VERSION ""

NS_ :

BS_:

BU_: APIM_CISM FCIMB RACM_RCIM DSP WCM DACMC HUD_ADV TRM_ITRM ACM GWM _delete APIM IPC GENERIC TSTR

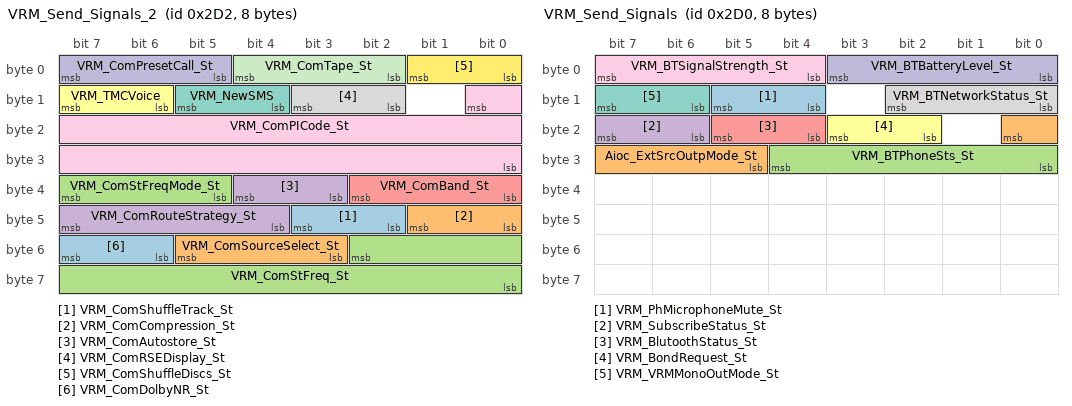
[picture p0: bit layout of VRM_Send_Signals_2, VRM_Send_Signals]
BO_ 722 VRM_Send_Signals_2: 8 APIM
 SG_ VRM_ComShuffleTrack_St : 43|2@0+ (1,0) [0|3] "SED"  GENERIC
 SG_ VRM_ComCompression_St : 41|2@0+ (1,0) [0|3] "SED"  GENERIC
 SG_ VRM_ComStFreqMode_St : 39|3@0+ (1,0) [0|7] "SED"  GENERIC
 SG_ VRM_ComAutostore_St : 36|2@0+ (1,0) [0|3] "SED"  GENERIC
 SG_ VRM_ComBand_St : 34|3@0+ (1,0) [0|7] "SED"  GENERIC
 SG_ VRM_TMCVoice : 15|2@0+ (1,0) [0|3] "SED"  GENERIC
 SG_ VRM_NewSMS : 13|2@0+ (1,0) [0|3] "SED"  HUD_ADV,IPC
 SG_ VRM_ComRSEDisplay_St : 11|2@0+ (1,0) [0|3] "SED"  GENERIC
 SG_ VRM_ComPICode_St : 8|17@0+ (1,0) [0|65535] "unitless"  GENERIC
 SG_ VRM_ComPresetCall_St : 7|3@0+ (1,0) [0|7] "SED"  GENERIC
 SG_ VRM_ComTape_St : 4|3@0+ (1,0) [0|7] "SED"  GENERIC
 SG_ VRM_ComShuffleDiscs_St : 1|2@0+ (1,0) [0|3] "SED"  GENERIC
 SG_ VRM_ComDolbyNR_St : 55|2@0+ (1,0) [0|3] "SED"  GENERIC
 SG_ VRM_ComSourceSelect_St : 53|3@0+ (1,0) [0|7] "SED"  GENERIC
 SG_ VRM_ComStFreq_St : 50|11@0+ (1,0) [0|1557] "unitless"  GENERIC
 SG_ VRM_ComRouteStrategy_St : 47|4@0+ (1,0) [0|15] "SED"  GENERIC

BO_ 721 VRM_Send_Signals_1: 8 APIM
 SG_ VRM_BTDefaultPhone_St : 63|4@0+ (1,0) [0|15] "SED"  IPC
 SG_ VRM_DetourUnit_st : 59|2@0+ (1,0) [0|3] "SED"  GENERIC
 SG_ VRM_Zoom_Option_St : 57|2@0+ (1,0) [0|3] "SED"  GENERIC
 SG_ VRM_ComBTDTMFTone_St : 55|4@0+ (1,0) [0|15] "SED"  GENERIC
 SG_ VRM_SuggestedRoute_St : 51|2@0+ (1,0) [0|3] "SED"  GENERIC
 SG_ VRM_ComDelWaypoint_St : 49|2@0+ (1,0) [0|3] "SED"  GENERIC
 SG_ VRM_ComSelectDisc_St : 47|3@0+ (1,0) [0|7] "SED"  GENERIC
 SG_ VRM_ComTelService_St : 44|3@0+ (1,0) [0|7] "SED"  GENERIC
 SG_ VRM_ComDestHome_St : 41|2@0+ (1,0) [0|3] "SED"  GENERIC
 SG_ VRM_ComSelectTrack_St : 39|7@0+ (1,0) [0|100] "unitless"  GENERIC
 SG_ VRM_ComShowNavInfo_St : 31|3@0+ (1,0) [0|7] "SED"  GENERIC
 SG_ VRM_VoiceRecStatus_St : 28|3@0+ (1,0) [0|7] "SED"  GENERIC
 SG_ VRM_ComSelTrackSource_St : 25|2@0+ (1,0) [0|3] "SED"  GENERIC
 SG_ VRM_ComDetour_St : 23|4@0+ (1,0) [0|15] "SED"  GENERIC
 SG_ VRM_ComDisplay_St : 19|3@0+ (1,0) [0|7] "SED"  GENERIC
 SG_ VRM_ComDynamicGuidande_St : 15|2@0+ (1,0) [0|3] "SED"  GENERIC
 SG_ VRM_ComZoom_St : 12|5@0+ (1,0) [0|31] "SED"  GENERIC
 SG_ VRM_ComCallControl_St : 7|3@0+ (1,0) [0|7] "SED"  GENERIC
 SG_ VRM_ComGuidance_St : 4|3@0+ (1,0) [0|7] "SED"  GENERIC
 SG_ VRM_ComTrafficInfDsp_St : 1|2@0+ (1,0) [0|3] "SED"  GENERIC

BO_ 720 VRM_Send_Signals: 8 APIM
 SG_ VRM_PhMicrophoneMute_St : 13|2@0+ (1,0) [0|3] "SED"  IPC
 SG_ Aioc_ExtSrcOutpMode_St : 16|4@0+ (1,0) [0|15] "SED"  GENERIC
 SG_ VRM_BTPhoneSts_St : 28|5@0+ (1,0) [0|31] "SED"  GWM,HUD_ADV,IPC
 SG_ VRM_SubscribeStatus_St : 23|2@0+ (1,0) [0|3] "SED"  GENERIC
 SG_ VRM_BlutoothStatus_St : 21|2@0+ (1,0) [0|3] "SED"  IPC
 SG_ VRM_BondRequest_St : 19|2@0+ (1,0) [0|3] "SED"  GENERIC
 SG_ VRM_VRMMonoOutMode_St : 15|2@0+ (1,0) [0|3] "SED"  GENERIC
 SG_ VRM_BTNetworkStatus_St : 10|3@0+ (1,0) [0|7] "unitless"  IPC
 SG_ VRM_BTSignalStrength_St : 7|4@0+ (1,0) [0|15] "unitless"  IPC
 SG_ VRM_BTBatteryLevel_St : 3|4@0+ (1,0) [0|15] "unitless"  IPC

BO_ 470 VRM_Response_Signals: 8 APIM
 SG_ VRM_BTIncomingCall_Rsp : 47|2@0+ (1,0) [0|3] "SED"  HUD_ADV,IPC
 SG_ VRM_BTEndTelService_Rsp : 37|2@0+ (1,0) [0|3] "SED"  HUD_ADV,IPC

BO_ 1978 TesterPhysicalResHUD_ADV: 8 HUD_ADV
 SG_ TesterPhysicalResHUD_ADV : 7|64@0+ (1,0) [0|1.84467E+019] "unitless"  TSTR

BO_ 1970 TesterPhysicalReqHUD_ADV: 8 TSTR
 SG_ TesterPhysicalReqHUD_ADV : 7|64@0+ (1,0) [0|1.84467E+019] "unitless"  HUD_ADV

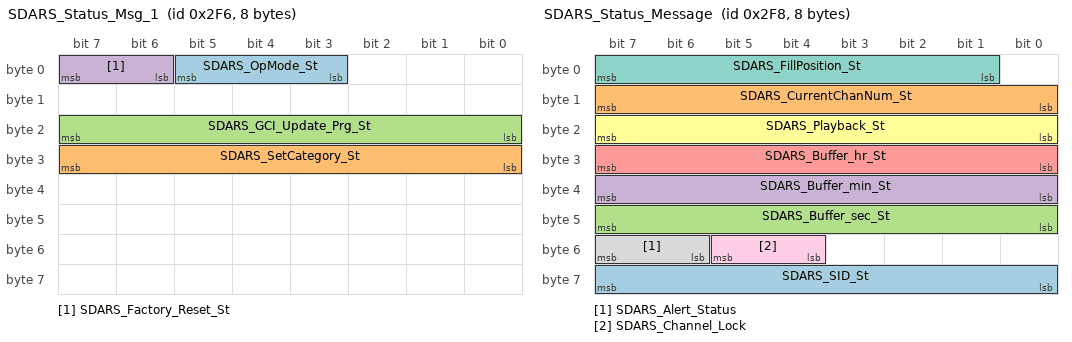
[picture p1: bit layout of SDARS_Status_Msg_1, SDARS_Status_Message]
BO_ 758 SDARS_Status_Msg_1: 8 ACM
 SG_ SDARS_OpMode_St : 5|3@0+ (1,0) [0|7] "SED"  APIM,IPC
 SG_ SDARS_SetCategory_St : 31|8@0+ (1,0) [0|255] "unitless"  APIM,IPC
 SG_ SDARS_GCI_Update_Prg_St : 23|8@0+ (1,0) [0|255] "unitless"  RACM_RCIM,APIM,IPC
 SG_ SDARS_Factory_Reset_St : 7|2@0+ (1,0) [0|3] "SED"  APIM,IPC

BO_ 760 SDARS_Status_Message: 8 ACM
 SG_ SDARS_SID_St : 63|8@0+ (1,0) [0|255] "unitless"  RACM_RCIM,APIM
 SG_ SDARS_CurrentChanNum_St : 15|8@0+ (1,0) [0|255] "unitless"  APIM,RACM_RCIM,IPC
 SG_ SDARS_Buffer_sec_St : 47|8@0+ (1,0) [0|255] "unitless"  APIM,IPC
 SG_ SDARS_Buffer_min_St : 39|8@0+ (1,0) [0|255] "unitless"  APIM,IPC
 SG_ SDARS_Buffer_hr_St : 31|8@0+ (1,0) [0|255] "unitless"  APIM,IPC
 SG_ SDARS_Playback_St : 23|8@0+ (1,0) [0|255] "unitless"  APIM,IPC
 SG_ SDARS_FillPosition_St : 7|7@0+ (1,0) [0|127] "unitless"  APIM,IPC
 SG_ SDARS_Alert_Status : 55|2@0+ (1,0) [0|3] "SED"  APIM,IPC
 SG_ SDARS_Channel_Lock : 53|2@0+ (1,0) [0|3] "SED"  RACM_RCIM,APIM,IPC

BO_ 705 SDARS_RDISP_WORD_Tx: 8 ACM
 SG_ SDARS_RDISP_WORD_Tx : 7|64@0+ (1,0) [0|1.84467440737096E+019] "unitless"  APIM

BO_ 692 AUDIO_RDISP_WORD_Tx: 8 ACM
 SG_ AUDIO_RDISP_WORD_Tx : 7|64@0+ (1,0) [0|1.84467440737096E+019] "unitless"  APIM

BO_ 1837 TesterPhysicalResWCM: 8 WCM
 SG_ TesterPhysicalResWCM : 7|64@0+ (1,0) [0|1.84467E+019] "unitless"  TSTR

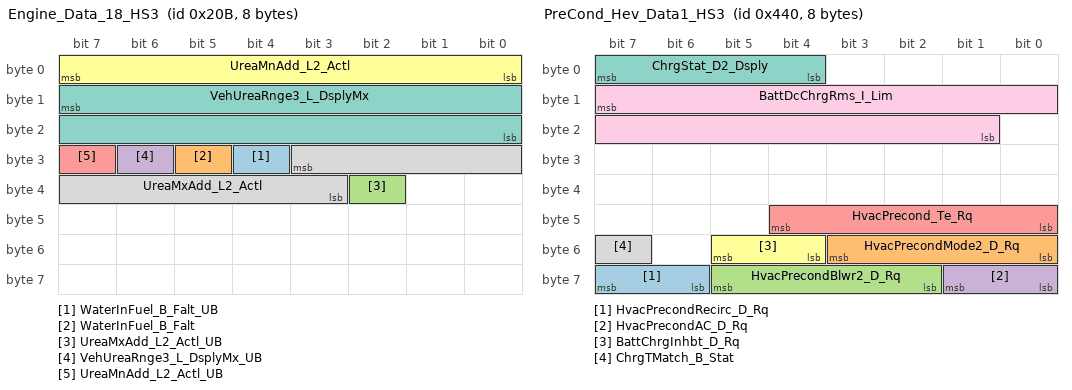
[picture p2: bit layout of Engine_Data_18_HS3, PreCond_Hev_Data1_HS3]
BO_ 523 Engine_Data_18_HS3: 8 GWM
 SG_ WaterInFuel_B_Falt_UB : 28|1@0+ (1,0) [0|1] "SED"  IPC
 SG_ WaterInFuel_B_Falt : 29|1@0+ (1,0) [0|1] "SED"  IPC
 SG_ UreaMxAdd_L2_Actl_UB : 34|1@0+ (1,0) [0|1] "SED"  IPC
 SG_ VehUreaRnge3_L_DsplyMx_UB : 30|1@0+ (1,0) [0|1] "SED"  IPC
 SG_ UreaMnAdd_L2_Actl_UB : 31|1@0+ (1,0) [0|1] "SED"  IPC
 SG_ UreaMnAdd_L2_Actl : 7|8@0+ (0.1,0) [0|25.4] "litre"  IPC
 SG_ VehUreaRnge3_L_DsplyMx : 15|16@0+ (1,0) [0|65535] "unitless"  IPC
 SG_ UreaMxAdd_L2_Actl : 27|9@0+ (0.1,0) [0|51] "litre"  IPC

BO_ 942 ParkAid_Data2_HS3: 8 GWM
 SG_ ApaDrvRq2MsgTxt_D_Rq : 55|4@0+ (1,0) [0|15] "SED"  APIM_CISM,APIM
 SG_ ApaDrvRq1MsgTxt_D_Rq : 42|3@0+ (1,0) [0|7] "SED"  APIM_CISM,APIM
 SG_ ApaSys_D2_Stat : 35|4@0+ (1,0) [0|15] "SED"  APIM_CISM,APIM
 SG_ ApaSlotTrgt_D_Stat : 39|4@0+ (1,0) [0|15] "SED"  APIM_CISM,APIM
 SG_ ApaSlotOption_B_Avail : 43|1@0+ (1,0) [0|1] "SED"  APIM_CISM,APIM
 SG_ ApaSlotAlrtSet_B_Stat : 44|1@0+ (1,0) [0|1] "SED"  APIM_CISM,APIM
 SG_ ApaSlotAlrt_B_Rq : 45|1@0+ (1,0) [0|1] "SED"  APIM_CISM,APIM
 SG_ ApaRmtFeatSel_B_Avail : 46|1@0+ (1,0) [0|1] "SED"  APIM_CISM,APIM
 SG_ ApaParkOutSel_B_Avail : 47|1@0+ (1,0) [0|1] "SED"  APIM_CISM,APIM
 SG_ ApaParkInSel_B_Avail : 24|1@0+ (1,0) [0|1] "SED"  APIM_CISM,APIM
 SG_ ApaMsgTxt_D2_Stat : 28|4@0+ (1,0) [0|15] "SED"  APIM_CISM,APIM
 SG_ ApaDynmcSlot_B_Stat : 29|1@0+ (1,0) [0|1] "SED"  APIM_CISM,APIM
 SG_ ApaDisplayMode_D_Stat : 31|2@0+ (1,0) [0|3] "SED"  APIM_CISM,APIM
 SG_ ApaControlMode_D_Stat : 16|1@0+ (1,0) [0|1] "SED"  APIM_CISM,APIM
 SG_ PrkAidAcsyRear_D_Stat : 18|2@0+ (1,0) [0|3] "SED"  APIM_CISM,IPC
 SG_ PrkAidAcsyFront_D_Stat : 20|2@0+ (1,0) [0|3] "SED"  APIM_CISM,IPC
 SG_ PrkAidRdiusRight_L_Dsply : 15|8@0+ (1,0) [0|255] "unitless"  APIM_CISM,APIM
 SG_ PrkAidRdiusLeft_L_Dsply : 7|8@0+ (1,0) [0|255] "unitless"  APIM_CISM,APIM
 SG_ PrkAidDrvDir_D_Stat : 23|3@0+ (1,0) [0|7] "SED"  APIM_CISM,APIM

BO_ 634 GWM_Send_Signals_7_HS3: 8 GWM
 SG_ EngAirFiltMsgTxt_D_Rq_UB : 56|1@0+ (1,0) [0|1] "SED"  IPC
 SG_ EngAirFiltMsgTxt_D_Rq : 59|3@0+ (1,0) [0|7] "SED"  IPC
 SG_ AutoHoldSwMde_B_Ind_UB : 62|1@0+ (1,0) [0|1] "SED"  APIM_CISM,APIM
 SG_ AutoHoldSwMde_B_Ind : 63|1@0+ (1,0) [0|1] "SED"  APIM_CISM,APIM
 SG_ Ccd_B_Falt_UB : 24|1@0+ (1,0) [0|1] "SED"  IPC
 SG_ Ccd_B_Falt : 25|1@0+ (1,0) [0|1] "SED"  IPC
 SG_ RearDiffLckLamp_D_Rq3_UB : 47|1@0+ (1,0) [0|1] "SED"  IPC
 SG_ AwdLckLamp_D_Rq_UB : 12|1@0+ (1,0) [0|1] "SED"  IPC
 SG_ RearDiffLckLamp_D_Rq3 : 61|2@0+ (1,0) [0|3] "SED"  IPC
 SG_ AwdLckLamp_D_Rq : 14|2@0+ (1,0) [0|3] "SED"  IPC
 SG_ AutoTowAllw_D_StatMnu_UB : 26|1@0+ (1,0) [0|1] "SED"  IPC
 SG_ AutoTowAllw_D_StatMnu : 28|2@0+ (1,0) [0|3] "SED"  IPC
 SG_ AutoTowActv_B_Stat : 30|1@0+ (1,0) [0|1] "SED"  DACMC,IPC
 SG_ AutoTowActv_B_Stat_UB : 29|1@0+ (1,0) [0|1] "SED"  IPC
 SG_ LdwChime_B_Rq_UB : 5|1@0+ (1,0) [0|1] "SED"  IPC
 SG_ HdcOn_B_Ind : 7|1@0+ (1,0) [0|1] "SED"  IPC
 SG_ HdcOn_B_Ind_UB : 6|1@0+ (1,0) [0|1] "SED"  IPC
 SG_ SuspVLimMsgTxt_B_Rq_UB : 4|1@0+ (1,0) [0|1] "SED"  IPC
 SG_ SuspVlimMsgTxt_B_Rq : 31|1@0+ (1,0) [0|1] "SED"  IPC
 SG_ EngExhMdeQuiet_D2_Stat_UB : 0|1@0+ (1,0) [0|1] "SED"  APIM_CISM,APIM,IPC,ACM
 SG_ EngExhMdeQuiet_D2_Stat : 3|3@0+ (1,0) [0|7] "SED"  APIM_CISM,APIM,IPC,ACM
 SG_ ChrgCrdLck_D_Falt_UB : 44|1@0+ (1,0) [0|1] "SED"  APIM_CISM,APIM,IPC
 SG_ LdwChime_B_Rq : 15|1@0+ (1,0) [0|1] "SED"  IPC
 SG_ ChrgCrdLck_D_Falt : 46|2@0+ (1,0) [0|3] "SED"  APIM_CISM,APIM,IPC

BO_ 1088 PreCond_Hev_Data1_HS3: 8 GWM
 SG_ HvacPrecondRecirc_D_Rq : 63|2@0+ (1,0) [0|3] "SED"  GENERIC
 SG_ HvacPrecondMode2_D_Rq : 51|4@0+ (1,0) [0|15] "SED"  GENERIC
 SG_ HvacPrecondBlwr2_D_Rq : 61|4@0+ (1,0) [0|15] "SED"  GENERIC
 SG_ HvacPrecondAC_D_Rq : 57|2@0+ (1,0) [0|3] "SED"  GENERIC
 SG_ HvacPrecond_Te_Rq : 44|5@0+ (0.5,14.5) [14.5|30] "deg C"  GENERIC
 SG_ BattChrgInhbt_D_Rq : 53|2@0+ (1,0) [0|3] "SED"  GENERIC
 SG_ ChrgStat_D2_Dsply : 7|4@0+ (1,0) [0|15] "SED"  APIM_CISM,APIM,IPC
 SG_ ChrgTMatch_B_Stat : 55|1@0+ (1,0) [0|1] "SED"  IPC
 SG_ BattDcChrgRms_I_Lim : 15|15@0+ (0.05,0) [0|1638.25] "ampere"  GENERIC

BO_ 706 SDARS_MC_WORD_Tx: 8 ACM
 SG_ SDARS_MC_WORD_Tx : 7|64@0+ (1,0) [0|1.84467440737096E+019] "unitless"  IPC

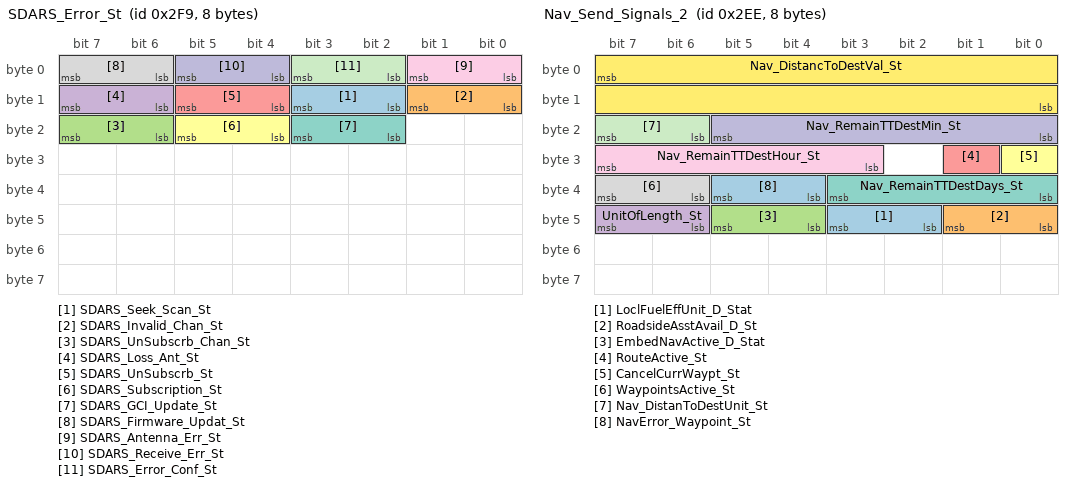
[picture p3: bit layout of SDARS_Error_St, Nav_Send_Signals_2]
BO_ 761 SDARS_Error_St: 8 ACM
 SG_ SDARS_Seek_Scan_St : 11|2@0+ (1,0) [0|3] "SED"  RACM_RCIM,APIM,IPC
 SG_ SDARS_Invalid_Chan_St : 9|2@0+ (1,0) [0|3] "SED"  RACM_RCIM,APIM,IPC
 SG_ SDARS_UnSubscrb_Chan_St : 23|2@0+ (1,0) [0|3] "SED"  RACM_RCIM,APIM,IPC
 SG_ SDARS_Loss_Ant_St : 15|2@0+ (1,0) [0|3] "SED"  APIM,RACM_RCIM,IPC
 SG_ SDARS_UnSubscrb_St : 13|2@0+ (1,0) [0|3] "SED"  RACM_RCIM,APIM,IPC
 SG_ SDARS_Subscription_St : 21|2@0+ (1,0) [0|3] "SED"  RACM_RCIM,APIM,IPC
 SG_ SDARS_GCI_Update_St : 19|2@0+ (1,0) [0|3] "SED"  RACM_RCIM,APIM,IPC
 SG_ SDARS_Firmware_Updat_St : 7|2@0+ (1,0) [0|3] "SED"  RACM_RCIM,APIM,IPC
 SG_ SDARS_Antenna_Err_St : 1|2@0+ (1,0) [0|3] "SED"  RACM_RCIM,APIM,IPC
 SG_ SDARS_Receive_Err_St : 5|2@0+ (1,0) [0|3] "SED"  RACM_RCIM,APIM,IPC
 SG_ SDARS_Error_Conf_St : 3|2@0+ (1,0) [0|3] "SED"  RACM_RCIM,APIM,IPC

BO_ 694 PHONE_MC_WORD_Tx: 8 APIM
 SG_ PHONE_MC_WORD_Tx : 7|64@0+ (1,0) [0|1.84467440737096E+019] "unitless"  IPC

BO_ 750 Nav_Send_Signals_2: 8 APIM
 SG_ LoclFuelEffUnit_D_Stat : 43|2@0+ (1,0) [0|3] "SED"  IPC
 SG_ RoadsideAsstAvail_D_St : 41|2@0+ (1,0) [0|3] "SED"  IPC
 SG_ EmbedNavActive_D_Stat : 45|2@0+ (1,0) [0|3] "SED"  IPC
 SG_ UnitOfLength_St : 47|2@0+ (1,0) [0|3] "SED"  IPC
 SG_ RouteActive_St : 25|1@0+ (1,0) [0|1] "SED"  HUD_ADV,IPC
 SG_ CancelCurrWaypt_St : 24|1@0+ (1,0) [0|1] "SED"  IPC
 SG_ Nav_RemainTTDestDays_St : 35|4@0+ (1,0) [0|14] "day"  HUD_ADV,IPC
 SG_ WaypointsActive_St : 39|2@0+ (1,0) [0|3] "SED"  IPC
 SG_ Nav_RemainTTDestHour_St : 31|5@0+ (1,0) [0|31] "hour"  HUD_ADV,IPC
 SG_ Nav_RemainTTDestMin_St : 21|6@0+ (1,0) [0|63] "minute"  HUD_ADV,IPC
 SG_ Nav_DistanToDestUnit_St : 23|2@0+ (1,0) [0|3] "SED"  HUD_ADV,IPC
 SG_ Nav_DistancToDestVal_St : 7|16@0+ (1,0) [0|65534] "unitless"  HUD_ADV,IPC
 SG_ NavError_Waypoint_St : 37|2@0+ (1,0) [0|3] "SED"  HUD_ADV,IPC

BO_ 704 NAV_MC_WORD_Tx: 8 APIM
 SG_ NAV_MC_WORD_Tx : 7|64@0+ (1,0) [0|1.84467440737096E+019] "unitless"  IPC

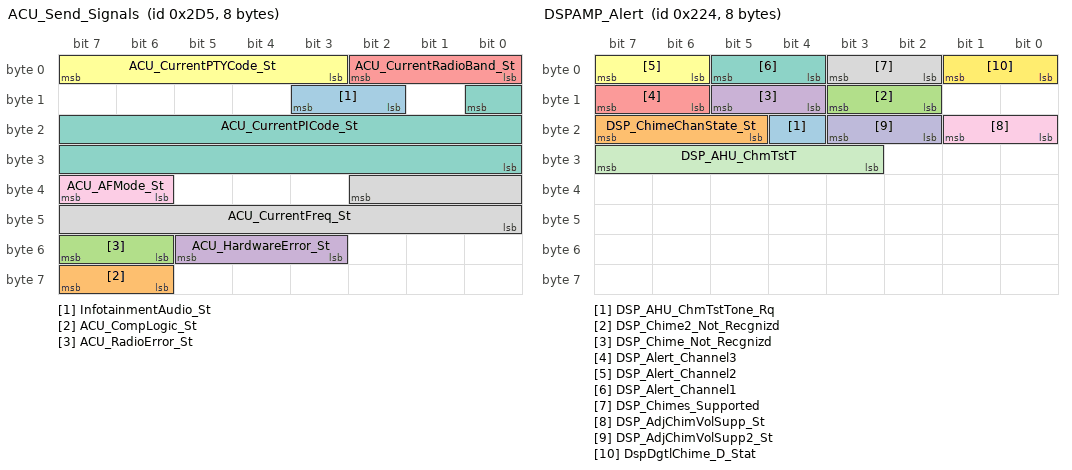
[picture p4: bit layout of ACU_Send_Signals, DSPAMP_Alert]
BO_ 725 ACU_Send_Signals: 8 ACM
 SG_ InfotainmentAudio_St : 11|2@0+ (1,0) [0|3] "SED"  GWM,APIM,DSP
 SG_ ACU_CompLogic_St : 63|2@0+ (1,0) [0|3] "SED"  GWM,GENERIC
 SG_ ACU_RadioError_St : 55|2@0+ (1,0) [0|3] "SED"  RACM_RCIM,GWM,APIM,IPC
 SG_ ACU_HardwareError_St : 53|3@0+ (1,0) [0|7] "SED"  RACM_RCIM,GWM,APIM,IPC
 SG_ ACU_CurrentRadioBand_St : 2|3@0+ (1,0) [0|7] "SED"  GWM,IPC
 SG_ ACU_CurrentPTYCode_St : 7|5@0+ (1,0) [0|31] "unitless"  RACM_RCIM,GWM,APIM,IPC
 SG_ ACU_CurrentPICode_St : 8|17@0+ (1,0) [0|65535] "unitless"  RACM_RCIM,GWM,APIM
 SG_ ACU_CurrentFreq_St : 34|11@0+ (1,0) [0|1557] "unitless"  RACM_RCIM,GWM,APIM,WCM,IPC,DSP
 SG_ ACU_AFMode_St : 39|2@0+ (1,0) [0|3] "SED"  GWM,APIM

BO_ 1074 BodyEngGateway_2_HS3: 8 GWM
 SG_ PwLftgtIntSw_B_Stat_UB : 14|1@0+ (1,0) [0|1] "SED"  APIM
 SG_ PwLftgtIntSw_B_Stat : 15|1@0+ (1,0) [0|1] "SED"  APIM
 SG_ E_Frt_Btn_Status_1st_UB : 0|1@0+ (1,0) [0|1] "SED"  APIM_CISM,APIM
 SG_ E_Frt_Btn_Status_2nd_UB : 1|1@0+ (1,0) [0|1] "SED"  APIM_CISM,APIM
 SG_ E_Frt_Btn_Status_2nd : 39|6@0+ (1,0) [0|63] "SED"  APIM_CISM,APIM
 SG_ E_Frt_Btn_Status_1st : 7|6@0+ (1,0) [0|63] "SED"  APIM_CISM,APIM
 SG_ DrLatchRrMsgTxt_D_Rq_UB : 28|1@0+ (1,0) [0|1] "SED"  IPC
 SG_ DrLatchRrMsgTxt_D_Rq : 31|3@0+ (1,0) [0|7] "SED"  IPC
 SG_ DrLatchRlMsgTxt_D_Rq_UB : 16|1@0+ (1,0) [0|1] "SED"  IPC
 SG_ DrLatchRlMsgTxt_D_Rq : 19|3@0+ (1,0) [0|7] "SED"  IPC
 SG_ DrLatchFrMsgTxt_D_Rq_UB : 20|1@0+ (1,0) [0|1] "SED"  IPC
 SG_ DrLatchFrMsgTxt_D_Rq : 23|3@0+ (1,0) [0|7] "SED"  IPC
 SG_ DrLatchFlMsgTxt_D_Rq_UB : 8|1@0+ (1,0) [0|1] "SED"  IPC
 SG_ DrLatchFlMsgTxt_D_Rq : 11|3@0+ (1,0) [0|7] "SED"  IPC
 SG_ TrlrTireThresh_D_Stat_UB : 41|1@0+ (1,0) [0|1] "SED"  IPC
 SG_ TrlrTireThresh_D_Stat : 55|8@0+ (1,0) [0|255] "unitless"  IPC
 SG_ TrlrTireSys_D_Stat_UB : 40|1@0+ (1,0) [0|1] "SED"  IPC
 SG_ TrlrTireSys_D_Stat : 63|4@0+ (1,0) [0|15] "SED"  IPC
 SG_ TrlrTireCnt_D_Stat_UB : 56|1@0+ (1,0) [0|1] "SED"  IPC
 SG_ TrlrTireCnt_D_Stat : 59|3@0+ (1,0) [0|6] "SED"  IPC
 SG_ BrkMdeInhbt_B_RqDsply_UB : 42|1@0+ (1,0) [0|1] "SED"  IPC
 SG_ BrkMdeInhbt_B_RqDsply : 43|1@0+ (1,0) [0|1] "SED"  IPC

BO_ 1014 WCM_Send_Signals: 8 WCM
 SG_ WrlssAcsyChrg_Pc_Actl : 15|7@0+ (1,0) [0|125] "percent"  APIM_CISM,APIM
 SG_ WrlssAcsyChrgr_D_Stat : 7|3@0+ (1,0) [0|7] "SED"  APIM_CISM,APIM

BO_ 548 DSPAMP_Alert: 8 DSP
 SG_ DSP_AHU_ChmTstTone_Rq : 20|1@0+ (1,0) [0|1] "SED"  APIM_CISM,ACM
 SG_ DSP_ChimeChanState_St : 23|3@0+ (1,0) [0|7] "SED"  APIM_CISM,ACM
 SG_ DSP_Chime2_Not_Recgnizd : 11|2@0+ (1,0) [0|3] "SED"  IPC
 SG_ DSP_Chime_Not_Recgnizd : 13|2@0+ (1,0) [0|3] "SED"  IPC
 SG_ DSP_Alert_Channel3 : 15|2@0+ (1,0) [0|3] "SED"  RACM_RCIM,APIM_CISM,APIM,IPC
 SG_ DSP_Alert_Channel2 : 7|2@0+ (1,0) [0|3] "SED"  APIM_CISM,ACM,IPC
 SG_ DSP_Alert_Channel1 : 5|2@0+ (1,0) [0|3] "SED"  APIM_CISM,ACM
 SG_ DSP_Chimes_Supported : 3|2@0+ (1,0) [0|3] "SED"  APIM_CISM,ACM,IPC
 SG_ DSP_AdjChimVolSupp_St : 17|2@0+ (1,0) [0|4] "SED"  ACM
 SG_ DSP_AdjChimVolSupp2_St : 19|2@0+ (1,0) [0|4] "SED"  ACM
 SG_ DSP_AHU_ChmTstT : 31|5@0+ (1,0) [0|15] "SED"  APIM_CISM,ACM
 SG_ DspDgtlChime_D_Stat : 1|2@0+ (1,0) [0|3] "SED"  APIM_CISM,ACM

BO_ 404 Dsp_Response_Signals: 8 APIM
 SG_ Dsp_LangUpdate_Rsp : 7|2@0+ (1,0) [0|3] "SED"  IPC

BO_ 689 AUDIO_MC_WORD_Tx: 8 ACM
 SG_ AUDIO_MC_WORD_Tx : 7|64@0+ (1,0) [0|1.84467440737096E+019] "unitless"  IPC

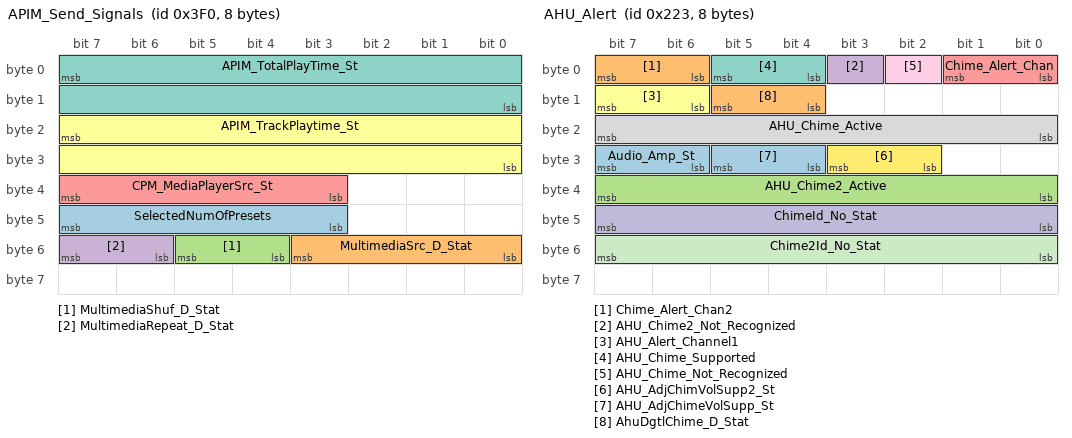
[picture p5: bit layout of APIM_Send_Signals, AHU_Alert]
BO_ 1008 APIM_Send_Signals: 8 APIM
 SG_ SelectedNumOfPresets : 47|5@0+ (1,0) [0|31] "SED"  RACM_RCIM,IPC,ACM
 SG_ MultimediaSrc_D_Stat : 51|4@0+ (1,0) [0|15] "SED"  RACM_RCIM
 SG_ MultimediaShuf_D_Stat : 53|2@0+ (1,0) [0|2] "SED"  RACM_RCIM
 SG_ MultimediaRepeat_D_Stat : 55|2@0+ (1,0) [0|3] "SED"  RACM_RCIM
 SG_ CPM_MediaPlayerSrc_St : 39|5@0+ (1,0) [0|31] "SED"  GENERIC
 SG_ APIM_TrackPlaytime_St : 23|16@0+ (1,-100) [-100|65434] "second"  RACM_RCIM,IPC
 SG_ APIM_TotalPlayTime_St : 7|16@0+ (1,-100) [-100|65434] "second"  RACM_RCIM,IPC

BO_ 547 AHU_Alert: 8 ACM
 SG_ Audio_Amp_St : 31|2@0+ (1,0) [0|3] "SED"  GENERIC
 SG_ Chime_Alert_Chan2 : 7|2@0+ (1,0) [0|3] "SED"  DSP,IPC
 SG_ AHU_Chime2_Active : 39|8@0+ (1,0) [0|255] "SED"  DSP,IPC
 SG_ AHU_Chime2_Not_Recognized : 3|1@0+ (1,0) [0|1] "SED"  IPC
 SG_ Chime_Alert_Chan : 1|2@0+ (1,0) [0|3] "SED"  DSP,IPC
 SG_ AHU_Alert_Channel1 : 15|2@0+ (1,0) [0|3] "SED"  RACM_RCIM,APIM
 SG_ AHU_Chime_Supported : 5|2@0+ (1,0) [0|3] "SED"  APIM,IPC
 SG_ AHU_Chime_Active : 23|8@0+ (1,0) [0|255] "SED"  DSP,IPC
 SG_ AHU_Chime_Not_Recognized : 2|1@0+ (1,0) [0|1] "SED"  IPC
 SG_ ChimeId_No_Stat : 47|8@0+ (1,0) [0|255] "SED"  IPC
 SG_ Chime2Id_No_Stat : 55|8@0+ (1,0) [0|255] "SED"  IPC
 SG_ AHU_AdjChimVolSupp2_St : 27|2@0+ (1,0) [0|4] "SED"  IPC
 SG_ AHU_AdjChimeVolSupp_St : 29|2@0+ (1,0) [0|4] "SED"  IPC
 SG_ AhuDgtlChime_D_Stat : 13|2@0+ (1,0) [0|3] "SED"  DSP

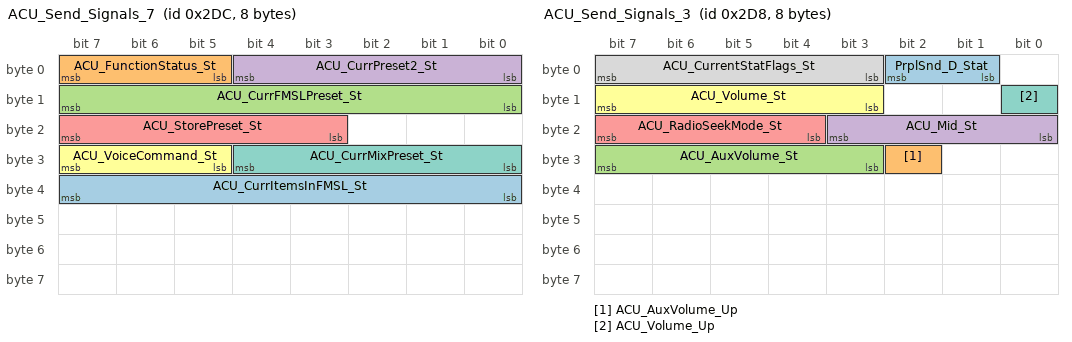
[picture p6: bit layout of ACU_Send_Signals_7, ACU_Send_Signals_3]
BO_ 732 ACU_Send_Signals_7: 8 ACM
 SG_ ACU_CurrItemsInFMSL_St : 39|8@0+ (1,0) [0|255] "unitless"  APIM
 SG_ ACU_FunctionStatus_St : 7|3@0+ (1,0) [0|7] "SED"  RACM_RCIM,APIM,IPC
 SG_ ACU_CurrFMSLPreset_St : 15|8@0+ (1,0) [0|255] "unitless"  APIM
 SG_ ACU_CurrPreset2_St : 4|5@0+ (1,0) [0|31] "unitless"  RACM_RCIM,APIM,IPC
 SG_ ACU_StorePreset_St : 23|5@0+ (1,0) [0|31] "SED"  APIM,IPC
 SG_ ACU_VoiceCommand_St : 31|3@0+ (1,0) [0|7] "SED" Vector__XXX
 SG_ ACU_CurrMixPreset_St : 28|5@0+ (1,0) [0|31] "unitless"  APIM

BO_ 728 ACU_Send_Signals_3: 8 ACM
 SG_ PrplSnd_D_Stat : 2|2@0+ (1,0) [0|3] "SED"  APIM
 SG_ ACU_AuxVolume_Up : 26|1@0+ (1,0) [0|1] "SED"  IPC
 SG_ ACU_AuxVolume_St : 31|5@0+ (1,0) [0|31] "unitless"  IPC
 SG_ ACU_Mid_St : 19|4@0+ (1,-7) [-7|8] "unitless"  APIM
 SG_ ACU_RadioSeekMode_St : 23|4@0+ (1,0) [0|15] "SED"  APIM,IPC
 SG_ ACU_Volume_St : 15|5@0+ (1,0) [0|30] "unitless"  HUD_ADV,GWM,RACM_RCIM,WCM,APIM,IPC
 SG_ ACU_Volume_Up : 8|1@0+ (1,0) [0|1] "SED"  RACM_RCIM,APIM,IPC
 SG_ ACU_CurrentStatFlags_St : 7|5@0+ (1,0) [0|31] "unitless"  RACM_RCIM,APIM,IPC

BO_ 489 ACU_Send_Signals_1: 8 ACM
 SG_ ACU_CurrentPSName_St : 7|64@0+ (1,0) [0|1.8446744074E+019] "unitless"  RACM_RCIM,APIM,IPC

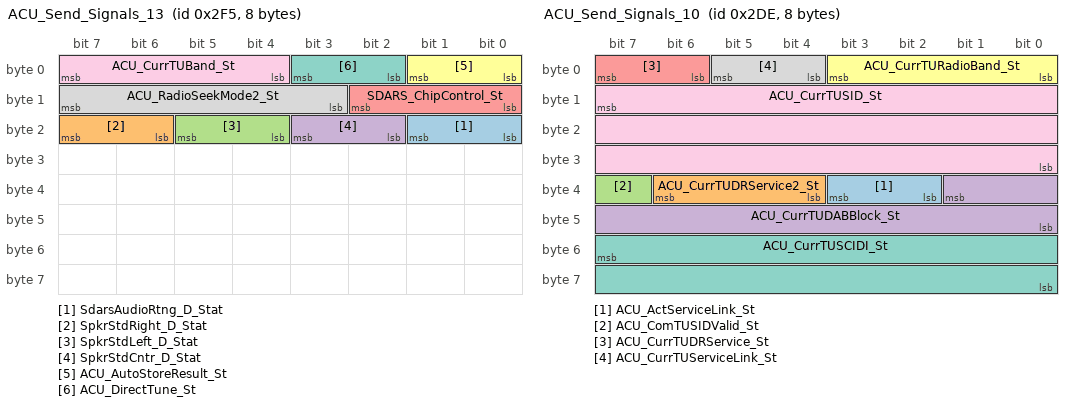
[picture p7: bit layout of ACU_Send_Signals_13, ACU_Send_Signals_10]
BO_ 757 ACU_Send_Signals_13: 8 ACM
 SG_ SdarsAudioRtng_D_Stat : 17|2@0+ (1,0) [0|3] "SED"  APIM_CISM,APIM,GWM
 SG_ SpkrStdRight_D_Stat : 23|2@0+ (1,0) [0|3] "SED"  DSP,GWM
 SG_ SpkrStdLeft_D_Stat : 21|2@0+ (1,0) [0|3] "SED"  DSP,GWM
 SG_ SpkrStdCntr_D_Stat : 19|2@0+ (1,0) [0|3] "SED"  DSP,GWM
 SG_ SDARS_ChipControl_St : 10|3@0+ (1,0) [0|7] "SED"  GWM,APIM
 SG_ ACU_AutoStoreResult_St : 1|2@0+ (1,0) [0|3] "SED"  RACM_RCIM,GWM,APIM,IPC
 SG_ ACU_DirectTune_St : 3|2@0+ (1,0) [0|3] "SED"  GWM,APIM,IPC
 SG_ ACU_RadioSeekMode2_St : 15|5@0+ (1,0) [0|31] "SED"  RACM_RCIM,GWM,APIM,WCM,IPC
 SG_ ACU_CurrTUBand_St : 7|4@0+ (1,0) [0|15] "SED"  DSP,RACM_RCIM,GWM,APIM,WCM,IPC

BO_ 734 ACU_Send_Signals_10: 8 ACM
 SG_ ACU_ActServiceLink_St : 35|2@0+ (1,0) [0|3] "SED"  RACM_RCIM,APIM
 SG_ ACU_CurrTUDRService2_St : 38|3@0+ (1,0) [0|7] "SED"  RACM_RCIM,APIM,IPC
 SG_ ACU_ComTUSIDValid_St : 39|1@0+ (1,0) [0|1] "SED"  APIM
 SG_ ACU_CurrTUDABBlock_St : 33|10@0+ (1,0) [0|1023] "SED"  RACM_RCIM,APIM,IPC
 SG_ ACU_CurrTUDRService_St : 7|2@0+ (1,0) [0|3] "SED"  APIM
 SG_ ACU_CurrTURadioBand_St : 3|4@0+ (1,0) [0|15] "SED" Vector__XXX
 SG_ ACU_CurrTUSCIDI_St : 55|16@0+ (1,0) [0|65535] "unitless"  RACM_RCIM,APIM
 SG_ ACU_CurrTUServiceLink_St : 5|2@0+ (1,0) [0|3] "SED"  RACM_RCIM,APIM
 SG_ ACU_CurrTUSID_St : 15|24@0+ (1,0) [0|16777215] "unitless"  RACM_RCIM,APIM

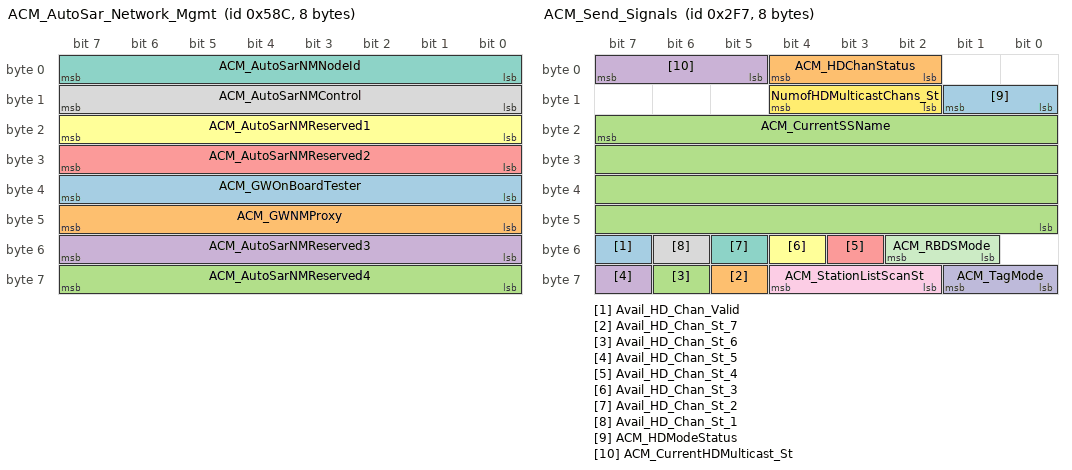
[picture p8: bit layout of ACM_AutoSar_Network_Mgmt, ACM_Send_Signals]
BO_ 1420 ACM_AutoSar_Network_Mgmt: 8 ACM
 SG_ ACM_GWOnBoardTester : 39|8@0+ (1,0) [0|255] "unitless"  GWM
 SG_ ACM_GWNMProxy : 47|8@0+ (1,0) [0|255] "unitless"  GWM
 SG_ ACM_AutoSarNMReserved4 : 63|8@0+ (1,0) [0|255] "unitless"  GWM
 SG_ ACM_AutoSarNMReserved3 : 55|8@0+ (1,0) [0|255] "unitless"  GWM
 SG_ ACM_AutoSarNMReserved2 : 31|8@0+ (1,0) [0|255] "unitless"  GWM
 SG_ ACM_AutoSarNMReserved1 : 23|8@0+ (1,0) [0|255] "unitless"  GWM
 SG_ ACM_AutoSarNMNodeId : 7|8@0+ (1,0) [0|255] "unitless"  GWM
 SG_ ACM_AutoSarNMControl : 15|8@0+ (1,0) [0|255] "unitless"  GWM

BO_ 759 ACM_Send_Signals: 8 ACM
 SG_ Avail_HD_Chan_Valid : 55|1@0+ (1,0) [0|1] "SED"  APIM,RACM_RCIM
 SG_ Avail_HD_Chan_St_7 : 61|1@0+ (1,0) [0|1] "SED"  APIM,RACM_RCIM
 SG_ Avail_HD_Chan_St_6 : 62|1@0+ (1,0) [0|1] "SED"  APIM,RACM_RCIM
 SG_ Avail_HD_Chan_St_5 : 63|1@0+ (1,0) [0|1] "SED"  APIM,RACM_RCIM
 SG_ Avail_HD_Chan_St_4 : 51|1@0+ (1,0) [0|1] "SED"  APIM,RACM_RCIM
 SG_ Avail_HD_Chan_St_3 : 52|1@0+ (1,0) [0|1] "SED"  APIM,RACM_RCIM
 SG_ Avail_HD_Chan_St_2 : 53|1@0+ (1,0) [0|1] "SED"  APIM,RACM_RCIM
 SG_ Avail_HD_Chan_St_1 : 54|1@0+ (1,0) [0|1] "SED"  APIM,RACM_RCIM
 SG_ ACM_StationListScanSt : 60|3@0+ (1,0) [0|7] "SED"  APIM,IPC
 SG_ ACM_TagMode : 57|2@0+ (1,0) [0|3] "SED"  APIM,IPC
 SG_ ACM_RBDSMode : 50|2@0+ (1,0) [0|3] "SED"  RACM_RCIM,APIM,IPC
 SG_ NumofHDMulticastChans_St : 12|3@0+ (1,0) [0|7] "SED"  RACM_RCIM,APIM,IPC
 SG_ ACM_HDModeStatus : 9|2@0+ (1,0) [0|3] "SED"  RACM_RCIM,APIM,IPC
 SG_ ACM_HDChanStatus : 4|3@0+ (1,0) [0|7] "SED"  RACM_RCIM,APIM,IPC,DSP
 SG_ ACM_CurrentSSName : 23|32@0+ (1,0) [0|4294967295] "unitless"  RACM_RCIM,APIM,IPC
 SG_ ACM_CurrentHDMulticast_St : 7|3@0+ (1,0) [0|7] "SED"  RACM_RCIM,APIM,IPC

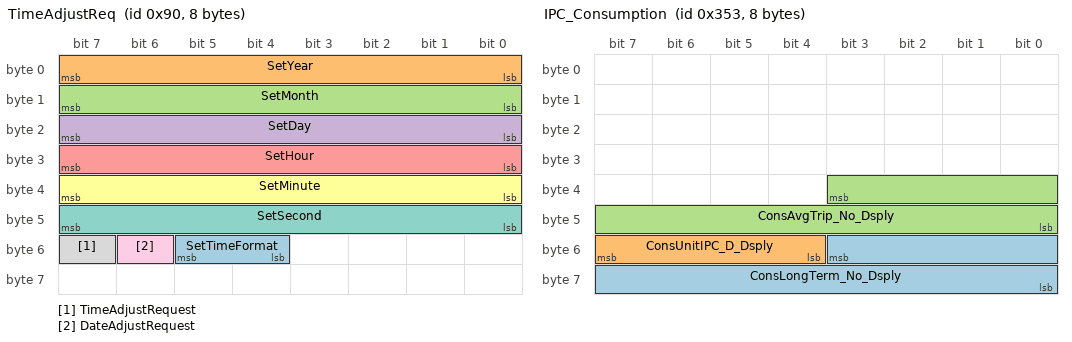
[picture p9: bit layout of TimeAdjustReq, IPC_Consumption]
BO_ 144 TimeAdjustReq: 8 APIM
 SG_ SetTimeFormat : 53|2@0+ (1,0) [0|3] "unitless"  GENERIC
 SG_ SetYear : 7|8@0+ (1,2000) [2000|2254] "year"  GENERIC
 SG_ SetMonth : 15|8@0+ (1,0) [0|12] "month"  GENERIC
 SG_ SetDay : 23|8@0+ (1,0) [0|31] "day"  GENERIC
 SG_ SetHour : 31|8@0+ (1,0) [0|23] "hour"  GENERIC
 SG_ SetMinute : 39|8@0+ (1,0) [0|59] "minute"  GENERIC
 SG_ SetSecond : 47|8@0+ (1,0) [0|59] "second"  GENERIC
 SG_ TimeAdjustRequest : 55|1@0+ (1,0) [0|1] "SED"  GENERIC
 SG_ DateAdjustRequest : 54|1@0+ (1,0) [0|1] "SED"  IPC,GENERIC

BO_ 851 IPC_Consumption: 8 IPC
 SG_ ConsLongTerm_No_Dsply : 51|12@0+ (1,0) [0|4093] "%"  APIM_CISM,GWM
 SG_ ConsUnitIPC_D_Dsply : 55|4@0+ (1,0) [0|15] "SED"  APIM_CISM,GWM,APIM
 SG_ ConsAvgTrip_No_Dsply : 35|12@0+ (1,0) [0|4093] "%"  APIM_CISM,GWM

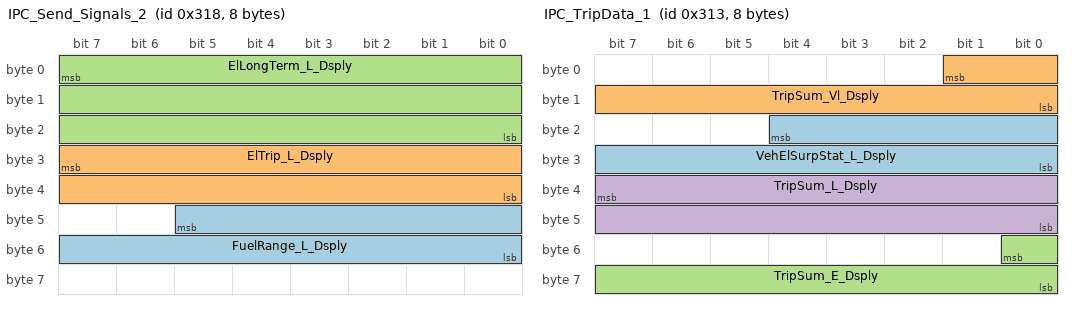
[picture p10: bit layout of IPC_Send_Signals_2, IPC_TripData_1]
BO_ 792 IPC_Send_Signals_2: 8 IPC
 SG_ FuelRange_L_Dsply : 45|14@0+ (0.1,0) [0|1638.3] "km"  APIM_CISM,HUD_ADV,GWM,ACM,APIM
 SG_ ElTrip_L_Dsply : 31|16@0+ (0.1,0) [0|6553.3] "unitless"  GWM
 SG_ ElLongTerm_L_Dsply : 7|24@0+ (0.1,0) [0|1677721.3] "unitless"  GWM

BO_ 787 IPC_TripData_1: 8 IPC
 SG_ VehElSurpStat_L_Dsply : 20|13@0+ (0.1,-409.4) [-409.4|409.5] "Km"  GENERIC,GWM
 SG_ TripSum_Vl_Dsply : 1|10@0+ (0.1,0) [0|102.3] "Liters"  GWM
 SG_ TripSum_E_Dsply : 48|9@0+ (0.1,0) [0|50.9] "kw*hrs"  GWM
 SG_ TripSum_L_Dsply : 39|16@0+ (0.1,0) [0|6553.3] "Km"  GWM

BO_ 697 AUDIO_MC_WORD_Rx: 8 IPC
 SG_ AUDIO_MC_WORD_Rx : 7|64@0+ (1,0) [0|1.84467440737096E+019] "unitless"  APIM_CISM,ACM

BO_ 700 AUDIO_RDISP_WORD_Rx: 8 APIM
 SG_ AUDIO_RDISP_WORD_Rx : 7|64@0+ (1,0) [0|1.84467440737096E+019] "unitless"  ACM

BO_ 676 MC_RDISP_WORD_Tx: 8 IPC
 SG_ MC_RDISP_WORD_Tx : 7|64@0+ (1,0) [0|1.84467440737096E+019] "unitless"  APIM_CISM,APIM

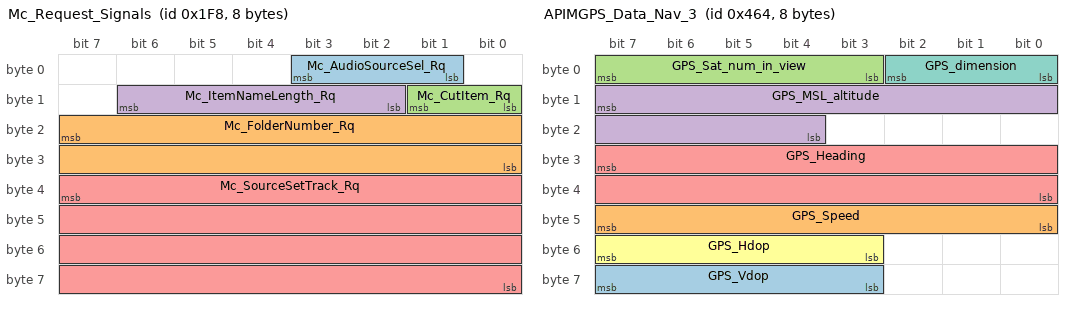
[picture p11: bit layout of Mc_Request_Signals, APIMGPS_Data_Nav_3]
BO_ 504 Mc_Request_Signals: 8 IPC
 SG_ Mc_AudioSourceSel_Rq : 3|3@0+ (1,0) [0|7] "SED"  ACM
 SG_ Mc_FolderNumber_Rq : 23|16@0+ (1,0) [0|65535] "unitless"  ACM
 SG_ Mc_CutItem_Rq : 9|2@0+ (1,0) [0|3] "SED"  ACM
 SG_ Mc_ItemNameLength_Rq : 14|5@0+ (1,0) [0|20] "SED"  ACM
 SG_ Mc_SourceSetTrack_Rq : 39|32@0+ (1,0) [0|4294967295] "unitless"  ACM

BO_ 410 Mc_Send_Signals_3: 8 IPC
 SG_ MyKey_e911Override_St : 39|2@0+ (1,0) [0|3] "SED"  APIM_CISM,APIM
 SG_ DoNotDisturbOveride_St : 26|2@0+ (1,0) [0|3] "SED"  APIM_CISM,APIM

BO_ 1124 APIMGPS_Data_Nav_3: 8 APIM
 SG_ GPS_Vdop : 63|5@0+ (0.2,0) [0|5.8] "unitless"  GWM
 SG_ GPS_Speed : 47|8@0+ (1,0) [0|253] "MPH"  GWM
 SG_ GPS_Sat_num_in_view : 7|5@0+ (1,0) [0|29] "unitless"  GWM
 SG_ GPS_MSL_altitude : 15|12@0+ (10,-20460) [-20460|20470] "feet"  GWM
 SG_ GPS_Heading : 31|16@0+ (0.01,0) [0|655.33] "Degrees"  GWM
 SG_ GPS_Hdop : 55|5@0+ (0.2,0) [0|5.8] "unitless"  GWM
 SG_ GPS_dimension : 2|3@0+ (1,0) [0|7] "SED"  GWM

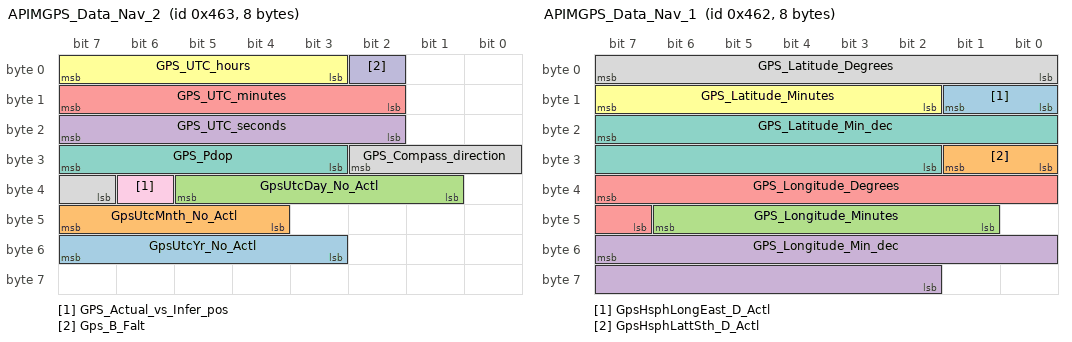
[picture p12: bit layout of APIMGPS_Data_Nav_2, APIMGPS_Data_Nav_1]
BO_ 1123 APIMGPS_Data_Nav_2: 8 APIM
 SG_ GpsUtcYr_No_Actl : 55|5@0+ (1,2010) [2010|2040] "Year"  GWM
 SG_ GpsUtcMnth_No_Actl : 47|4@0+ (1,1) [1|15] "Month"  GWM
 SG_ GpsUtcDay_No_Actl : 37|5@0+ (1,1) [1|32] "Day"  GWM
 SG_ GPS_UTC_seconds : 23|6@0+ (1,0) [0|59] "seconds"  GWM
 SG_ GPS_UTC_minutes : 15|6@0+ (1,0) [0|59] "Minutes"  GWM
 SG_ GPS_UTC_hours : 7|5@0+ (1,0) [0|23] "Hours"  GWM
 SG_ GPS_Pdop : 31|5@0+ (0.2,0) [0|5.8] "unitless"  GWM
 SG_ GPS_Compass_direction : 26|4@0+ (1,0) [0|15] "SED"  HUD_ADV,GWM,IPC
 SG_ GPS_Actual_vs_Infer_pos : 38|1@0+ (1,0) [0|1] "SED"  GWM
 SG_ Gps_B_Falt : 2|1@0+ (1,0) [0|1] "SED"  GWM

BO_ 1122 APIMGPS_Data_Nav_1: 8 APIM
 SG_ GpsHsphLongEast_D_Actl : 9|2@0+ (1,0) [0|3] "SED"  GWM
 SG_ GpsHsphLattSth_D_Actl : 25|2@0+ (1,0) [0|3] "SED"  GWM
 SG_ GPS_Longitude_Minutes : 46|6@0+ (1,0) [0|61] "Minutes"  GWM
 SG_ GPS_Longitude_Min_dec : 55|14@0+ (0.0001,0) [0|1.6381] "Minutes"  GWM
 SG_ GPS_Longitude_Degrees : 39|9@0+ (1,-179) [-179|330] "Degrees"  GWM
 SG_ GPS_Latitude_Minutes : 15|6@0+ (1,0) [0|61] "Minutes"  GWM
 SG_ GPS_Latitude_Min_dec : 23|14@0+ (0.0001,0) [0|1.6381] "Minutes"  GWM
 SG_ GPS_Latitude_Degrees : 7|8@0+ (1,-89) [-89|164] "Degrees"  GWM

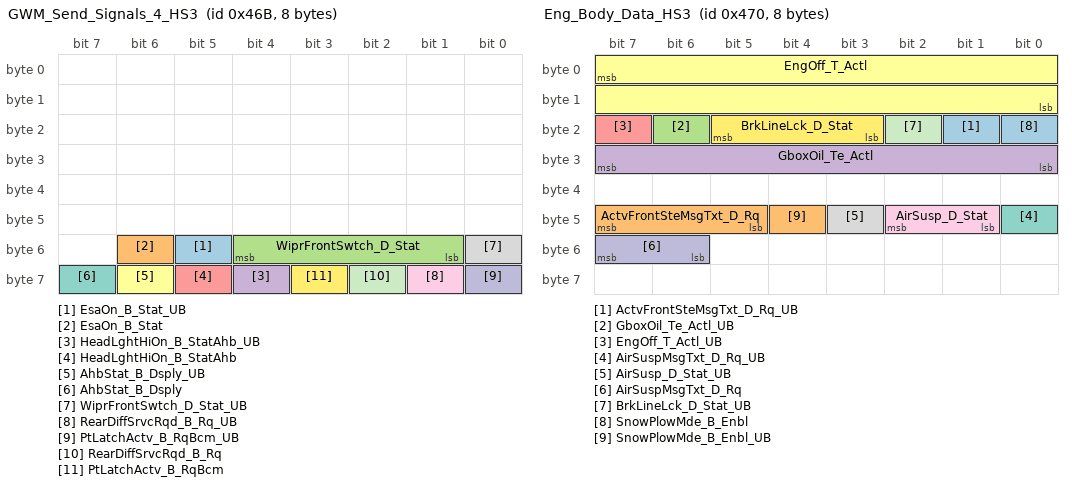
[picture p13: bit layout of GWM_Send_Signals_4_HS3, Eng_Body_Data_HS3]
BO_ 1131 GWM_Send_Signals_4_HS3: 8 GWM
 SG_ EsaOn_B_Stat_UB : 53|1@0+ (1,0) [0|1] "SED"  IPC
 SG_ EsaOn_B_Stat : 54|1@0+ (1,0) [0|1] "SED"  IPC
 SG_ WiprFrontSwtch_D_Stat : 52|4@0+ (1,0) [0|15] "SED"  GENERIC
 SG_ HeadLghtHiOn_B_StatAhb_UB : 60|1@0+ (1,0) [0|1] "SED"  IPC
 SG_ HeadLghtHiOn_B_StatAhb : 61|1@0+ (1,0) [0|1] "SED"  IPC
 SG_ AhbStat_B_Dsply_UB : 62|1@0+ (1,0) [0|1] "SED"  IPC
 SG_ AhbStat_B_Dsply : 63|1@0+ (1,0) [0|1] "SED"  IPC
 SG_ WiprFrontSwtch_D_Stat_UB : 48|1@0+ (1,0) [0|1] "SED"  GENERIC
 SG_ RearDiffSrvcRqd_B_Rq_UB : 57|1@0+ (1,0) [0|1] "SED"  IPC
 SG_ PtLatchActv_B_RqBcm_UB : 56|1@0+ (1,0) [0|1] "SED"  IPC
 SG_ RearDiffSrvcRqd_B_Rq : 58|1@0+ (1,0) [0|1] "SED"  IPC
 SG_ PtLatchActv_B_RqBcm : 59|1@0+ (1,0) [0|1] "SED"  IPC

BO_ 1136 Eng_Body_Data_HS3: 8 GWM
 SG_ ActvFrontSteMsgTxt_D_Rq_UB : 17|1@0+ (1,0) [0|1] "SED"  IPC
 SG_ ActvFrontSteMsgTxt_D_Rq : 47|3@0+ (1,0) [0|7] "SED"  IPC
 SG_ GboxOil_Te_Actl_UB : 22|1@0+ (1,0) [0|1] "SED"  APIM_CISM,APIM,IPC
 SG_ GboxOil_Te_Actl : 31|8@0+ (1,-60) [-60|193] "degC"  APIM_CISM,APIM,IPC
 SG_ EngOff_T_Actl_UB : 23|1@0+ (1,0) [0|1] "SED"  IPC
 SG_ EngOff_T_Actl : 7|16@0+ (1,0) [0|65534] "second^0.5"  IPC
 SG_ AirSuspMsgTxt_D_Rq_UB : 40|1@0+ (1,0) [0|1] "SED"  IPC
 SG_ AirSusp_D_Stat_UB : 43|1@0+ (1,0) [0|1] "SED"  IPC
 SG_ AirSusp_D_Stat : 42|2@0+ (1,0) [0|3] "SED"  IPC
 SG_ AirSuspMsgTxt_D_Rq : 55|2@0+ (1,0) [0|3] "SED"  IPC
 SG_ BrkLineLck_D_Stat_UB : 18|1@0+ (1,0) [0|1] "SED"  IPC
 SG_ BrkLineLck_D_Stat : 21|3@0+ (1,0) [0|7] "SED"  IPC
 SG_ SnowPlowMde_B_Enbl : 16|1@0+ (1,0) [0|1] "SED"  IPC,APIM
 SG_ SnowPlowMde_B_Enbl_UB : 44|1@0+ (1,0) [0|1] "SED"  IPC,APIM

BO_ 1106 TrailerAid_Stat1_HS3: 8 GWM
 SG_ TrlrSnsId_No_Actl : 7|48@0+ (1,0) [0|281474976710653] "unitless"  APIM,APIM_CISM,IPC

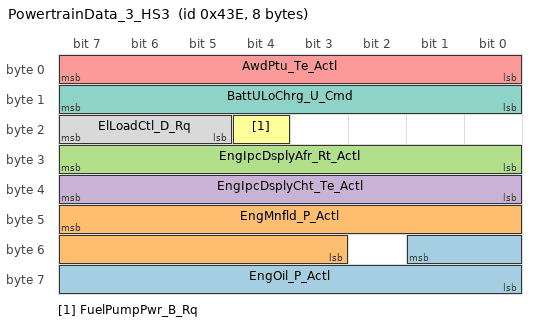
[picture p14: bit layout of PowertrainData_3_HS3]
BO_ 1086 PowertrainData_3_HS3: 8 GWM
 SG_ EngOil_P_Actl : 49|10@0+ (1,0) [0|1023] "kilopascal"  APIM_CISM,APIM,IPC
 SG_ EngMnfld_P_Actl : 47|13@0+ (0.1,-206.8) [-206.8|612.3] "kilopascal"  APIM_CISM,APIM,IPC
 SG_ EngIpcDsplyAfr_Rt_Actl : 31|8@0+ (0.1,0) [0|25.5] "unitless"  IPC
 SG_ EngIpcDsplyCht_Te_Actl : 39|8@0+ (1,-60) [-60|195] "degC"  IPC
 SG_ AwdPtu_Te_Actl : 7|8@0+ (1,-50) [-50|204] "degC" Vector__XXX
 SG_ FuelPumpPwr_B_Rq : 20|1@0+ (1,0) [0|1] "SED"  IPC
 SG_ BattULoChrg_U_Cmd : 15|8@0+ (0.025,10.6) [10.6|16.975] "volt"  IPC
 SG_ ElLoadCtl_D_Rq : 23|3@0+ (1,0) [0|7] "SED"  IPC

BO_ 817 Locking_Systems_2_HS3: 8 GWM
 SG_ ChildLckMde_B_Stat : 56|1@0+ (1,0) [0|1] "SED"  GENERIC
 SG_ VehLckInd_D_Rq : 58|2@0+ (1,0) [0|3] "SED"  GENERIC
 SG_ DrTgateOpen_B_Rq : 59|1@0+ (1,0) [0|1] "SED"  GENERIC
 SG_ DrTgateExtSwMde_B_Stat : 32|1@0+ (1,0) [0|1] "SED"  GENERIC
 SG_ Remote_Device_Feedback : 50|3@0+ (1,0) [0|7] "SED"  GENERIC
 SG_ Veh_Lock_Requestor : 55|5@0+ (1,0) [0|31] "SED"  APIM_CISM,APIM,HUD_ADV
 SG_ R_Pwr_Sliding_Dr_Rqst : 36|1@0+ (1,0) [0|1] "SED"  GENERIC
 SG_ Power_Liftgate_Rqst : 0|1@0+ (1,0) [0|1] "SED"  GENERIC
 SG_ Veh_Lock_EvNum : 47|8@0+ (1,0) [0|255] "unitless"  HUD_ADV,IPC
 SG_ Power_Decklid_Rqst : 1|1@0+ (1,0) [0|1] "SED"  GENERIC
 SG_ L_Pwr_Sliding_Dr_Rqst : 3|1@0+ (1,0) [0|1] "SED"  GENERIC
 SG_ Keyfob_Pad_Msg_Count : 15|8@0+ (1,0) [0|255] "Counts"  GENERIC
 SG_ Veh_Lock_Sub_Id : 63|4@0+ (1,0) [0|15] "SED"  GENERIC
 SG_ Veh_Lock_Status : 34|2@0+ (1,0) [0|3] "SED"  APIM_CISM,HUD_ADV,APIM,RACM_RCIM,ACM,IPC
 SG_ ChildLck_D_Dsply : 7|2@0+ (1,0) [0|3] "SED"  GENERIC
 SG_ WindowLockout_B_Stat : 35|1@0+ (1,0) [0|1] "SED"  GENERIC
 SG_ RollCodeUnlock : 23|16@0+ (1,0) [0|65535] "Unitless"  IPC
 SG_ Lockmsgtxt_D_Rq : 39|3@0+ (1,0) [0|7] "SED"  IPC
 SG_ FobComm_D_Stat : 5|2@0+ (1,0) [0|3] "SED"  GENERIC
 SG_ LockInhibit : 2|1@0+ (1,0) [0|1] "SED"  APIM

BO_ 611 Driveline_Data_1_HS3: 8 GWM
 SG_ AwdTerrMdeChng_D_Rdy : 58|3@0+ (1,0) [0|7] "SED"  IPC
 SG_ AwdTerrMde_D_Actl : 50|3@0+ (1,0) [0|7] "SED"  IPC
 SG_ AwdSys_D_Stat : 27|2@0+ (1,0) [0|3] "SED"  IPC
 SG_ AwdStat_D_RqDsply : 63|5@0+ (1,0) [0|31] "SED"  IPC
 SG_ AwdLck_D_Stat : 31|4@0+ (1,0) [0|15] "SED"  IPC
 SG_ AwdSrvcRqd_B_Rq : 0|1@0+ (1,0) [0|1] "SED"  IPC
 SG_ AwdLck_Tq_Rq : 15|12@0+ (1,0) [0|4093] "Nm"  IPC
 SG_ TrnAout_Tq_RqMx : 47|13@0+ (1,-1250) [-1250|6941] "Nm"  IPC
 SG_ AwdOffRoadMode_D_Stats : 25|2@0+ (1,0) [0|3] "SED"  APIM_CISM,APIM,IPC
 SG_ AwdLoLamp_D_RqDsply : 35|2@0+ (1,0) [0|3] "SED"  IPC
 SG_ AwdHiLamp_D_RqDsply : 19|2@0+ (1,0) [0|3] "SED"  IPC
 SG_ AwdAutoLamp_D_RqDsply : 17|2@0+ (1,0) [0|3] "SED"  IPC
 SG_ Awd2wdLamp_D_RqDsply : 2|2@0+ (1,0) [0|3] "SED"  IPC
 SG_ AwdRnge_D_Actl : 7|3@0+ (1,0) [0|7] "SED"  APIM_CISM,ACM,APIM,IPC
 SG_ NtrlTowAvail_B_Stat : 4|1@0+ (1,0) [0|1] "SED"  IPC
 SG_ AwdDrvMde_D_Stat : 38|3@0+ (1,0) [0|7] "SED"  IPC
 SG_ SelDrvMdeAwd_D_Stat : 33|2@0+ (1,0) [0|3] "SED"  GENERIC

BO_TX_BU_ 722 : APIM_CISM,APIM;
BO_TX_BU_ 721 : APIM_CISM,APIM;
BO_TX_BU_ 720 : APIM_CISM,APIM;
BO_TX_BU_ 470 : APIM_CISM,APIM;
BO_TX_BU_ 694 : APIM_CISM,APIM;
BO_TX_BU_ 750 : APIM_CISM,APIM;
BO_TX_BU_ 704 : APIM_CISM,APIM;
BO_TX_BU_ 404 : APIM_CISM,APIM;
BO_TX_BU_ 689 : APIM_CISM,ACM;
BO_TX_BU_ 1008 : APIM_CISM,APIM;
BO_TX_BU_ 547 : APIM_CISM,ACM;
BO_TX_BU_ 759 : APIM_CISM,ACM;
BO_TX_BU_ 144 : APIM_CISM,APIM;
BO_TX_BU_ 1124 : APIM_CISM,APIM;
BO_TX_BU_ 1123 : APIM_CISM,APIM;
BO_TX_BU_ 1122 : APIM_CISM,APIM;
CM_ SG_ 722 VRM_ComShuffleTrack_St "Object Voice Recogniser.ComShuffleTrack";
CM_ SG_ 722 VRM_ComCompression_St "Object Voice Recogniser.ComCompression";
CM_ SG_ 722 VRM_ComStFreqMode_St "Object Voice Recogniser.ComFrequency(Parameter1)
Object Voice Recogniser.ComStation";
CM_ SG_ 722 VRM_ComAutostore_St "Object Voice Recogniser.ComAutostore";
CM_ SG_ 722 VRM_ComBand_St "Object Voice Recogniser.ComBand";
CM_ SG_ 722 VRM_TMCVoice "Object Voice Recogniser.TMC Voice";
CM_ SG_ 722 VRM_NewSMS "Object Bluetooth Phone";
CM_ SG_ 722 VRM_ComRSEDisplay_St "Object Voice Recogniser.ComRSEDisplay
NOT USED";
CM_ SG_ 722 VRM_ComPICode_St "Object Voice Recogniser.ComStation(PI Code)
(Parameter1)

16 bit hex coded PI Code";
CM_ SG_ 722 VRM_ComPresetCall_St "Object Voice Recogniser.ComPresetCall
NOT USED";
CM_ SG_ 722 VRM_ComTape_St "Object Voice Recogniser.ComTape
NOT USED";
CM_ SG_ 722 VRM_ComShuffleDiscs_St "Object Voice Recogniser.ComShuffleDiscs
NOT USED";
CM_ SG_ 722 VRM_ComDolbyNR_St "Object Voice Recogniser.ComDolbyNr
NOT USED";
CM_ SG_ 722 VRM_ComSourceSelect_St "Object Voice Recogniser.ComSourceSelect";
CM_ SG_ 722 VRM_ComStFreq_St "Object Voice Recogniser.ComFrequency(Parameter2)
Object Voice Recogniser.ComStation(Parameter2)

AM: Freq = 153+ Offset kHz. Offset 0..1557
FM: Freq = 76+ Offset*0.05 MHz. Offset 0..640
Selected tuned band determine frequency (kHz or MHz).
";
CM_ SG_ 722 VRM_ComRouteStrategy_St "Object Voice Recogniser.ComRouteStrategy";
CM_ SG_ 721 VRM_BTDefaultPhone_St "Object Voice Recogniser.BTDefaultPhone";
CM_ SG_ 721 VRM_DetourUnit_st "Object Voice Recogniser.DetourUnit";
CM_ SG_ 721 VRM_Zoom_Option_St "Object Voice Recogniser.ComZoom";
CM_ SG_ 721 VRM_ComBTDTMFTone_St "Object Voice Recogniser.ComBTDTMFTone";
CM_ SG_ 721 VRM_SuggestedRoute_St "Object Voice Recogniser.ComSuggestedRoute
NOT USED";
CM_ SG_ 721 VRM_ComDelWaypoint_St "Object Voice Recogniser.ComDelWaypoint";
CM_ SG_ 721 VRM_ComSelectDisc_St "Object Voice Recogniser.ComSelectDisc";
CM_ SG_ 721 VRM_ComTelService_St "Object Voice Recogniser.ComTelematicsService
NOT USED";
CM_ SG_ 721 VRM_ComDestHome_St "Object Voice Recogniser.ComDestHome";
CM_ SG_ 721 VRM_ComSelectTrack_St "Object Voice Recogniser.ComSelectTrack

$01: Command has not been issued";
CM_ SG_ 721 VRM_ComShowNavInfo_St "Object Voice Recogniser.ComShowNavInfo";
CM_ SG_ 721 VRM_VoiceRecStatus_St "Object VoiceRecognizer.VoiceRecStatus";
CM_ SG_ 721 VRM_ComSelTrackSource_St "Object Voice Recogniser.ComSelectTrack, parameter Source";
CM_ SG_ 721 VRM_ComDetour_St "Object Voice Recogniser.ComDetour";
CM_ SG_ 721 VRM_ComDisplay_St "Object Voice Recogniser.ComDisplay";
CM_ SG_ 721 VRM_ComDynamicGuidande_St "Object Voice Recogniser.DynamicRouteGuidance";
CM_ SG_ 721 VRM_ComZoom_St "Object Voice Recogniser.ComZoom";
CM_ SG_ 721 VRM_ComCallControl_St "Object Voice Recogniser.ComCallControl
NOT USED";
CM_ SG_ 721 VRM_ComGuidance_St "Object Voice Recogniser.ComGuidance";
CM_ SG_ 721 VRM_ComTrafficInfDsp_St "Object Voice Recogniser.ComTrafficInformation";
CM_ SG_ 720 VRM_PhMicrophoneMute_St "Object Bluetooth Phone.PhMicrophoneMute";
CM_ SG_ 720 Aioc_ExtSrcOutpMode_St "Object Audio Management Audio Switch.BVCOutputMode";
CM_ SG_ 720 VRM_BTPhoneSts_St "Object Bluetooth Phone.BTPhoneSts";
CM_ SG_ 720 VRM_SubscribeStatus_St "Object Bluetooth Phone";
CM_ SG_ 720 VRM_BlutoothStatus_St "Object Bluetooth Phone (Spelled as BluetoothStatus in OS)";
CM_ SG_ 720 VRM_BondRequest_St "Object Bluetooth Phone";
CM_ SG_ 720 VRM_VRMMonoOutMode_St "Object VRMAudioIOController.VRMMonoOutMode";
CM_ SG_ 720 VRM_BTNetworkStatus_St "Object Bluetooth Phone.BTNetworkStatus";
CM_ SG_ 720 VRM_BTSignalStrength_St "Object Bluetooth Phone.BTSignalStrength";
CM_ SG_ 720 VRM_BTBatteryLevel_St "Object Bluetooth Phone.BTBatteryLevel";
CM_ SG_ 758 SDARS_OpMode_St "Object Tuner.SDARS Tuner.OperationMode";
CM_ SG_ 758 SDARS_SetCategory_St "Object.ExternalPersonalization.SDARS_SetCategory.St.Category
0x00: All
0x01: Category1
0x02: Category2
....
0xF9: Category249
0xFA: Reserved
....
0xFE: Reserved
0xFF: Invalid 
";
CM_ SG_ 758 SDARS_GCI_Update_Prg_St "Object Tuner.SDARS Tuner.GCIUpdateProgress
0-100%";
CM_ SG_ 758 SDARS_Factory_Reset_St "Object Tuner.SDARS Tuner.FactoryReset";
CM_ SG_ 760 SDARS_SID_St "Object Tuner.SDARS.ServiceID
$0: SID_0
$1: SID_1
$2: SID_2
$FE: SID_254
$FF: SID_255

";
CM_ SG_ 760 SDARS_CurrentChanNum_St "Object Tuner.SDARS Tuner.CurrentChanNum.ChanNum 
$0: Channel_0
$1: Channel_1
$2: Channel_2
$FE: Channel_254
$FF: Inactive";
CM_ SG_ 760 SDARS_Buffer_sec_St "Object Tuner.SDARS Tuner.BufferStatus.Second
(Parameter5)
";
CM_ SG_ 760 SDARS_Buffer_min_St "Object Tuner.SDARS Tuner.BufferStatus.Minute
(Parameter4)
";
CM_ SG_ 760 SDARS_Buffer_hr_St "Object Tuner.SDARS Tuner.BufferStatus.Hour
(Parameter3)
";
CM_ SG_ 760 SDARS_Playback_St "Method SDARS_BufferStatus
0-100%
Object Tuner.SDARS Tuner.BufferStatus.PlaybackPosition
(Parameter2)";
CM_ SG_ 760 SDARS_FillPosition_St "Method SDARS_BufferStatus
0-100%
Object Tuner.SDARS Tuner.BufferStatus.FillPosition
(Parameter1)";
CM_ SG_ 760 SDARS_Alert_Status "Object.Tuner.SDARS.AlertStatus";
CM_ SG_ 760 SDARS_Channel_Lock "Method SDARS_Channel_Lock";
CM_ SG_ 692 AUDIO_RDISP_WORD_Tx "MM ISO 15765-2 Message Catalogue
Section AUDIO - RDISP";
CM_ SG_ 942 PrkAidRdiusRight_L_Dsply "MSGDCR 679, set all signals to OnChange";
CM_ SG_ 942 PrkAidRdiusLeft_L_Dsply "MSGDCR 679, set all signals to OnChange";
CM_ SG_ 942 PrkAidDrvDir_D_Stat "MSGDCR 679, set all signals to OnChange";
CM_ SG_ 1088 HvacPrecondMode2_D_Rq "Signal not transmitted on vehicles that do not have the Fuel operated heater feature.";
CM_ SG_ 1088 HvacPrecondBlwr2_D_Rq "Signal not transmitted on vehicles that do not have the Fuel operated heater feature.";
CM_ SG_ 761 SDARS_Seek_Scan_St "Method SDARS_Error_Msg
Int Seek/Scan No Channels Available

0x1: No Channel Available
Object Tuner.SDARS Tuner.";
CM_ SG_ 761 SDARS_Invalid_Chan_St "Object Tuner.SDARS Tuner.";
CM_ SG_ 761 SDARS_UnSubscrb_Chan_St "Object Tuner.SDARS Tuner.Unsubscribed Channel ";
CM_ SG_ 761 SDARS_Loss_Ant_St "Object Tuner.SDARS Tuner.Loss of Antenna Signal ";
CM_ SG_ 761 SDARS_UnSubscrb_St "Object Tuner.SDARS Tuner.Unsubscribed Receiver ";
CM_ SG_ 761 SDARS_Subscription_St "Object Tuner.SDARS Tuner.Subscription Update ";
CM_ SG_ 761 SDARS_GCI_Update_St "Object Tuner.SDARS Tuner.GCI Update ";
CM_ SG_ 761 SDARS_Firmware_Updat_St "Object Tuner.SDARS Tuner.FirmwareUpdate";
CM_ SG_ 761 SDARS_Antenna_Err_St "Object Tuner.SDARS Tuner.Antenna Error";
CM_ SG_ 761 SDARS_Receive_Err_St "Object Tuner.SDARS Tuner.Receiver Error";
CM_ SG_ 761 SDARS_Error_Conf_St "Object Tuner.SDARS Tuner.Configuration Status";
CM_ SG_ 694 PHONE_MC_WORD_Tx "MM ISO 15765-2 Message Catalogue
Section  PHONE - MC";
CM_ SG_ 750 UnitOfLength_St "Object.VehicleSettings.LengthUnit.St";
CM_ SG_ 750 RouteActive_St "RouteActive";
CM_ SG_ 750 CancelCurrWaypt_St "Object.NavigationRepeater.CancelCurrentWayPoint.Rsp.Cancelwaypoint";
CM_ SG_ 750 Nav_RemainTTDestDays_St "Object.NavigationRepeater.RemainTimeToDestination.Days
0x0…0xD: days (0…13)
0xE: greater than 13 days";
CM_ SG_ 750 WaypointsActive_St "Object:NavigationRepeater.WaypointsActive.St.WaypointStatus";
CM_ SG_ 750 Nav_RemainTTDestHour_St "Object Navigation.RemainTimeToDestination
0x00 .. 0x18: hours (0 .. 24)
0x19 .. 0x1D: reserved
0x1E : not available";
CM_ SG_ 750 Nav_RemainTTDestMin_St "Object Navigation.RemainTimeToDestination
0x00 .. 0x3C: minutes (0 .. 60)
0x3D .. 0x3D: reserved
0x3E : not available";
CM_ SG_ 750 Nav_DistanToDestUnit_St "Object Navigation.DistanceToDestination

This attribute shows the remaining distance to destination to the infotainment displays.
";
CM_ SG_ 750 Nav_DistancToDestVal_St "Object Navigation.DistanceToDestination

This attribute shows the remaining distance to destination to the infotainment displays.

0x0000 .. 0xFFFD: distance (0 .. 65533)
0xFFFE : distance not available";
CM_ SG_ 750 NavError_Waypoint_St "Object:NavigationRepeater.NAVError.WaypointStatus";
CM_ SG_ 704 NAV_MC_WORD_Tx "MM ISO 15765-2 Message Catalogue
Section NAV - MC
Section NavRepServer - NavRepClient";
CM_ SG_ 725 ACU_CompLogic_St "Object.CDCompLogic_St ";
CM_ SG_ 725 ACU_RadioError_St "Object Audio Management Audio Client.AudioError.RadioError";
CM_ SG_ 725 ACU_HardwareError_St "Object Audio Management Audio Client.AudioError.HardwareError";
CM_ SG_ 725 ACU_CurrentRadioBand_St "Object Tuner.CurrentRadioBand";
CM_ SG_ 725 ACU_CurrentPTYCode_St "Object Tuner.CurrentPTYCode

$0: Invalid
$1: PTY 1 (News)
..
$1F: PTY 31 (Alarm)";
CM_ SG_ 725 ACU_CurrentPICode_St "Object Tuner.CurrentPICode";
CM_ SG_ 725 ACU_CurrentFreq_St "Object Tuner.CurrentFreq

AM: Freq = 153+ Offset kHz.
Offset 0..1557 

FM: Freq = 76+ Offset*0.05 MHz. Offset 0..640
Selected tuned band determine frequency (kHz or MHz).";
CM_ SG_ 725 ACU_AFMode_St "Object Tuner.AFMode";
CM_ SG_ 548 DSP_ChimeChanState_St "Object BodyInterface.StdChimeIF.ChimeChannelState.St";
CM_ SG_ 548 DSP_Chime2_Not_Recgnizd "Object.ChimeAudioSource.DSP_Chime_Not_Recognized ";
CM_ SG_ 548 DSP_Chime_Not_Recgnizd "Object.ChimeAudioSource.DSP_Chime_Not_Recognized ";
CM_ SG_ 548 DSP_Alert_Channel3 "Object.AlertMethod.DSP_AMP_Alert

";
CM_ SG_ 548 DSP_Alert_Channel2 "Object.AlertMethod.DSP_AMP_Alert

";
CM_ SG_ 548 DSP_Alert_Channel1 "Object.AlertMethod.DSP_AMP_Alert

";
CM_ SG_ 548 DSP_Chimes_Supported "Object.AlertMethod.DSP_AMP_Alert

";
CM_ SG_ 548 DSP_AdjChimVolSupp_St "AdjustableChimeVolSupported2";
CM_ SG_ 548 DSP_AdjChimVolSupp2_St "AdjustableChimeVolSupported";
CM_ SG_ 404 Dsp_LangUpdate_Rsp "Object. LanguageUpdate.Rsp";
CM_ SG_ 689 AUDIO_MC_WORD_Tx "MM ISO 15765-2 Message Catalogue
Section Audio - MC";
CM_ SG_ 1008 CPM_MediaPlayerSrc_St "Object AtlanticWizard.AudioManagement.PeripheralMediaPlayerAudioSourceStatus_St";
CM_ SG_ 1008 APIM_TrackPlaytime_St "Object.Mediaplayer.TotalPlayTime";
CM_ SG_ 1008 APIM_TotalPlayTime_St "Object.Mediaplayer.TotalPlayTime";
CM_ SG_ 547 Audio_Amp_St "Object. Audio_Amp_St";
CM_ SG_ 547 Chime_Alert_Chan2 "Object.AlertMethod. AHU_Alerts";
CM_ SG_ 547 AHU_Chime2_Active "Object. AlertMethod. AHU_Alerts

0x0 Inactive
0x1 No_Chime
0x2 Chime_1
0x3 Chime_2
0x4 Chime_3
cont.
0x3F Chime_62";
CM_ SG_ 547 AHU_Chime2_Not_Recognized "Object.AlertMethod. AHU_Alerts";
CM_ SG_ 547 Chime_Alert_Chan "Object.AlertMethod. AHU_Alerts";
CM_ SG_ 547 AHU_Alert_Channel1 "Object.AlertMethod.AHU_Alerts

";
CM_ SG_ 547 AHU_Chime_Supported "Object.AlertMethod. AHU_Alerts";
CM_ SG_ 547 AHU_Chime_Active "Object. AlertMethod. AHU_Alerts

0x0 Inactive
0x1 No_Chime
0x2 Chime_1
0x3 Chime_2
0x4 Chime_3
cont.
0x3F Chime_62";
CM_ SG_ 547 AHU_Chime_Not_Recognized "Object.AlertMethod. AHU_Alerts";
CM_ SG_ 547 AHU_AdjChimVolSupp2_St "AdjustableChimeVolSupported2";
CM_ SG_ 547 AHU_AdjChimeVolSupp_St "AdjustableChimeVolSupported";
CM_ SG_ 732 ACU_CurrItemsInFMSL_St "Object Tuner.CurrentItemsInFMSL";
CM_ SG_ 732 ACU_FunctionStatus_St "Object Indash CD Changer.FunctionStatus
Object Single CD.FunctionStatus";
CM_ SG_ 732 ACU_CurrFMSLPreset_St "Object Tuner.CurrentFMSLPreset

Not applicable for LLA, HLA
CurrentSLIndex";
CM_ SG_ 732 ACU_CurrPreset2_St "Object Tuner.CurrentPreset2";
CM_ SG_ 732 ACU_StorePreset_St "Object Tuner.StorePreset";
CM_ SG_ 732 ACU_VoiceCommand_St "Object VoiceRecogniser.VoiceCommand";
CM_ SG_ 732 ACU_CurrMixPreset_St "Object Tuner.CurrMixPreset";
CM_ SG_ 728 ACU_AuxVolume_Up "Object Audio.Volume_UP
Indicate user value recalls if the value is set to lower/upper border ";
CM_ SG_ 728 ACU_AuxVolume_St "Object Audio.AuxVolume

Level 0..30";
CM_ SG_ 728 ACU_Mid_St "Object Audio.Mid

Level -7..0..7


Method: AHU_Midrange";
CM_ SG_ 728 ACU_RadioSeekMode_St "Object Tuner.RadioSeekMode";
CM_ SG_ 728 ACU_Volume_St "Object Audio.Volume

Level 0..30
Method AHU_Audio_Vol_Level

Refer method table in SPSS for details
0x0 No Volume
0x1 Vol_Step1
0x2 Vol_Step2
0x3 Vol_Step3
Cont.
0x1E Vol_Step30";
CM_ SG_ 728 ACU_Volume_Up "Object Audio.Volume_UP
Indicate user value recalls if the value is set to lower/upper border 
Method AHU_Audio_Vol_Updated";
CM_ SG_ 728 ACU_CurrentStatFlags_St "Object Tuner.CurrentStatFlags

Bit 0: Validation
Bit 1: EON not sup; 1: EON sup
Bit 2: TP not sup; 1: TP sup
Bit 3: 0: Mono; 1: Stereo
Bit 4: 0: RDS not sup; 1: RDS sup";
CM_ SG_ 489 ACU_CurrentPSName_St "Object Tuner.CurrentPSName
Object Tuner.DAB.CurrentServiceName

Text with maximum 8 characters";
CM_ SG_ 757 ACU_AutoStoreResult_St "Object Tuner. RadioSeekModeResult";
CM_ SG_ 757 ACU_DirectTune_St "Object.Tuner.DirectTune";
CM_ SG_ 757 ACU_RadioSeekMode2_St "Object Tuner.RadioSeekMode2";
CM_ SG_ 757 ACU_CurrTUBand_St "Object.Tuner.CurrentTUBand";
CM_ SG_ 734 ACU_ActServiceLink_St "Object DAB.ActServiceLink";
CM_ SG_ 734 ACU_CurrTUDRService2_St "Object DAB.CurrentDRServiceStatus";
CM_ SG_ 734 ACU_ComTUSIDValid_St "Object DAB.CurrentSID.Availability
";
CM_ SG_ 734 ACU_CurrTUDABBlock_St "Object DAB.CurrentDABBlock
Bitfield:
Bit 0..4: L-Band Canada: Numeric value (NV)(1 .. 23); L-Band Europe: NV (A=1 .. W=23); Band III: NV (A=1 .. W=23); 
Bit 5..8: Band III: NV (not used for L-Band; set value to 0h)
Bit 9: 0: Band III, 1: L-Band
";
CM_ SG_ 734 ACU_CurrTUDRService_St "Object DAB.CurrentDRServiceStatus";
CM_ SG_ 734 ACU_CurrTURadioBand_St "Object DAB.CurrentTUBand

Gen3 Values 
$1: reserved
$2: reserved 
$3: reserved
$4: reserved
$5: reserved
$6: reserved";
CM_ SG_ 734 ACU_CurrTUSCIDI_St "Object DAB.CurrentSCIDI";
CM_ SG_ 734 ACU_CurrTUServiceLink_St "Object DAB.CurrentServiceLink";
CM_ SG_ 734 ACU_CurrTUSID_St "Object DAB.CurrentSID.SID

For Digital Radio: 
Byte 1..2: 16 bit hex coded SID
Byte 3:     8 bit hex coded ECC";
CM_ SG_ 759 Avail_HD_Chan_Valid "Object. AvailableHDChannel.St";
CM_ SG_ 759 Avail_HD_Chan_St_7 "Object. AvailableHDChannel.St";
CM_ SG_ 759 Avail_HD_Chan_St_6 "Object. AvailableHDChannel.St";
CM_ SG_ 759 Avail_HD_Chan_St_5 "Object. AvailableHDChannel.St";
CM_ SG_ 759 Avail_HD_Chan_St_4 "Object. AvailableHDChannel.St";
CM_ SG_ 759 Avail_HD_Chan_St_3 "Object. AvailableHDChannel.St";
CM_ SG_ 759 Avail_HD_Chan_St_2 "Object. AvailableHDChannel.St";
CM_ SG_ 759 Avail_HD_Chan_St_1 "Object. AvailableHDChannel.St";
CM_ SG_ 759 ACM_StationListScanSt "Object.AMFMSlave.StationListScan
$0:Invalid";
CM_ SG_ 759 ACM_TagMode "Object.AMFMSlave.TagMode";
CM_ SG_ 759 ACM_RBDSMode "Object.AMFMSlave.RBDSMode";
CM_ SG_ 759 NumofHDMulticastChans_St "Object. AMFMSlave.NumofHDMulticastChans";
CM_ SG_ 759 ACM_HDModeStatus "Object.AMFMSlave.HDMode";
CM_ SG_ 759 ACM_HDChanStatus "Object. AMFMSlave.HDChanStatus
$0:Inactive";
CM_ SG_ 759 ACM_CurrentSSName "Object.AMFMSlave.Method CurrentSSName";
CM_ SG_ 759 ACM_CurrentHDMulticast_St "Object.AMFMSlave.CurrentHDMulticast";
CM_ BO_ 144 "GW Message IMS->BMS";
CM_ SG_ 144 SetTimeFormat "Object.BodyInterface.Settings.VehicleTimeFormatUserSelection";
CM_ SG_ 144 SetYear "Object Clock.SetYear

Request from the Audio Control Unit to the Cluster in order to adjust the years, with an offset of 2000.";
CM_ SG_ 144 SetMonth "Object Clock.SetMonth

Request from the Audio Control Unit to the Cluster in order to adjust the months.";
CM_ SG_ 144 SetDay "Object Clock.SetDay

Request from the Audio Control Unit to the Cluster in order to adjust the days.";
CM_ SG_ 144 SetHour "Object Clock.SetHour

Request from the Audio Control Unit to the Cluster in order to adjust the hours.";
CM_ SG_ 144 SetMinute "Object Clock.SetMinute

Request from the Audio Control Unit to the Cluster in order to adjust the minutes.";
CM_ SG_ 144 SetSecond "Object Clock.SetSecond

Request from the Audio Control Unit to the Cluster in order to adjust the seconds.";
CM_ SG_ 144 TimeAdjustRequest "Object Clock.TimeAdjustRequest

Request from the Audio Control Unit to the Cluster in order to adjust the time.";
CM_ SG_ 144 DateAdjustRequest "Object Clock.DateAdjustRequest

Request from the Audio Control Unit to the Cluster in order to adjust the date.";
CM_ SG_ 851 ConsUnitIPC_D_Dsply "Communicates the instrument cluster current unit mode setting. Used thru-out displays to update units and labels for the fuel consumption history displays. If units updated on cluster, other displays thru-out vehicle should be updated as well.";
CM_ SG_ 792 ElTrip_L_Dsply "Key cycle trip distance driven with the engine off (Trip EV Miles)";
CM_ SG_ 792 ElLongTerm_L_Dsply "Long term distance distance driven with the engine off since the last long term reset (Long Term EV Miles).";
CM_ SG_ 787 VehElSurpStat_L_Dsply "Number of surplus / debt miles displayed on the BEV instrument cluster. Used for BEV cluster and centerstack displays in both numerical an emotive displays. Negative numbers mean a debt, positive numbers are a surplus. ";
CM_ SG_ 787 TripSum_Vl_Dsply "This signal represents the total fuel used by the vehicle on the current trip. It is intended to be used on the cluster shutdown summary screen and in remote data functions (i.e. MyData).";
CM_ SG_ 787 TripSum_E_Dsply "This signal represents the total energy used by the vehicle on the current trip. It is intended to be used on the cluster shutdown summary screen.";
CM_ SG_ 787 TripSum_L_Dsply "Trip Length (Last Drive)";
CM_ SG_ 697 AUDIO_MC_WORD_Rx "MM ISO 15765-2 Message Catalogue
Section MC - Audio";
CM_ SG_ 700 AUDIO_RDISP_WORD_Rx "MM ISO 15765-2 Message Catalogue
Section RDISP - Audio
";
CM_ SG_ 676 MC_RDISP_WORD_Tx "Communicates ConsHistGraph_St, which includes data to populate the consumption history display.";
CM_ SG_ 504 Mc_AudioSourceSel_Rq "Object Single CD.GetFolderName.AudioSource
Object Media Player
BTAudio.GetFolderName.AudioSource
BTAudio.SetTrack.AudioSource
USB.GetFolderName.AudioSource
USB.SetTrack.AudioSource
SDCard.GetFolderName.AudioSource
SDCard.SetTrack.AudioSource";
CM_ SG_ 504 Mc_FolderNumber_Rq "Object Media Player BTAudio.GetFolderName.FolderName
Object Media Player USB.GetFolderName.FolderName
Object Single CD.GetFolderName.FolderNumber
Object Media Player SDCard.FolderNumber

$FFFF: Inactive";
CM_ SG_ 504 Mc_CutItem_Rq "Object Media Player BTAudio.GetFolderName.CutItemName
Object Media Player USB.GetFolderName.CutItemName
Object Single CD.GetFolderName.CutItem
Object Media Player SDCard.CutItem";
CM_ SG_ 504 Mc_ItemNameLength_Rq "Object Media Player BTAudio.GetFolderName.ItemNameLength
Object Media Player USB.GetFolderName.ItemNameLength
Object Media Player SDCard.GetFolderName.ItemNameLength
Object Single CD.GetFolderName.ItemNameLength";
CM_ SG_ 504 Mc_SourceSetTrack_Rq "Object Media Player BTAudio.SetTrack
Object Media Player USB.SetTrack
Object Media Player SDCard.SetTrack

$0000: Inactive";
CM_ SG_ 410 MyKey_e911Override_St "Object MyKey.MyKey_e911Override_St";
CM_ SG_ 410 DoNotDisturbOveride_St "Object MyKey.DoNotDisturbOverride_St 
";
CM_ BO_ 1124 "HS3 APIM Sync Gen3 Tx 0x464.  FrameGateway to 0x467 on HS1, HS2, HS3 and MS1.";
CM_ BO_ 1123 "HS3 APIM Sync Gen3 Tx 0x463.  FrameGateway to 0x466 on HS1, HS2, HS3 and MS1.";
CM_ BO_ 1122 "HS3 APIM Sync Gen3 Tx 0x462.  FrameGateway to 0x465 on HS1, HS2, HS3 and MS1.";
CM_ SG_ 1136 GboxOil_Te_Actl "Signal not transmitted on HEV variants. MHT(U611/625) HPCM Rx 0x230 from PCM_HEV. Powersplit FWD HEV’s(Cx482/3 430) HPCM Tx 0x230.";
CM_ BO_ 1106 " new RCM Serial Trailer Aid (TrailerAid_Stat1) 48 bits";
CM_ SG_ 1086 ElLoadCtl_D_Rq "Signal not transmitted on HEV variants.";
CM_ BO_ 611 "Used on Applications with 4x4 supplied by Motorola.";
CM_ SG_ 611 AwdStat_D_RqDsply "Signal not transmitted on programs that do not have AWD.";
CM_ SG_ 611 AwdSrvcRqd_B_Rq "Signal not transmitted on programs that do not have AWD.";
CM_ SG_ 611 AwdLck_Tq_Rq "Signal not transmitted on programs that do not have AWD.";
BA_DEF_ BO_  "FrameRouting" STRING ;
BA_DEF_ BO_  "FrameGatewayNetwork" STRING ;
BA_DEF_ BO_  "NetworkInitialization" ENUM  "No","Yes";
BA_DEF_ BO_  "FrameGatewayId" HEX 0 1407;
BA_DEF_ BO_  "EventRateOfChange" INT 10 10000;
BA_DEF_ BO_  "GenMsgStartDelayTime" INT 0 10000;
BA_DEF_ BO_  "GenMsgNrOfRepetition" INT 0 100;
BA_DEF_ BO_  "GenMsgDelayTime" INT 0 1000;
BA_DEF_ BO_  "GenMsgCycleTime" INT 0 100000;
BA_DEF_ BO_  "GenMsgSendType" ENUM  "FixedPeriodic","Event","EnabledPeriodic","NotUsed","NotUsed","EventPeriodic","NotUsed","NotUsed","NoMsgSendType";
BA_DEF_ SG_  "U_U55X_MY2022_Tx" ENUM  "No","Yes";
BA_DEF_ SG_  "U_CD542_MY2021_Tx" ENUM  "No","Yes";
BA_DEF_ SG_  "ECGUsedTxSignal" ENUM  "No","Yes";
BA_DEF_ SG_  "U_T6_MCA_MY2020_Tx" ENUM  "No","Yes";
BA_DEF_ SG_  "U_P702_MY2021_Tx" ENUM  "No","Yes";
BA_DEF_ SG_  "U_CX727_MY2021_Tx" ENUM  "No","Yes";
BA_DEF_ SG_  "U_FNV2_IVI_Rx" ENUM  "No","Yes";
BA_DEF_ SG_  "U_U55X_MY2022_Rx" ENUM  "No","Yes";
BA_DEF_ SG_  "U_CD542_MY2021_Rx" ENUM  "No","Yes";
BA_DEF_ SG_  "ECGUsedRxSignal" ENUM  "No","Yes";
BA_DEF_ SG_  "U_T6_MCA_MY2020_Rx" ENUM  "No","Yes";
BA_DEF_ SG_  "U_P702_MY2021_Rx" ENUM  "No","Yes";
BA_DEF_ SG_  "U_CX727_MY2021_Rx" ENUM  "No","Yes";
BA_DEF_ SG_  "GenSigStartValue" HEX 0 268435455;
BA_DEF_ SG_  "MetaData" ENUM  "No","Yes";
BA_DEF_ SG_  "ContentDependant" ENUM  "No","Yes";
BA_DEF_ SG_  "GenSigStartValueInteger" INT 0 1000000000;
BA_DEF_ SG_  "UsedOnPgmDBC" ENUM  "No","Yes";
BA_DEF_ SG_  "WakeupSignal" ENUM  "No","Yes";
BA_DEF_ SG_  "GenSigInactiveValue" INT 0 100000;
BA_DEF_ SG_  "GenSigSendType" ENUM  "Cyclic","OnWrite","vector_leerstring","OnChange","vector_leerstring","IfActive","vector_leerstring","NoSigSendType";
BA_DEF_ BO_  "OvtpPushApplication" ENUM  "FALSE","TRUE";
BA_DEF_ BO_  "SCP_FreshnessValueLength" INT 0 512;
BA_DEF_ BO_  "SCP_FreshnessValueTxLength" INT 0 512;
BA_DEF_ BO_  "SCP_AuthInfoTxLength" INT 0 512;
BA_DEF_ BO_  "GenMsgRoutingTimeoutTime" INT 0 5000;
BA_DEF_ BO_  "MessageGateway" ENUM  "No","Yes";
BA_DEF_ BO_  "NmAsrMessage" ENUM  "No","Yes";
BA_DEF_ BO_  "DiagState" ENUM  "No","Yes";
BA_DEF_ BO_  "TpTxIndex" INT 0 536870911;
BA_DEF_ BO_  "DiagRequest" ENUM  "No","Yes";
BA_DEF_ BO_  "DiagResponse" ENUM  "No","Yes";
BA_DEF_ BO_  "GenMsgILSupport" ENUM  "No","Yes";
BA_DEF_DEF_  "FrameRouting" "";
BA_DEF_DEF_  "FrameGatewayNetwork" "NONE";
BA_DEF_DEF_  "NetworkInitialization" "Yes";
BA_DEF_DEF_  "FrameGatewayId" 0;
BA_DEF_DEF_  "EventRateOfChange" 10000;
BA_DEF_DEF_  "GenMsgStartDelayTime" 0;
BA_DEF_DEF_  "GenMsgNrOfRepetition" 1;
BA_DEF_DEF_  "GenMsgDelayTime" 20;
BA_DEF_DEF_  "GenMsgCycleTime" 0;
BA_DEF_DEF_  "GenMsgSendType" "NoMsgSendType";
BA_DEF_DEF_  "U_U55X_MY2022_Tx" "No";
BA_DEF_DEF_  "U_CD542_MY2021_Tx" "No";
BA_DEF_DEF_  "ECGUsedTxSignal" "No";
BA_DEF_DEF_  "U_T6_MCA_MY2020_Tx" "No";
BA_DEF_DEF_  "U_P702_MY2021_Tx" "No";
BA_DEF_DEF_  "U_CX727_MY2021_Tx" "No";
BA_DEF_DEF_  "U_FNV2_IVI_Rx" "No";
BA_DEF_DEF_  "U_U55X_MY2022_Rx" "No";
BA_DEF_DEF_  "U_CD542_MY2021_Rx" "No";
BA_DEF_DEF_  "ECGUsedRxSignal" "No";
BA_DEF_DEF_  "U_T6_MCA_MY2020_Rx" "No";
BA_DEF_DEF_  "U_P702_MY2021_Rx" "No";
BA_DEF_DEF_  "U_CX727_MY2021_Rx" "No";
BA_DEF_DEF_  "GenSigStartValue" 0;
BA_DEF_DEF_  "MetaData" "No";
BA_DEF_DEF_  "ContentDependant" "No";
BA_DEF_DEF_  "GenSigStartValueInteger" 0;
BA_DEF_DEF_  "UsedOnPgmDBC" "Yes";
BA_DEF_DEF_  "WakeupSignal" "No";
BA_DEF_DEF_  "GenSigInactiveValue" 0;
BA_DEF_DEF_  "GenSigSendType" "NoSigSendType";
BA_DEF_DEF_  "OvtpPushApplication" "FALSE";
BA_DEF_DEF_  "SCP_FreshnessValueLength" 64;
BA_DEF_DEF_  "SCP_FreshnessValueTxLength" 11;
BA_DEF_DEF_  "SCP_AuthInfoTxLength" 53;
BA_DEF_DEF_  "GenMsgRoutingTimeoutTime" 0;
BA_DEF_DEF_  "MessageGateway" "No";
BA_DEF_DEF_  "NmAsrMessage" "No";
BA_DEF_DEF_  "DiagState" "No";
BA_DEF_DEF_  "TpTxIndex" 0;
BA_DEF_DEF_  "DiagRequest" "No";
BA_DEF_DEF_  "DiagResponse" "No";
BA_DEF_DEF_  "GenMsgILSupport" "Yes";
BA_ "GenMsgCycleTime" BO_ 722 1000;
BA_ "GenMsgSendType" BO_ 722 5;
BA_ "GenMsgCycleTime" BO_ 721 1000;
BA_ "GenMsgSendType" BO_ 721 5;
BA_ "GenMsgCycleTime" BO_ 720 1000;
BA_ "GenMsgSendType" BO_ 720 5;
BA_ "GenMsgSendType" BO_ 470 1;
BA_ "NetworkInitialization" BO_ 1978 0;
BA_ "GenMsgDelayTime" BO_ 1978 0;
BA_ "GenMsgSendType" BO_ 1978 1;
BA_ "DiagResponse" BO_ 1978 1;
BA_ "GenMsgILSupport" BO_ 1978 0;
BA_ "NetworkInitialization" BO_ 1970 0;
BA_ "GenMsgDelayTime" BO_ 1970 0;
BA_ "GenMsgSendType" BO_ 1970 1;
BA_ "DiagRequest" BO_ 1970 1;
BA_ "GenMsgILSupport" BO_ 1970 0;
BA_ "GenMsgCycleTime" BO_ 758 1000;
BA_ "GenMsgSendType" BO_ 758 5;
BA_ "GenMsgCycleTime" BO_ 760 1000;
BA_ "GenMsgSendType" BO_ 760 5;
BA_ "TpTxIndex" BO_ 705 27;
BA_ "TpTxIndex" BO_ 692 15;
BA_ "NetworkInitialization" BO_ 1837 0;
BA_ "GenMsgDelayTime" BO_ 1837 0;
BA_ "GenMsgSendType" BO_ 1837 1;
BA_ "DiagResponse" BO_ 1837 1;
BA_ "GenMsgILSupport" BO_ 1837 0;
BA_ "GenMsgCycleTime" BO_ 523 1000;
BA_ "GenMsgSendType" BO_ 523 0;
BA_ "FrameRouting" BO_ 942 "FD1_CAN,0x3AE;";
BA_ "FrameGatewayNetwork" BO_ 942 "FD1_CAN";
BA_ "FrameGatewayId" BO_ 942 942;
BA_ "GenMsgCycleTime" BO_ 634 1000;
BA_ "GenMsgSendType" BO_ 634 5;
BA_ "FrameRouting" BO_ 1088 "FD1_CAN,0x440;HS1_CAN,0x440";
BA_ "TpTxIndex" BO_ 706 28;
BA_ "GenMsgCycleTime" BO_ 761 1000;
BA_ "GenMsgSendType" BO_ 761 5;
BA_ "TpTxIndex" BO_ 694 17;
BA_ "GenMsgCycleTime" BO_ 750 1000;
BA_ "GenMsgSendType" BO_ 750 5;
BA_ "TpTxIndex" BO_ 704 31;
BA_ "GenMsgCycleTime" BO_ 725 1000;
BA_ "GenMsgSendType" BO_ 725 5;
BA_ "GenMsgCycleTime" BO_ 1074 1000;
BA_ "GenMsgSendType" BO_ 1074 5;
BA_ "GenMsgCycleTime" BO_ 1014 1000;
BA_ "GenMsgSendType" BO_ 1014 5;
BA_ "GenMsgCycleTime" BO_ 548 1000;
BA_ "GenMsgSendType" BO_ 548 5;
BA_ "GenMsgSendType" BO_ 404 1;
BA_ "TpTxIndex" BO_ 689 12;
BA_ "GenMsgCycleTime" BO_ 1008 1000;
BA_ "GenMsgSendType" BO_ 1008 5;
BA_ "GenMsgCycleTime" BO_ 547 1000;
BA_ "GenMsgSendType" BO_ 547 5;
BA_ "GenMsgCycleTime" BO_ 732 1000;
BA_ "GenMsgSendType" BO_ 732 5;
BA_ "GenMsgCycleTime" BO_ 728 1000;
BA_ "GenMsgSendType" BO_ 728 5;
BA_ "GenMsgSendType" BO_ 489 1;
BA_ "GenMsgCycleTime" BO_ 757 1000;
BA_ "GenMsgSendType" BO_ 757 5;
BA_ "GenMsgCycleTime" BO_ 734 1000;
BA_ "GenMsgSendType" BO_ 734 5;
BA_ "NetworkInitialization" BO_ 1420 0;
BA_ "GenMsgCycleTime" BO_ 1420 1000;
BA_ "GenMsgSendType" BO_ 1420 0;
BA_ "NmAsrMessage" BO_ 1420 1;
BA_ "GenMsgILSupport" BO_ 1420 0;
BA_ "GenMsgCycleTime" BO_ 759 1000;
BA_ "GenMsgSendType" BO_ 759 5;
BA_ "GenMsgSendType" BO_ 144 1;
BA_ "GenMsgCycleTime" BO_ 851 1000;
BA_ "GenMsgSendType" BO_ 851 5;
BA_ "GenMsgCycleTime" BO_ 792 100;
BA_ "GenMsgSendType" BO_ 792 0;
BA_ "GenMsgCycleTime" BO_ 787 1000;
BA_ "GenMsgSendType" BO_ 787 0;
BA_ "TpTxIndex" BO_ 697 12;
BA_ "TpTxIndex" BO_ 700 15;
BA_ "GenMsgCycleTime" BO_ 676 1000;
BA_ "GenMsgSendType" BO_ 676 5;
BA_ "TpTxIndex" BO_ 676 29;
BA_ "GenMsgSendType" BO_ 504 1;
BA_ "GenMsgCycleTime" BO_ 410 1000;
BA_ "GenMsgSendType" BO_ 410 5;
BA_ "GenMsgSendType" BO_ 1124 1;
BA_ "GenMsgSendType" BO_ 1123 1;
BA_ "GenMsgSendType" BO_ 1122 1;
BA_ "GenMsgCycleTime" BO_ 1131 1000;
BA_ "GenMsgSendType" BO_ 1131 5;
BA_ "GenMsgCycleTime" BO_ 1136 100;
BA_ "GenMsgSendType" BO_ 1136 0;
BA_ "FrameRouting" BO_ 1106 "HS2_CAN,0x452;";
BA_ "FrameGatewayNetwork" BO_ 1106 "HS2_CAN";
BA_ "FrameGatewayId" BO_ 1106 1106;
BA_ "FrameRouting" BO_ 1086 "FD1_CAN,0x43E;HS1_CAN,0x43E";
BA_ "FrameGatewayNetwork" BO_ 1086 "FD1_CAN";
BA_ "FrameGatewayId" BO_ 1086 1086;
BA_ "FrameRouting" BO_ 817 "HS1_CAN,0x331;";
BA_ "FrameGatewayNetwork" BO_ 817 "HS1_CAN";
BA_ "FrameGatewayId" BO_ 817 817;
BA_ "FrameRouting" BO_ 611 "FD1_CAN,0x263;HS1_CAN,0x263";
BA_ "FrameGatewayNetwork" BO_ 611 "FD1_CAN";
BA_ "FrameGatewayId" BO_ 611 611;
BA_ "U_CD542_MY2021_Tx" SG_ 722 VRM_ComShuffleTrack_St 1;
BA_ "U_T6_MCA_MY2020_Tx" SG_ 722 VRM_ComShuffleTrack_St 1;
BA_ "GenSigSendType" SG_ 722 VRM_ComShuffleTrack_St 3;
BA_ "U_CD542_MY2021_Tx" SG_ 722 VRM_ComCompression_St 1;
BA_ "U_T6_MCA_MY2020_Tx" SG_ 722 VRM_ComCompression_St 1;
BA_ "GenSigSendType" SG_ 722 VRM_ComCompression_St 3;
BA_ "U_CD542_MY2021_Tx" SG_ 722 VRM_ComStFreqMode_St 1;
BA_ "U_T6_MCA_MY2020_Tx" SG_ 722 VRM_ComStFreqMode_St 1;
BA_ "GenSigSendType" SG_ 722 VRM_ComStFreqMode_St 3;
BA_ "U_CD542_MY2021_Tx" SG_ 722 VRM_ComAutostore_St 1;
BA_ "U_T6_MCA_MY2020_Tx" SG_ 722 VRM_ComAutostore_St 1;
BA_ "GenSigSendType" SG_ 722 VRM_ComAutostore_St 3;
BA_ "U_CD542_MY2021_Tx" SG_ 722 VRM_ComBand_St 1;
BA_ "U_T6_MCA_MY2020_Tx" SG_ 722 VRM_ComBand_St 1;
BA_ "GenSigSendType" SG_ 722 VRM_ComBand_St 3;
BA_ "U_CD542_MY2021_Tx" SG_ 722 VRM_TMCVoice 1;
BA_ "U_T6_MCA_MY2020_Tx" SG_ 722 VRM_TMCVoice 1;
BA_ "GenSigSendType" SG_ 722 VRM_TMCVoice 3;
BA_ "U_CD542_MY2021_Tx" SG_ 722 VRM_NewSMS 1;
BA_ "U_T6_MCA_MY2020_Tx" SG_ 722 VRM_NewSMS 1;
BA_ "U_CD542_MY2021_Rx" SG_ 722 VRM_NewSMS 1;
BA_ "U_T6_MCA_MY2020_Rx" SG_ 722 VRM_NewSMS 1;
BA_ "GenSigSendType" SG_ 722 VRM_NewSMS 3;
BA_ "U_CD542_MY2021_Tx" SG_ 722 VRM_ComRSEDisplay_St 1;
BA_ "U_T6_MCA_MY2020_Tx" SG_ 722 VRM_ComRSEDisplay_St 1;
BA_ "GenSigSendType" SG_ 722 VRM_ComRSEDisplay_St 3;
BA_ "U_CD542_MY2021_Tx" SG_ 722 VRM_ComPICode_St 1;
BA_ "U_T6_MCA_MY2020_Tx" SG_ 722 VRM_ComPICode_St 1;
BA_ "U_CD542_MY2021_Tx" SG_ 722 VRM_ComPresetCall_St 1;
BA_ "U_T6_MCA_MY2020_Tx" SG_ 722 VRM_ComPresetCall_St 1;
BA_ "GenSigSendType" SG_ 722 VRM_ComPresetCall_St 3;
BA_ "U_CD542_MY2021_Tx" SG_ 722 VRM_ComTape_St 1;
BA_ "U_T6_MCA_MY2020_Tx" SG_ 722 VRM_ComTape_St 1;
BA_ "GenSigSendType" SG_ 722 VRM_ComTape_St 3;
BA_ "U_CD542_MY2021_Tx" SG_ 722 VRM_ComShuffleDiscs_St 1;
BA_ "U_T6_MCA_MY2020_Tx" SG_ 722 VRM_ComShuffleDiscs_St 1;
BA_ "GenSigSendType" SG_ 722 VRM_ComShuffleDiscs_St 3;
BA_ "U_CD542_MY2021_Tx" SG_ 722 VRM_ComDolbyNR_St 1;
BA_ "U_T6_MCA_MY2020_Tx" SG_ 722 VRM_ComDolbyNR_St 1;
BA_ "GenSigSendType" SG_ 722 VRM_ComDolbyNR_St 3;
BA_ "U_CD542_MY2021_Tx" SG_ 722 VRM_ComSourceSelect_St 1;
BA_ "U_T6_MCA_MY2020_Tx" SG_ 722 VRM_ComSourceSelect_St 1;
BA_ "GenSigSendType" SG_ 722 VRM_ComSourceSelect_St 3;
BA_ "U_CD542_MY2021_Tx" SG_ 722 VRM_ComStFreq_St 1;
BA_ "U_T6_MCA_MY2020_Tx" SG_ 722 VRM_ComStFreq_St 1;
BA_ "U_CD542_MY2021_Tx" SG_ 722 VRM_ComRouteStrategy_St 1;
BA_ "U_T6_MCA_MY2020_Tx" SG_ 722 VRM_ComRouteStrategy_St 1;
BA_ "GenSigSendType" SG_ 722 VRM_ComRouteStrategy_St 3;
BA_ "U_CD542_MY2021_Tx" SG_ 721 VRM_BTDefaultPhone_St 1;
BA_ "U_T6_MCA_MY2020_Tx" SG_ 721 VRM_BTDefaultPhone_St 1;
BA_ "U_CD542_MY2021_Rx" SG_ 721 VRM_BTDefaultPhone_St 1;
BA_ "U_T6_MCA_MY2020_Rx" SG_ 721 VRM_BTDefaultPhone_St 1;
BA_ "GenSigSendType" SG_ 721 VRM_BTDefaultPhone_St 3;
BA_ "U_CD542_MY2021_Tx" SG_ 721 VRM_DetourUnit_st 1;
BA_ "U_T6_MCA_MY2020_Tx" SG_ 721 VRM_DetourUnit_st 1;
BA_ "GenSigSendType" SG_ 721 VRM_DetourUnit_st 3;
BA_ "U_CD542_MY2021_Tx" SG_ 721 VRM_Zoom_Option_St 1;
BA_ "U_T6_MCA_MY2020_Tx" SG_ 721 VRM_Zoom_Option_St 1;
BA_ "GenSigSendType" SG_ 721 VRM_Zoom_Option_St 3;
BA_ "U_CD542_MY2021_Tx" SG_ 721 VRM_ComBTDTMFTone_St 1;
BA_ "U_T6_MCA_MY2020_Tx" SG_ 721 VRM_ComBTDTMFTone_St 1;
BA_ "GenSigSendType" SG_ 721 VRM_ComBTDTMFTone_St 3;
BA_ "U_CD542_MY2021_Tx" SG_ 721 VRM_SuggestedRoute_St 1;
BA_ "U_T6_MCA_MY2020_Tx" SG_ 721 VRM_SuggestedRoute_St 1;
BA_ "GenSigSendType" SG_ 721 VRM_SuggestedRoute_St 3;
BA_ "U_CD542_MY2021_Tx" SG_ 721 VRM_ComDelWaypoint_St 1;
BA_ "U_T6_MCA_MY2020_Tx" SG_ 721 VRM_ComDelWaypoint_St 1;
BA_ "GenSigSendType" SG_ 721 VRM_ComDelWaypoint_St 3;
BA_ "U_CD542_MY2021_Tx" SG_ 721 VRM_ComSelectDisc_St 1;
BA_ "U_T6_MCA_MY2020_Tx" SG_ 721 VRM_ComSelectDisc_St 1;
BA_ "GenSigSendType" SG_ 721 VRM_ComSelectDisc_St 3;
BA_ "U_CD542_MY2021_Tx" SG_ 721 VRM_ComTelService_St 1;
BA_ "U_T6_MCA_MY2020_Tx" SG_ 721 VRM_ComTelService_St 1;
BA_ "GenSigSendType" SG_ 721 VRM_ComTelService_St 3;
BA_ "U_CD542_MY2021_Tx" SG_ 721 VRM_ComDestHome_St 1;
BA_ "U_T6_MCA_MY2020_Tx" SG_ 721 VRM_ComDestHome_St 1;
BA_ "GenSigSendType" SG_ 721 VRM_ComDestHome_St 3;
BA_ "U_CD542_MY2021_Tx" SG_ 721 VRM_ComSelectTrack_St 1;
BA_ "U_T6_MCA_MY2020_Tx" SG_ 721 VRM_ComSelectTrack_St 1;
BA_ "U_CD542_MY2021_Tx" SG_ 721 VRM_ComShowNavInfo_St 1;
BA_ "U_T6_MCA_MY2020_Tx" SG_ 721 VRM_ComShowNavInfo_St 1;
BA_ "GenSigSendType" SG_ 721 VRM_ComShowNavInfo_St 3;
BA_ "U_CD542_MY2021_Tx" SG_ 721 VRM_VoiceRecStatus_St 1;
BA_ "U_T6_MCA_MY2020_Tx" SG_ 721 VRM_VoiceRecStatus_St 1;
BA_ "GenSigSendType" SG_ 721 VRM_VoiceRecStatus_St 3;
BA_ "U_CD542_MY2021_Tx" SG_ 721 VRM_ComSelTrackSource_St 1;
BA_ "U_T6_MCA_MY2020_Tx" SG_ 721 VRM_ComSelTrackSource_St 1;
BA_ "GenSigSendType" SG_ 721 VRM_ComSelTrackSource_St 3;
BA_ "U_CD542_MY2021_Tx" SG_ 721 VRM_ComDetour_St 1;
BA_ "U_T6_MCA_MY2020_Tx" SG_ 721 VRM_ComDetour_St 1;
BA_ "GenSigSendType" SG_ 721 VRM_ComDetour_St 3;
BA_ "U_CD542_MY2021_Tx" SG_ 721 VRM_ComDisplay_St 1;
BA_ "U_T6_MCA_MY2020_Tx" SG_ 721 VRM_ComDisplay_St 1;
BA_ "GenSigSendType" SG_ 721 VRM_ComDisplay_St 3;
BA_ "U_CD542_MY2021_Tx" SG_ 721 VRM_ComDynamicGuidande_St 1;
BA_ "U_T6_MCA_MY2020_Tx" SG_ 721 VRM_ComDynamicGuidande_St 1;
BA_ "GenSigSendType" SG_ 721 VRM_ComDynamicGuidande_St 3;
BA_ "U_CD542_MY2021_Tx" SG_ 721 VRM_ComZoom_St 1;
BA_ "U_T6_MCA_MY2020_Tx" SG_ 721 VRM_ComZoom_St 1;
BA_ "GenSigSendType" SG_ 721 VRM_ComZoom_St 3;
BA_ "U_CD542_MY2021_Tx" SG_ 721 VRM_ComCallControl_St 1;
BA_ "U_T6_MCA_MY2020_Tx" SG_ 721 VRM_ComCallControl_St 1;
BA_ "GenSigSendType" SG_ 721 VRM_ComCallControl_St 3;
BA_ "U_CD542_MY2021_Tx" SG_ 721 VRM_ComGuidance_St 1;
BA_ "U_T6_MCA_MY2020_Tx" SG_ 721 VRM_ComGuidance_St 1;
BA_ "GenSigSendType" SG_ 721 VRM_ComGuidance_St 3;
BA_ "U_CD542_MY2021_Tx" SG_ 721 VRM_ComTrafficInfDsp_St 1;
BA_ "U_T6_MCA_MY2020_Tx" SG_ 721 VRM_ComTrafficInfDsp_St 1;
BA_ "GenSigSendType" SG_ 721 VRM_ComTrafficInfDsp_St 3;
BA_ "U_CD542_MY2021_Tx" SG_ 720 VRM_PhMicrophoneMute_St 1;
BA_ "U_T6_MCA_MY2020_Tx" SG_ 720 VRM_PhMicrophoneMute_St 1;
BA_ "U_CD542_MY2021_Rx" SG_ 720 VRM_PhMicrophoneMute_St 1;
BA_ "U_T6_MCA_MY2020_Rx" SG_ 720 VRM_PhMicrophoneMute_St 1;
BA_ "GenSigSendType" SG_ 720 VRM_PhMicrophoneMute_St 3;
BA_ "U_CD542_MY2021_Tx" SG_ 720 Aioc_ExtSrcOutpMode_St 1;
BA_ "U_T6_MCA_MY2020_Tx" SG_ 720 Aioc_ExtSrcOutpMode_St 1;
BA_ "GenSigSendType" SG_ 720 Aioc_ExtSrcOutpMode_St 3;
BA_ "U_CD542_MY2021_Tx" SG_ 720 VRM_BTPhoneSts_St 1;
BA_ "U_T6_MCA_MY2020_Tx" SG_ 720 VRM_BTPhoneSts_St 1;
BA_ "U_U55X_MY2022_Rx" SG_ 720 VRM_BTPhoneSts_St 1;
BA_ "ECGUsedRxSignal" SG_ 720 VRM_BTPhoneSts_St 1;
BA_ "U_CD542_MY2021_Rx" SG_ 720 VRM_BTPhoneSts_St 1;
BA_ "U_T6_MCA_MY2020_Rx" SG_ 720 VRM_BTPhoneSts_St 1;
BA_ "GenSigSendType" SG_ 720 VRM_BTPhoneSts_St 3;
BA_ "U_CD542_MY2021_Tx" SG_ 720 VRM_SubscribeStatus_St 1;
BA_ "U_T6_MCA_MY2020_Tx" SG_ 720 VRM_SubscribeStatus_St 1;
BA_ "GenSigSendType" SG_ 720 VRM_SubscribeStatus_St 3;
BA_ "U_CD542_MY2021_Tx" SG_ 720 VRM_BlutoothStatus_St 1;
BA_ "U_T6_MCA_MY2020_Tx" SG_ 720 VRM_BlutoothStatus_St 1;
BA_ "U_CD542_MY2021_Rx" SG_ 720 VRM_BlutoothStatus_St 1;
BA_ "U_T6_MCA_MY2020_Rx" SG_ 720 VRM_BlutoothStatus_St 1;
BA_ "GenSigSendType" SG_ 720 VRM_BlutoothStatus_St 3;
BA_ "U_CD542_MY2021_Tx" SG_ 720 VRM_BondRequest_St 1;
BA_ "U_T6_MCA_MY2020_Tx" SG_ 720 VRM_BondRequest_St 1;
BA_ "GenSigSendType" SG_ 720 VRM_BondRequest_St 3;
BA_ "U_CD542_MY2021_Tx" SG_ 720 VRM_VRMMonoOutMode_St 1;
BA_ "U_T6_MCA_MY2020_Tx" SG_ 720 VRM_VRMMonoOutMode_St 1;
BA_ "GenSigSendType" SG_ 720 VRM_VRMMonoOutMode_St 3;
BA_ "U_CD542_MY2021_Tx" SG_ 720 VRM_BTNetworkStatus_St 1;
BA_ "U_T6_MCA_MY2020_Tx" SG_ 720 VRM_BTNetworkStatus_St 1;
BA_ "U_CD542_MY2021_Rx" SG_ 720 VRM_BTNetworkStatus_St 1;
BA_ "U_T6_MCA_MY2020_Rx" SG_ 720 VRM_BTNetworkStatus_St 1;
BA_ "GenSigSendType" SG_ 720 VRM_BTNetworkStatus_St 3;
BA_ "U_CD542_MY2021_Tx" SG_ 720 VRM_BTSignalStrength_St 1;
BA_ "U_T6_MCA_MY2020_Tx" SG_ 720 VRM_BTSignalStrength_St 1;
BA_ "U_CD542_MY2021_Rx" SG_ 720 VRM_BTSignalStrength_St 1;
BA_ "U_T6_MCA_MY2020_Rx" SG_ 720 VRM_BTSignalStrength_St 1;
BA_ "GenSigSendType" SG_ 720 VRM_BTSignalStrength_St 3;
BA_ "U_CD542_MY2021_Tx" SG_ 720 VRM_BTBatteryLevel_St 1;
BA_ "U_T6_MCA_MY2020_Tx" SG_ 720 VRM_BTBatteryLevel_St 1;
BA_ "U_CD542_MY2021_Rx" SG_ 720 VRM_BTBatteryLevel_St 1;
BA_ "U_T6_MCA_MY2020_Rx" SG_ 720 VRM_BTBatteryLevel_St 1;
BA_ "GenSigSendType" SG_ 720 VRM_BTBatteryLevel_St 3;
BA_ "U_CD542_MY2021_Tx" SG_ 470 VRM_BTIncomingCall_Rsp 1;
BA_ "U_T6_MCA_MY2020_Tx" SG_ 470 VRM_BTIncomingCall_Rsp 1;
BA_ "U_CD542_MY2021_Rx" SG_ 470 VRM_BTIncomingCall_Rsp 1;
BA_ "U_T6_MCA_MY2020_Rx" SG_ 470 VRM_BTIncomingCall_Rsp 1;
BA_ "GenSigSendType" SG_ 470 VRM_BTIncomingCall_Rsp 3;
BA_ "U_CD542_MY2021_Tx" SG_ 470 VRM_BTEndTelService_Rsp 1;
BA_ "U_T6_MCA_MY2020_Tx" SG_ 470 VRM_BTEndTelService_Rsp 1;
BA_ "U_CD542_MY2021_Rx" SG_ 470 VRM_BTEndTelService_Rsp 1;
BA_ "U_T6_MCA_MY2020_Rx" SG_ 470 VRM_BTEndTelService_Rsp 1;
BA_ "GenSigSendType" SG_ 470 VRM_BTEndTelService_Rsp 3;
BA_ "U_T6_MCA_MY2020_Tx" SG_ 1978 TesterPhysicalResHUD_ADV 1;
BA_ "GenSigSendType" SG_ 1978 TesterPhysicalResHUD_ADV 3;
BA_ "U_T6_MCA_MY2020_Rx" SG_ 1970 TesterPhysicalReqHUD_ADV 1;
BA_ "GenSigSendType" SG_ 1970 TesterPhysicalReqHUD_ADV 3;
BA_ "U_CD542_MY2021_Tx" SG_ 758 SDARS_OpMode_St 1;
BA_ "U_T6_MCA_MY2020_Tx" SG_ 758 SDARS_OpMode_St 1;
BA_ "U_P702_MY2021_Tx" SG_ 758 SDARS_OpMode_St 1;
BA_ "U_CD542_MY2021_Rx" SG_ 758 SDARS_OpMode_St 1;
BA_ "U_T6_MCA_MY2020_Rx" SG_ 758 SDARS_OpMode_St 1;
BA_ "GenSigSendType" SG_ 758 SDARS_OpMode_St 3;
BA_ "U_CD542_MY2021_Tx" SG_ 758 SDARS_SetCategory_St 1;
BA_ "U_T6_MCA_MY2020_Tx" SG_ 758 SDARS_SetCategory_St 1;
BA_ "U_P702_MY2021_Tx" SG_ 758 SDARS_SetCategory_St 1;
BA_ "U_CD542_MY2021_Rx" SG_ 758 SDARS_SetCategory_St 1;
BA_ "U_T6_MCA_MY2020_Rx" SG_ 758 SDARS_SetCategory_St 1;
BA_ "GenSigSendType" SG_ 758 SDARS_SetCategory_St 3;
BA_ "U_CD542_MY2021_Tx" SG_ 758 SDARS_GCI_Update_Prg_St 1;
BA_ "U_T6_MCA_MY2020_Tx" SG_ 758 SDARS_GCI_Update_Prg_St 1;
BA_ "U_P702_MY2021_Tx" SG_ 758 SDARS_GCI_Update_Prg_St 1;
BA_ "U_CD542_MY2021_Rx" SG_ 758 SDARS_GCI_Update_Prg_St 1;
BA_ "U_T6_MCA_MY2020_Rx" SG_ 758 SDARS_GCI_Update_Prg_St 1;
BA_ "GenSigSendType" SG_ 758 SDARS_GCI_Update_Prg_St 3;
BA_ "U_CD542_MY2021_Tx" SG_ 758 SDARS_Factory_Reset_St 1;
BA_ "U_T6_MCA_MY2020_Tx" SG_ 758 SDARS_Factory_Reset_St 1;
BA_ "U_P702_MY2021_Tx" SG_ 758 SDARS_Factory_Reset_St 1;
BA_ "U_CD542_MY2021_Rx" SG_ 758 SDARS_Factory_Reset_St 1;
BA_ "U_T6_MCA_MY2020_Rx" SG_ 758 SDARS_Factory_Reset_St 1;
BA_ "GenSigSendType" SG_ 758 SDARS_Factory_Reset_St 3;
BA_ "U_CD542_MY2021_Tx" SG_ 760 SDARS_SID_St 1;
BA_ "U_T6_MCA_MY2020_Tx" SG_ 760 SDARS_SID_St 1;
BA_ "U_P702_MY2021_Tx" SG_ 760 SDARS_SID_St 1;
BA_ "U_CD542_MY2021_Rx" SG_ 760 SDARS_SID_St 1;
BA_ "U_T6_MCA_MY2020_Rx" SG_ 760 SDARS_SID_St 1;
BA_ "U_CD542_MY2021_Tx" SG_ 760 SDARS_CurrentChanNum_St 1;
BA_ "U_T6_MCA_MY2020_Tx" SG_ 760 SDARS_CurrentChanNum_St 1;
BA_ "U_P702_MY2021_Tx" SG_ 760 SDARS_CurrentChanNum_St 1;
BA_ "U_CD542_MY2021_Rx" SG_ 760 SDARS_CurrentChanNum_St 1;
BA_ "U_T6_MCA_MY2020_Rx" SG_ 760 SDARS_CurrentChanNum_St 1;
BA_ "U_CD542_MY2021_Tx" SG_ 760 SDARS_Buffer_sec_St 1;
BA_ "U_T6_MCA_MY2020_Tx" SG_ 760 SDARS_Buffer_sec_St 1;
BA_ "U_P702_MY2021_Tx" SG_ 760 SDARS_Buffer_sec_St 1;
BA_ "U_CD542_MY2021_Rx" SG_ 760 SDARS_Buffer_sec_St 1;
BA_ "U_T6_MCA_MY2020_Rx" SG_ 760 SDARS_Buffer_sec_St 1;
BA_ "U_CD542_MY2021_Tx" SG_ 760 SDARS_Buffer_min_St 1;
BA_ "U_T6_MCA_MY2020_Tx" SG_ 760 SDARS_Buffer_min_St 1;
BA_ "U_P702_MY2021_Tx" SG_ 760 SDARS_Buffer_min_St 1;
BA_ "U_CD542_MY2021_Rx" SG_ 760 SDARS_Buffer_min_St 1;
BA_ "U_T6_MCA_MY2020_Rx" SG_ 760 SDARS_Buffer_min_St 1;
BA_ "U_CD542_MY2021_Tx" SG_ 760 SDARS_Buffer_hr_St 1;
BA_ "U_T6_MCA_MY2020_Tx" SG_ 760 SDARS_Buffer_hr_St 1;
BA_ "U_P702_MY2021_Tx" SG_ 760 SDARS_Buffer_hr_St 1;
BA_ "U_CD542_MY2021_Rx" SG_ 760 SDARS_Buffer_hr_St 1;
BA_ "U_T6_MCA_MY2020_Rx" SG_ 760 SDARS_Buffer_hr_St 1;
BA_ "U_CD542_MY2021_Tx" SG_ 760 SDARS_Playback_St 1;
BA_ "U_T6_MCA_MY2020_Tx" SG_ 760 SDARS_Playback_St 1;
BA_ "U_P702_MY2021_Tx" SG_ 760 SDARS_Playback_St 1;
BA_ "U_CD542_MY2021_Rx" SG_ 760 SDARS_Playback_St 1;
BA_ "U_T6_MCA_MY2020_Rx" SG_ 760 SDARS_Playback_St 1;
BA_ "U_CD542_MY2021_Tx" SG_ 760 SDARS_FillPosition_St 1;
BA_ "U_T6_MCA_MY2020_Tx" SG_ 760 SDARS_FillPosition_St 1;
BA_ "U_P702_MY2021_Tx" SG_ 760 SDARS_FillPosition_St 1;
BA_ "U_CD542_MY2021_Rx" SG_ 760 SDARS_FillPosition_St 1;
BA_ "U_T6_MCA_MY2020_Rx" SG_ 760 SDARS_FillPosition_St 1;
BA_ "U_CD542_MY2021_Tx" SG_ 760 SDARS_Alert_Status 1;
BA_ "U_T6_MCA_MY2020_Tx" SG_ 760 SDARS_Alert_Status 1;
BA_ "U_P702_MY2021_Tx" SG_ 760 SDARS_Alert_Status 1;
BA_ "U_CD542_MY2021_Rx" SG_ 760 SDARS_Alert_Status 1;
BA_ "U_T6_MCA_MY2020_Rx" SG_ 760 SDARS_Alert_Status 1;
BA_ "GenSigSendType" SG_ 760 SDARS_Alert_Status 3;
BA_ "U_CD542_MY2021_Tx" SG_ 760 SDARS_Channel_Lock 1;
BA_ "U_T6_MCA_MY2020_Tx" SG_ 760 SDARS_Channel_Lock 1;
BA_ "U_P702_MY2021_Tx" SG_ 760 SDARS_Channel_Lock 1;
BA_ "U_CD542_MY2021_Rx" SG_ 760 SDARS_Channel_Lock 1;
BA_ "U_T6_MCA_MY2020_Rx" SG_ 760 SDARS_Channel_Lock 1;
BA_ "GenSigSendType" SG_ 760 SDARS_Channel_Lock 3;
BA_ "U_CD542_MY2021_Tx" SG_ 705 SDARS_RDISP_WORD_Tx 1;
BA_ "U_T6_MCA_MY2020_Tx" SG_ 705 SDARS_RDISP_WORD_Tx 1;
BA_ "U_P702_MY2021_Tx" SG_ 705 SDARS_RDISP_WORD_Tx 1;
BA_ "U_CD542_MY2021_Rx" SG_ 705 SDARS_RDISP_WORD_Tx 1;
BA_ "U_T6_MCA_MY2020_Rx" SG_ 705 SDARS_RDISP_WORD_Tx 1;
BA_ "U_P702_MY2021_Rx" SG_ 705 SDARS_RDISP_WORD_Tx 1;
BA_ "U_CD542_MY2021_Tx" SG_ 692 AUDIO_RDISP_WORD_Tx 1;
BA_ "U_T6_MCA_MY2020_Tx" SG_ 692 AUDIO_RDISP_WORD_Tx 1;
BA_ "U_P702_MY2021_Tx" SG_ 692 AUDIO_RDISP_WORD_Tx 1;
BA_ "U_CD542_MY2021_Rx" SG_ 692 AUDIO_RDISP_WORD_Tx 1;
BA_ "U_T6_MCA_MY2020_Rx" SG_ 692 AUDIO_RDISP_WORD_Tx 1;
BA_ "U_P702_MY2021_Rx" SG_ 692 AUDIO_RDISP_WORD_Tx 1;
BA_ "U_T6_MCA_MY2020_Tx" SG_ 1837 TesterPhysicalResWCM 1;
BA_ "U_P702_MY2021_Tx" SG_ 1837 TesterPhysicalResWCM 1;
BA_ "U_CX727_MY2021_Tx" SG_ 1837 TesterPhysicalResWCM 1;
BA_ "GenSigSendType" SG_ 1837 TesterPhysicalResWCM 3;
BA_ "U_CD542_MY2021_Rx" SG_ 523 WaterInFuel_B_Falt_UB 1;
BA_ "U_T6_MCA_MY2020_Rx" SG_ 523 WaterInFuel_B_Falt_UB 1;
BA_ "U_P702_MY2021_Rx" SG_ 523 WaterInFuel_B_Falt_UB 1;
BA_ "U_CD542_MY2021_Rx" SG_ 523 WaterInFuel_B_Falt 1;
BA_ "U_T6_MCA_MY2020_Rx" SG_ 523 WaterInFuel_B_Falt 1;
BA_ "U_P702_MY2021_Rx" SG_ 523 WaterInFuel_B_Falt 1;
BA_ "U_CD542_MY2021_Rx" SG_ 523 UreaMxAdd_L2_Actl_UB 1;
BA_ "U_T6_MCA_MY2020_Rx" SG_ 523 UreaMxAdd_L2_Actl_UB 1;
BA_ "U_P702_MY2021_Rx" SG_ 523 UreaMxAdd_L2_Actl_UB 1;
BA_ "U_CD542_MY2021_Rx" SG_ 523 VehUreaRnge3_L_DsplyMx_UB 1;
BA_ "U_T6_MCA_MY2020_Rx" SG_ 523 VehUreaRnge3_L_DsplyMx_UB 1;
BA_ "U_P702_MY2021_Rx" SG_ 523 VehUreaRnge3_L_DsplyMx_UB 1;
BA_ "U_CD542_MY2021_Rx" SG_ 523 UreaMnAdd_L2_Actl_UB 1;
BA_ "U_T6_MCA_MY2020_Rx" SG_ 523 UreaMnAdd_L2_Actl_UB 1;
BA_ "U_P702_MY2021_Rx" SG_ 523 UreaMnAdd_L2_Actl_UB 1;
BA_ "U_CD542_MY2021_Rx" SG_ 523 UreaMnAdd_L2_Actl 1;
BA_ "U_T6_MCA_MY2020_Rx" SG_ 523 UreaMnAdd_L2_Actl 1;
BA_ "U_P702_MY2021_Rx" SG_ 523 UreaMnAdd_L2_Actl 1;
BA_ "U_CD542_MY2021_Rx" SG_ 523 VehUreaRnge3_L_DsplyMx 1;
BA_ "U_T6_MCA_MY2020_Rx" SG_ 523 VehUreaRnge3_L_DsplyMx 1;
BA_ "U_P702_MY2021_Rx" SG_ 523 VehUreaRnge3_L_DsplyMx 1;
BA_ "U_CD542_MY2021_Rx" SG_ 523 UreaMxAdd_L2_Actl 1;
BA_ "U_T6_MCA_MY2020_Rx" SG_ 523 UreaMxAdd_L2_Actl 1;
BA_ "U_P702_MY2021_Rx" SG_ 523 UreaMxAdd_L2_Actl 1;
BA_ "GenSigStartValue" SG_ 523 UreaMxAdd_L2_Actl 510;
BA_ "GenSigStartValueInteger" SG_ 523 UreaMxAdd_L2_Actl 510;
BA_ "U_T6_MCA_MY2020_Rx" SG_ 942 PrkAidAcsyRear_D_Stat 1;
BA_ "U_P702_MY2021_Rx" SG_ 942 PrkAidAcsyRear_D_Stat 1;
BA_ "U_T6_MCA_MY2020_Rx" SG_ 942 PrkAidAcsyFront_D_Stat 1;
BA_ "U_P702_MY2021_Rx" SG_ 942 PrkAidAcsyFront_D_Stat 1;
BA_ "U_CD542_MY2021_Rx" SG_ 942 PrkAidRdiusRight_L_Dsply 1;
BA_ "U_T6_MCA_MY2020_Rx" SG_ 942 PrkAidRdiusRight_L_Dsply 1;
BA_ "U_P702_MY2021_Rx" SG_ 942 PrkAidRdiusRight_L_Dsply 1;
BA_ "U_CD542_MY2021_Rx" SG_ 942 PrkAidRdiusLeft_L_Dsply 1;
BA_ "U_T6_MCA_MY2020_Rx" SG_ 942 PrkAidRdiusLeft_L_Dsply 1;
BA_ "U_P702_MY2021_Rx" SG_ 942 PrkAidRdiusLeft_L_Dsply 1;
BA_ "U_CD542_MY2021_Rx" SG_ 942 PrkAidDrvDir_D_Stat 1;
BA_ "U_T6_MCA_MY2020_Rx" SG_ 942 PrkAidDrvDir_D_Stat 1;
BA_ "U_P702_MY2021_Rx" SG_ 942 PrkAidDrvDir_D_Stat 1;
BA_ "U_CD542_MY2021_Rx" SG_ 634 EngAirFiltMsgTxt_D_Rq_UB 1;
BA_ "U_T6_MCA_MY2020_Rx" SG_ 634 EngAirFiltMsgTxt_D_Rq_UB 1;
BA_ "U_P702_MY2021_Rx" SG_ 634 EngAirFiltMsgTxt_D_Rq_UB 1;
BA_ "U_CD542_MY2021_Rx" SG_ 634 EngAirFiltMsgTxt_D_Rq 1;
BA_ "U_T6_MCA_MY2020_Rx" SG_ 634 EngAirFiltMsgTxt_D_Rq 1;
BA_ "U_P702_MY2021_Rx" SG_ 634 EngAirFiltMsgTxt_D_Rq 1;
BA_ "U_CD542_MY2021_Rx" SG_ 634 AutoHoldSwMde_B_Ind_UB 1;
BA_ "U_T6_MCA_MY2020_Rx" SG_ 634 AutoHoldSwMde_B_Ind_UB 1;
BA_ "U_P702_MY2021_Rx" SG_ 634 AutoHoldSwMde_B_Ind_UB 1;
BA_ "U_CD542_MY2021_Rx" SG_ 634 AutoHoldSwMde_B_Ind 1;
BA_ "U_T6_MCA_MY2020_Rx" SG_ 634 AutoHoldSwMde_B_Ind 1;
BA_ "U_P702_MY2021_Rx" SG_ 634 AutoHoldSwMde_B_Ind 1;
BA_ "GenSigSendType" SG_ 634 AutoHoldSwMde_B_Ind 3;
BA_ "ContentDependant" SG_ 634 AutoHoldSwMde_B_Ind 1;
BA_ "U_CD542_MY2021_Rx" SG_ 634 Ccd_B_Falt_UB 1;
BA_ "U_T6_MCA_MY2020_Rx" SG_ 634 Ccd_B_Falt_UB 1;
BA_ "U_CD542_MY2021_Rx" SG_ 634 Ccd_B_Falt 1;
BA_ "U_T6_MCA_MY2020_Rx" SG_ 634 Ccd_B_Falt 1;
BA_ "GenSigSendType" SG_ 634 Ccd_B_Falt 3;
BA_ "U_CD542_MY2021_Rx" SG_ 634 RearDiffLckLamp_D_Rq3_UB 1;
BA_ "U_T6_MCA_MY2020_Rx" SG_ 634 RearDiffLckLamp_D_Rq3_UB 1;
BA_ "U_CD542_MY2021_Rx" SG_ 634 AwdLckLamp_D_Rq_UB 1;
BA_ "U_T6_MCA_MY2020_Rx" SG_ 634 AwdLckLamp_D_Rq_UB 1;
BA_ "U_CD542_MY2021_Rx" SG_ 634 RearDiffLckLamp_D_Rq3 1;
BA_ "U_T6_MCA_MY2020_Rx" SG_ 634 RearDiffLckLamp_D_Rq3 1;
BA_ "GenSigSendType" SG_ 634 RearDiffLckLamp_D_Rq3 3;
BA_ "U_CD542_MY2021_Rx" SG_ 634 AwdLckLamp_D_Rq 1;
BA_ "U_T6_MCA_MY2020_Rx" SG_ 634 AwdLckLamp_D_Rq 1;
BA_ "GenSigSendType" SG_ 634 AwdLckLamp_D_Rq 3;
BA_ "U_CD542_MY2021_Rx" SG_ 634 AutoTowAllw_D_StatMnu_UB 1;
BA_ "U_CD542_MY2021_Rx" SG_ 634 AutoTowAllw_D_StatMnu 1;
BA_ "GenSigSendType" SG_ 634 AutoTowAllw_D_StatMnu 3;
BA_ "U_CD542_MY2021_Rx" SG_ 634 AutoTowActv_B_Stat 1;
BA_ "GenSigSendType" SG_ 634 AutoTowActv_B_Stat 3;
BA_ "U_CD542_MY2021_Rx" SG_ 634 AutoTowActv_B_Stat_UB 1;
BA_ "U_CD542_MY2021_Rx" SG_ 634 LdwChime_B_Rq_UB 1;
BA_ "U_T6_MCA_MY2020_Rx" SG_ 634 LdwChime_B_Rq_UB 1;
BA_ "U_P702_MY2021_Rx" SG_ 634 LdwChime_B_Rq_UB 1;
BA_ "U_CD542_MY2021_Rx" SG_ 634 HdcOn_B_Ind 1;
BA_ "U_T6_MCA_MY2020_Rx" SG_ 634 HdcOn_B_Ind 1;
BA_ "U_P702_MY2021_Rx" SG_ 634 HdcOn_B_Ind 1;
BA_ "GenSigSendType" SG_ 634 HdcOn_B_Ind 3;
BA_ "U_CD542_MY2021_Rx" SG_ 634 HdcOn_B_Ind_UB 1;
BA_ "U_T6_MCA_MY2020_Rx" SG_ 634 HdcOn_B_Ind_UB 1;
BA_ "U_P702_MY2021_Rx" SG_ 634 HdcOn_B_Ind_UB 1;
BA_ "U_CD542_MY2021_Rx" SG_ 634 SuspVLimMsgTxt_B_Rq_UB 1;
BA_ "U_CD542_MY2021_Rx" SG_ 634 SuspVlimMsgTxt_B_Rq 1;
BA_ "U_T6_MCA_MY2020_Rx" SG_ 634 SuspVlimMsgTxt_B_Rq 1;
BA_ "GenSigSendType" SG_ 634 SuspVlimMsgTxt_B_Rq 3;
BA_ "U_CD542_MY2021_Rx" SG_ 634 EngExhMdeQuiet_D2_Stat_UB 1;
BA_ "U_T6_MCA_MY2020_Rx" SG_ 634 EngExhMdeQuiet_D2_Stat_UB 1;
BA_ "U_CD542_MY2021_Rx" SG_ 634 EngExhMdeQuiet_D2_Stat 1;
BA_ "U_T6_MCA_MY2020_Rx" SG_ 634 EngExhMdeQuiet_D2_Stat 1;
BA_ "GenSigSendType" SG_ 634 EngExhMdeQuiet_D2_Stat 3;
BA_ "U_T6_MCA_MY2020_Rx" SG_ 634 ChrgCrdLck_D_Falt_UB 1;
BA_ "U_CD542_MY2021_Rx" SG_ 634 ChrgCrdLck_D_Falt_UB 1;
BA_ "U_CD542_MY2021_Rx" SG_ 634 LdwChime_B_Rq 1;
BA_ "U_T6_MCA_MY2020_Rx" SG_ 634 LdwChime_B_Rq 1;
BA_ "U_P702_MY2021_Rx" SG_ 634 LdwChime_B_Rq 1;
BA_ "GenSigSendType" SG_ 634 LdwChime_B_Rq 3;
BA_ "U_T6_MCA_MY2020_Rx" SG_ 634 ChrgCrdLck_D_Falt 1;
BA_ "U_CD542_MY2021_Rx" SG_ 634 ChrgCrdLck_D_Falt 1;
BA_ "GenSigSendType" SG_ 634 ChrgCrdLck_D_Falt 3;
BA_ "ContentDependant" SG_ 1088 HvacPrecondMode2_D_Rq 1;
BA_ "WakeupSignal" SG_ 1088 HvacPrecondMode2_D_Rq 1;
BA_ "ContentDependant" SG_ 1088 HvacPrecondBlwr2_D_Rq 1;
BA_ "WakeupSignal" SG_ 1088 HvacPrecondBlwr2_D_Rq 1;
BA_ "GenSigStartValue" SG_ 1088 HvacPrecond_Te_Rq 2;
BA_ "GenSigStartValueInteger" SG_ 1088 HvacPrecond_Te_Rq 2;
BA_ "U_P702_MY2021_Rx" SG_ 1088 ChrgStat_D2_Dsply 1;
BA_ "U_CD542_MY2021_Rx" SG_ 1088 ChrgStat_D2_Dsply 1;
BA_ "U_T6_MCA_MY2020_Rx" SG_ 1088 ChrgStat_D2_Dsply 1;
BA_ "U_CD542_MY2021_Rx" SG_ 1088 ChrgTMatch_B_Stat 1;
BA_ "U_T6_MCA_MY2020_Rx" SG_ 1088 ChrgTMatch_B_Stat 1;
BA_ "GenSigStartValue" SG_ 1088 BattDcChrgRms_I_Lim 32766;
BA_ "U_CD542_MY2021_Tx" SG_ 706 SDARS_MC_WORD_Tx 1;
BA_ "U_T6_MCA_MY2020_Tx" SG_ 706 SDARS_MC_WORD_Tx 1;
BA_ "U_P702_MY2021_Tx" SG_ 706 SDARS_MC_WORD_Tx 1;
BA_ "U_CD542_MY2021_Rx" SG_ 706 SDARS_MC_WORD_Tx 1;
BA_ "U_T6_MCA_MY2020_Rx" SG_ 706 SDARS_MC_WORD_Tx 1;
BA_ "U_CD542_MY2021_Tx" SG_ 761 SDARS_Seek_Scan_St 1;
BA_ "U_T6_MCA_MY2020_Tx" SG_ 761 SDARS_Seek_Scan_St 1;
BA_ "U_P702_MY2021_Tx" SG_ 761 SDARS_Seek_Scan_St 1;
BA_ "U_CD542_MY2021_Rx" SG_ 761 SDARS_Seek_Scan_St 1;
BA_ "U_T6_MCA_MY2020_Rx" SG_ 761 SDARS_Seek_Scan_St 1;
BA_ "GenSigSendType" SG_ 761 SDARS_Seek_Scan_St 3;
BA_ "U_CD542_MY2021_Tx" SG_ 761 SDARS_Invalid_Chan_St 1;
BA_ "U_T6_MCA_MY2020_Tx" SG_ 761 SDARS_Invalid_Chan_St 1;
BA_ "U_P702_MY2021_Tx" SG_ 761 SDARS_Invalid_Chan_St 1;
BA_ "U_CD542_MY2021_Rx" SG_ 761 SDARS_Invalid_Chan_St 1;
BA_ "U_T6_MCA_MY2020_Rx" SG_ 761 SDARS_Invalid_Chan_St 1;
BA_ "GenSigSendType" SG_ 761 SDARS_Invalid_Chan_St 3;
BA_ "U_CD542_MY2021_Tx" SG_ 761 SDARS_UnSubscrb_Chan_St 1;
BA_ "U_T6_MCA_MY2020_Tx" SG_ 761 SDARS_UnSubscrb_Chan_St 1;
BA_ "U_P702_MY2021_Tx" SG_ 761 SDARS_UnSubscrb_Chan_St 1;
BA_ "U_CD542_MY2021_Rx" SG_ 761 SDARS_UnSubscrb_Chan_St 1;
BA_ "U_T6_MCA_MY2020_Rx" SG_ 761 SDARS_UnSubscrb_Chan_St 1;
BA_ "GenSigSendType" SG_ 761 SDARS_UnSubscrb_Chan_St 3;
BA_ "U_CD542_MY2021_Tx" SG_ 761 SDARS_Loss_Ant_St 1;
BA_ "U_T6_MCA_MY2020_Tx" SG_ 761 SDARS_Loss_Ant_St 1;
BA_ "U_P702_MY2021_Tx" SG_ 761 SDARS_Loss_Ant_St 1;
BA_ "U_CD542_MY2021_Rx" SG_ 761 SDARS_Loss_Ant_St 1;
BA_ "U_T6_MCA_MY2020_Rx" SG_ 761 SDARS_Loss_Ant_St 1;
BA_ "GenSigSendType" SG_ 761 SDARS_Loss_Ant_St 3;
BA_ "U_CD542_MY2021_Tx" SG_ 761 SDARS_UnSubscrb_St 1;
BA_ "U_T6_MCA_MY2020_Tx" SG_ 761 SDARS_UnSubscrb_St 1;
BA_ "U_P702_MY2021_Tx" SG_ 761 SDARS_UnSubscrb_St 1;
BA_ "U_CD542_MY2021_Rx" SG_ 761 SDARS_UnSubscrb_St 1;
BA_ "U_T6_MCA_MY2020_Rx" SG_ 761 SDARS_UnSubscrb_St 1;
BA_ "GenSigSendType" SG_ 761 SDARS_UnSubscrb_St 3;
BA_ "U_CD542_MY2021_Tx" SG_ 761 SDARS_Subscription_St 1;
BA_ "U_T6_MCA_MY2020_Tx" SG_ 761 SDARS_Subscription_St 1;
BA_ "U_P702_MY2021_Tx" SG_ 761 SDARS_Subscription_St 1;
BA_ "U_CD542_MY2021_Rx" SG_ 761 SDARS_Subscription_St 1;
BA_ "U_T6_MCA_MY2020_Rx" SG_ 761 SDARS_Subscription_St 1;
BA_ "GenSigSendType" SG_ 761 SDARS_Subscription_St 3;
BA_ "U_CD542_MY2021_Tx" SG_ 761 SDARS_GCI_Update_St 1;
BA_ "U_T6_MCA_MY2020_Tx" SG_ 761 SDARS_GCI_Update_St 1;
BA_ "U_P702_MY2021_Tx" SG_ 761 SDARS_GCI_Update_St 1;
BA_ "U_CD542_MY2021_Rx" SG_ 761 SDARS_GCI_Update_St 1;
BA_ "U_T6_MCA_MY2020_Rx" SG_ 761 SDARS_GCI_Update_St 1;
BA_ "GenSigSendType" SG_ 761 SDARS_GCI_Update_St 3;
BA_ "U_T6_MCA_MY2020_Tx" SG_ 761 SDARS_Firmware_Updat_St 1;
BA_ "U_P702_MY2021_Tx" SG_ 761 SDARS_Firmware_Updat_St 1;
BA_ "U_CD542_MY2021_Rx" SG_ 761 SDARS_Firmware_Updat_St 1;
BA_ "U_T6_MCA_MY2020_Rx" SG_ 761 SDARS_Firmware_Updat_St 1;
BA_ "GenSigSendType" SG_ 761 SDARS_Firmware_Updat_St 3;
BA_ "U_CD542_MY2021_Tx" SG_ 761 SDARS_Antenna_Err_St 1;
BA_ "U_T6_MCA_MY2020_Tx" SG_ 761 SDARS_Antenna_Err_St 1;
BA_ "U_P702_MY2021_Tx" SG_ 761 SDARS_Antenna_Err_St 1;
BA_ "U_CD542_MY2021_Rx" SG_ 761 SDARS_Antenna_Err_St 1;
BA_ "U_T6_MCA_MY2020_Rx" SG_ 761 SDARS_Antenna_Err_St 1;
BA_ "GenSigSendType" SG_ 761 SDARS_Antenna_Err_St 3;
BA_ "U_CD542_MY2021_Tx" SG_ 761 SDARS_Receive_Err_St 1;
BA_ "U_T6_MCA_MY2020_Tx" SG_ 761 SDARS_Receive_Err_St 1;
BA_ "U_P702_MY2021_Tx" SG_ 761 SDARS_Receive_Err_St 1;
BA_ "U_CD542_MY2021_Rx" SG_ 761 SDARS_Receive_Err_St 1;
BA_ "U_T6_MCA_MY2020_Rx" SG_ 761 SDARS_Receive_Err_St 1;
BA_ "GenSigSendType" SG_ 761 SDARS_Receive_Err_St 3;
BA_ "U_CD542_MY2021_Tx" SG_ 761 SDARS_Error_Conf_St 1;
BA_ "U_T6_MCA_MY2020_Tx" SG_ 761 SDARS_Error_Conf_St 1;
BA_ "U_P702_MY2021_Tx" SG_ 761 SDARS_Error_Conf_St 1;
BA_ "U_CD542_MY2021_Rx" SG_ 761 SDARS_Error_Conf_St 1;
BA_ "U_T6_MCA_MY2020_Rx" SG_ 761 SDARS_Error_Conf_St 1;
BA_ "GenSigSendType" SG_ 761 SDARS_Error_Conf_St 3;
BA_ "U_CD542_MY2021_Tx" SG_ 694 PHONE_MC_WORD_Tx 1;
BA_ "U_T6_MCA_MY2020_Tx" SG_ 694 PHONE_MC_WORD_Tx 1;
BA_ "U_CD542_MY2021_Rx" SG_ 694 PHONE_MC_WORD_Tx 1;
BA_ "U_T6_MCA_MY2020_Rx" SG_ 694 PHONE_MC_WORD_Tx 1;
BA_ "U_CD542_MY2021_Tx" SG_ 750 LoclFuelEffUnit_D_Stat 1;
BA_ "U_T6_MCA_MY2020_Tx" SG_ 750 LoclFuelEffUnit_D_Stat 1;
BA_ "U_P702_MY2021_Tx" SG_ 750 LoclFuelEffUnit_D_Stat 1;
BA_ "U_CD542_MY2021_Rx" SG_ 750 LoclFuelEffUnit_D_Stat 1;
BA_ "U_T6_MCA_MY2020_Rx" SG_ 750 LoclFuelEffUnit_D_Stat 1;
BA_ "GenSigSendType" SG_ 750 LoclFuelEffUnit_D_Stat 3;
BA_ "U_CD542_MY2021_Tx" SG_ 750 RoadsideAsstAvail_D_St 1;
BA_ "U_T6_MCA_MY2020_Tx" SG_ 750 RoadsideAsstAvail_D_St 1;
BA_ "U_P702_MY2021_Tx" SG_ 750 RoadsideAsstAvail_D_St 1;
BA_ "U_CD542_MY2021_Rx" SG_ 750 RoadsideAsstAvail_D_St 1;
BA_ "U_T6_MCA_MY2020_Rx" SG_ 750 RoadsideAsstAvail_D_St 1;
BA_ "GenSigSendType" SG_ 750 RoadsideAsstAvail_D_St 3;
BA_ "U_CD542_MY2021_Tx" SG_ 750 EmbedNavActive_D_Stat 1;
BA_ "U_T6_MCA_MY2020_Tx" SG_ 750 EmbedNavActive_D_Stat 1;
BA_ "U_P702_MY2021_Tx" SG_ 750 EmbedNavActive_D_Stat 1;
BA_ "U_CD542_MY2021_Rx" SG_ 750 EmbedNavActive_D_Stat 1;
BA_ "U_T6_MCA_MY2020_Rx" SG_ 750 EmbedNavActive_D_Stat 1;
BA_ "GenSigSendType" SG_ 750 EmbedNavActive_D_Stat 3;
BA_ "U_CD542_MY2021_Tx" SG_ 750 UnitOfLength_St 1;
BA_ "U_T6_MCA_MY2020_Tx" SG_ 750 UnitOfLength_St 1;
BA_ "U_P702_MY2021_Tx" SG_ 750 UnitOfLength_St 1;
BA_ "U_CD542_MY2021_Rx" SG_ 750 UnitOfLength_St 1;
BA_ "U_T6_MCA_MY2020_Rx" SG_ 750 UnitOfLength_St 1;
BA_ "GenSigSendType" SG_ 750 UnitOfLength_St 3;
BA_ "U_CD542_MY2021_Tx" SG_ 750 RouteActive_St 1;
BA_ "U_T6_MCA_MY2020_Tx" SG_ 750 RouteActive_St 1;
BA_ "U_P702_MY2021_Tx" SG_ 750 RouteActive_St 1;
BA_ "U_CD542_MY2021_Rx" SG_ 750 RouteActive_St 1;
BA_ "U_T6_MCA_MY2020_Rx" SG_ 750 RouteActive_St 1;
BA_ "GenSigSendType" SG_ 750 RouteActive_St 3;
BA_ "U_CD542_MY2021_Tx" SG_ 750 CancelCurrWaypt_St 1;
BA_ "U_T6_MCA_MY2020_Tx" SG_ 750 CancelCurrWaypt_St 1;
BA_ "U_P702_MY2021_Tx" SG_ 750 CancelCurrWaypt_St 1;
BA_ "U_CD542_MY2021_Rx" SG_ 750 CancelCurrWaypt_St 1;
BA_ "U_T6_MCA_MY2020_Rx" SG_ 750 CancelCurrWaypt_St 1;
BA_ "GenSigSendType" SG_ 750 CancelCurrWaypt_St 3;
BA_ "U_CD542_MY2021_Tx" SG_ 750 Nav_RemainTTDestDays_St 1;
BA_ "U_T6_MCA_MY2020_Tx" SG_ 750 Nav_RemainTTDestDays_St 1;
BA_ "U_P702_MY2021_Tx" SG_ 750 Nav_RemainTTDestDays_St 1;
BA_ "U_CD542_MY2021_Rx" SG_ 750 Nav_RemainTTDestDays_St 1;
BA_ "U_T6_MCA_MY2020_Rx" SG_ 750 Nav_RemainTTDestDays_St 1;
BA_ "GenSigSendType" SG_ 750 Nav_RemainTTDestDays_St 3;
BA_ "U_CD542_MY2021_Tx" SG_ 750 WaypointsActive_St 1;
BA_ "U_T6_MCA_MY2020_Tx" SG_ 750 WaypointsActive_St 1;
BA_ "U_P702_MY2021_Tx" SG_ 750 WaypointsActive_St 1;
BA_ "U_CD542_MY2021_Rx" SG_ 750 WaypointsActive_St 1;
BA_ "U_T6_MCA_MY2020_Rx" SG_ 750 WaypointsActive_St 1;
BA_ "GenSigSendType" SG_ 750 WaypointsActive_St 3;
BA_ "U_CD542_MY2021_Tx" SG_ 750 Nav_RemainTTDestHour_St 1;
BA_ "U_T6_MCA_MY2020_Tx" SG_ 750 Nav_RemainTTDestHour_St 1;
BA_ "U_P702_MY2021_Tx" SG_ 750 Nav_RemainTTDestHour_St 1;
BA_ "U_CD542_MY2021_Rx" SG_ 750 Nav_RemainTTDestHour_St 1;
BA_ "U_T6_MCA_MY2020_Rx" SG_ 750 Nav_RemainTTDestHour_St 1;
BA_ "GenSigSendType" SG_ 750 Nav_RemainTTDestHour_St 3;
BA_ "U_CD542_MY2021_Tx" SG_ 750 Nav_RemainTTDestMin_St 1;
BA_ "U_T6_MCA_MY2020_Tx" SG_ 750 Nav_RemainTTDestMin_St 1;
BA_ "U_P702_MY2021_Tx" SG_ 750 Nav_RemainTTDestMin_St 1;
BA_ "U_CD542_MY2021_Rx" SG_ 750 Nav_RemainTTDestMin_St 1;
BA_ "U_T6_MCA_MY2020_Rx" SG_ 750 Nav_RemainTTDestMin_St 1;
BA_ "GenSigSendType" SG_ 750 Nav_RemainTTDestMin_St 3;
BA_ "U_CD542_MY2021_Tx" SG_ 750 Nav_DistanToDestUnit_St 1;
BA_ "U_T6_MCA_MY2020_Tx" SG_ 750 Nav_DistanToDestUnit_St 1;
BA_ "U_P702_MY2021_Tx" SG_ 750 Nav_DistanToDestUnit_St 1;
BA_ "U_CD542_MY2021_Rx" SG_ 750 Nav_DistanToDestUnit_St 1;
BA_ "U_T6_MCA_MY2020_Rx" SG_ 750 Nav_DistanToDestUnit_St 1;
BA_ "U_CD542_MY2021_Tx" SG_ 750 Nav_DistancToDestVal_St 1;
BA_ "U_T6_MCA_MY2020_Tx" SG_ 750 Nav_DistancToDestVal_St 1;
BA_ "U_P702_MY2021_Tx" SG_ 750 Nav_DistancToDestVal_St 1;
BA_ "U_CD542_MY2021_Rx" SG_ 750 Nav_DistancToDestVal_St 1;
BA_ "U_T6_MCA_MY2020_Rx" SG_ 750 Nav_DistancToDestVal_St 1;
BA_ "GenSigSendType" SG_ 750 Nav_DistancToDestVal_St 3;
BA_ "U_CD542_MY2021_Tx" SG_ 750 NavError_Waypoint_St 1;
BA_ "U_T6_MCA_MY2020_Tx" SG_ 750 NavError_Waypoint_St 1;
BA_ "U_P702_MY2021_Tx" SG_ 750 NavError_Waypoint_St 1;
BA_ "U_CD542_MY2021_Rx" SG_ 750 NavError_Waypoint_St 1;
BA_ "U_T6_MCA_MY2020_Rx" SG_ 750 NavError_Waypoint_St 1;
BA_ "U_CD542_MY2021_Tx" SG_ 704 NAV_MC_WORD_Tx 1;
BA_ "U_T6_MCA_MY2020_Tx" SG_ 704 NAV_MC_WORD_Tx 1;
BA_ "U_T6_MCA_MY2020_Rx" SG_ 704 NAV_MC_WORD_Tx 1;
BA_ "U_CD542_MY2021_Tx" SG_ 725 InfotainmentAudio_St 1;
BA_ "U_T6_MCA_MY2020_Tx" SG_ 725 InfotainmentAudio_St 1;
BA_ "U_P702_MY2021_Tx" SG_ 725 InfotainmentAudio_St 1;
BA_ "U_P702_MY2021_Rx" SG_ 725 InfotainmentAudio_St 1;
BA_ "U_CD542_MY2021_Rx" SG_ 725 InfotainmentAudio_St 1;
BA_ "U_T6_MCA_MY2020_Rx" SG_ 725 InfotainmentAudio_St 1;
BA_ "GenSigSendType" SG_ 725 InfotainmentAudio_St 3;
BA_ "U_T6_MCA_MY2020_Tx" SG_ 725 ACU_CompLogic_St 1;
BA_ "U_P702_MY2021_Tx" SG_ 725 ACU_CompLogic_St 1;
BA_ "GenSigSendType" SG_ 725 ACU_CompLogic_St 3;
BA_ "U_CD542_MY2021_Tx" SG_ 725 ACU_RadioError_St 1;
BA_ "U_T6_MCA_MY2020_Tx" SG_ 725 ACU_RadioError_St 1;
BA_ "U_P702_MY2021_Tx" SG_ 725 ACU_RadioError_St 1;
BA_ "U_P702_MY2021_Rx" SG_ 725 ACU_RadioError_St 1;
BA_ "U_CD542_MY2021_Rx" SG_ 725 ACU_RadioError_St 1;
BA_ "U_T6_MCA_MY2020_Rx" SG_ 725 ACU_RadioError_St 1;
BA_ "GenSigSendType" SG_ 725 ACU_RadioError_St 3;
BA_ "U_CD542_MY2021_Tx" SG_ 725 ACU_HardwareError_St 1;
BA_ "U_T6_MCA_MY2020_Tx" SG_ 725 ACU_HardwareError_St 1;
BA_ "U_P702_MY2021_Tx" SG_ 725 ACU_HardwareError_St 1;
BA_ "U_P702_MY2021_Rx" SG_ 725 ACU_HardwareError_St 1;
BA_ "U_CD542_MY2021_Rx" SG_ 725 ACU_HardwareError_St 1;
BA_ "U_T6_MCA_MY2020_Rx" SG_ 725 ACU_HardwareError_St 1;
BA_ "GenSigSendType" SG_ 725 ACU_HardwareError_St 3;
BA_ "U_CD542_MY2021_Tx" SG_ 725 ACU_CurrentRadioBand_St 1;
BA_ "U_T6_MCA_MY2020_Tx" SG_ 725 ACU_CurrentRadioBand_St 1;
BA_ "U_P702_MY2021_Tx" SG_ 725 ACU_CurrentRadioBand_St 1;
BA_ "U_CD542_MY2021_Rx" SG_ 725 ACU_CurrentRadioBand_St 1;
BA_ "U_T6_MCA_MY2020_Rx" SG_ 725 ACU_CurrentRadioBand_St 1;
BA_ "GenSigSendType" SG_ 725 ACU_CurrentRadioBand_St 3;
BA_ "U_CD542_MY2021_Tx" SG_ 725 ACU_CurrentPTYCode_St 1;
BA_ "U_T6_MCA_MY2020_Tx" SG_ 725 ACU_CurrentPTYCode_St 1;
BA_ "U_P702_MY2021_Tx" SG_ 725 ACU_CurrentPTYCode_St 1;
BA_ "U_P702_MY2021_Rx" SG_ 725 ACU_CurrentPTYCode_St 1;
BA_ "U_CD542_MY2021_Rx" SG_ 725 ACU_CurrentPTYCode_St 1;
BA_ "U_T6_MCA_MY2020_Rx" SG_ 725 ACU_CurrentPTYCode_St 1;
BA_ "GenSigSendType" SG_ 725 ACU_CurrentPTYCode_St 3;
BA_ "U_CD542_MY2021_Tx" SG_ 725 ACU_CurrentPICode_St 1;
BA_ "U_T6_MCA_MY2020_Tx" SG_ 725 ACU_CurrentPICode_St 1;
BA_ "U_P702_MY2021_Tx" SG_ 725 ACU_CurrentPICode_St 1;
BA_ "U_CD542_MY2021_Rx" SG_ 725 ACU_CurrentPICode_St 1;
BA_ "U_T6_MCA_MY2020_Rx" SG_ 725 ACU_CurrentPICode_St 1;
BA_ "U_P702_MY2021_Rx" SG_ 725 ACU_CurrentPICode_St 1;
BA_ "GenSigSendType" SG_ 725 ACU_CurrentPICode_St 3;
BA_ "U_CD542_MY2021_Tx" SG_ 725 ACU_CurrentFreq_St 1;
BA_ "U_T6_MCA_MY2020_Tx" SG_ 725 ACU_CurrentFreq_St 1;
BA_ "U_P702_MY2021_Tx" SG_ 725 ACU_CurrentFreq_St 1;
BA_ "U_CX727_MY2021_Rx" SG_ 725 ACU_CurrentFreq_St 1;
BA_ "U_P702_MY2021_Rx" SG_ 725 ACU_CurrentFreq_St 1;
BA_ "U_CD542_MY2021_Rx" SG_ 725 ACU_CurrentFreq_St 1;
BA_ "U_T6_MCA_MY2020_Rx" SG_ 725 ACU_CurrentFreq_St 1;
BA_ "GenSigSendType" SG_ 725 ACU_CurrentFreq_St 3;
BA_ "U_CD542_MY2021_Tx" SG_ 725 ACU_AFMode_St 1;
BA_ "U_T6_MCA_MY2020_Tx" SG_ 725 ACU_AFMode_St 1;
BA_ "U_P702_MY2021_Tx" SG_ 725 ACU_AFMode_St 1;
BA_ "U_CD542_MY2021_Rx" SG_ 725 ACU_AFMode_St 1;
BA_ "U_T6_MCA_MY2020_Rx" SG_ 725 ACU_AFMode_St 1;
BA_ "U_P702_MY2021_Rx" SG_ 725 ACU_AFMode_St 1;
BA_ "GenSigSendType" SG_ 725 ACU_AFMode_St 3;
BA_ "U_CD542_MY2021_Rx" SG_ 1074 PwLftgtIntSw_B_Stat_UB 1;
BA_ "U_T6_MCA_MY2020_Rx" SG_ 1074 PwLftgtIntSw_B_Stat_UB 1;
BA_ "U_CD542_MY2021_Rx" SG_ 1074 PwLftgtIntSw_B_Stat 1;
BA_ "U_T6_MCA_MY2020_Rx" SG_ 1074 PwLftgtIntSw_B_Stat 1;
BA_ "GenSigSendType" SG_ 1074 PwLftgtIntSw_B_Stat 3;
BA_ "WakeupSignal" SG_ 1074 PwLftgtIntSw_B_Stat 1;
BA_ "U_CD542_MY2021_Rx" SG_ 1074 E_Frt_Btn_Status_1st_UB 1;
BA_ "U_T6_MCA_MY2020_Rx" SG_ 1074 E_Frt_Btn_Status_1st_UB 1;
BA_ "U_CD542_MY2021_Rx" SG_ 1074 E_Frt_Btn_Status_2nd_UB 1;
BA_ "U_T6_MCA_MY2020_Rx" SG_ 1074 E_Frt_Btn_Status_2nd_UB 1;
BA_ "U_CD542_MY2021_Rx" SG_ 1074 E_Frt_Btn_Status_2nd 1;
BA_ "U_T6_MCA_MY2020_Rx" SG_ 1074 E_Frt_Btn_Status_2nd 1;
BA_ "GenSigSendType" SG_ 1074 E_Frt_Btn_Status_2nd 3;
BA_ "U_CD542_MY2021_Rx" SG_ 1074 E_Frt_Btn_Status_1st 1;
BA_ "U_T6_MCA_MY2020_Rx" SG_ 1074 E_Frt_Btn_Status_1st 1;
BA_ "GenSigSendType" SG_ 1074 E_Frt_Btn_Status_1st 3;
BA_ "U_CD542_MY2021_Rx" SG_ 1074 DrLatchRrMsgTxt_D_Rq_UB 1;
BA_ "U_T6_MCA_MY2020_Rx" SG_ 1074 DrLatchRrMsgTxt_D_Rq_UB 1;
BA_ "U_CD542_MY2021_Rx" SG_ 1074 DrLatchRrMsgTxt_D_Rq 1;
BA_ "U_T6_MCA_MY2020_Rx" SG_ 1074 DrLatchRrMsgTxt_D_Rq 1;
BA_ "GenSigSendType" SG_ 1074 DrLatchRrMsgTxt_D_Rq 3;
BA_ "U_CD542_MY2021_Rx" SG_ 1074 DrLatchRlMsgTxt_D_Rq_UB 1;
BA_ "U_T6_MCA_MY2020_Rx" SG_ 1074 DrLatchRlMsgTxt_D_Rq_UB 1;
BA_ "U_CD542_MY2021_Rx" SG_ 1074 DrLatchRlMsgTxt_D_Rq 1;
BA_ "U_T6_MCA_MY2020_Rx" SG_ 1074 DrLatchRlMsgTxt_D_Rq 1;
BA_ "GenSigSendType" SG_ 1074 DrLatchRlMsgTxt_D_Rq 3;
BA_ "U_CD542_MY2021_Rx" SG_ 1074 DrLatchFrMsgTxt_D_Rq_UB 1;
BA_ "U_T6_MCA_MY2020_Rx" SG_ 1074 DrLatchFrMsgTxt_D_Rq_UB 1;
BA_ "U_CD542_MY2021_Rx" SG_ 1074 DrLatchFrMsgTxt_D_Rq 1;
BA_ "U_T6_MCA_MY2020_Rx" SG_ 1074 DrLatchFrMsgTxt_D_Rq 1;
BA_ "GenSigSendType" SG_ 1074 DrLatchFrMsgTxt_D_Rq 3;
BA_ "U_CD542_MY2021_Rx" SG_ 1074 DrLatchFlMsgTxt_D_Rq_UB 1;
BA_ "U_T6_MCA_MY2020_Rx" SG_ 1074 DrLatchFlMsgTxt_D_Rq_UB 1;
BA_ "U_CD542_MY2021_Rx" SG_ 1074 DrLatchFlMsgTxt_D_Rq 1;
BA_ "U_T6_MCA_MY2020_Rx" SG_ 1074 DrLatchFlMsgTxt_D_Rq 1;
BA_ "GenSigSendType" SG_ 1074 DrLatchFlMsgTxt_D_Rq 3;
BA_ "U_CD542_MY2021_Rx" SG_ 1074 TrlrTireThresh_D_Stat_UB 1;
BA_ "U_T6_MCA_MY2020_Rx" SG_ 1074 TrlrTireThresh_D_Stat_UB 1;
BA_ "U_P702_MY2021_Rx" SG_ 1074 TrlrTireThresh_D_Stat_UB 1;
BA_ "U_CD542_MY2021_Rx" SG_ 1074 TrlrTireThresh_D_Stat 1;
BA_ "U_T6_MCA_MY2020_Rx" SG_ 1074 TrlrTireThresh_D_Stat 1;
BA_ "U_P702_MY2021_Rx" SG_ 1074 TrlrTireThresh_D_Stat 1;
BA_ "U_CD542_MY2021_Rx" SG_ 1074 TrlrTireSys_D_Stat_UB 1;
BA_ "U_T6_MCA_MY2020_Rx" SG_ 1074 TrlrTireSys_D_Stat_UB 1;
BA_ "U_P702_MY2021_Rx" SG_ 1074 TrlrTireSys_D_Stat_UB 1;
BA_ "U_CD542_MY2021_Rx" SG_ 1074 TrlrTireSys_D_Stat 1;
BA_ "U_T6_MCA_MY2020_Rx" SG_ 1074 TrlrTireSys_D_Stat 1;
BA_ "U_P702_MY2021_Rx" SG_ 1074 TrlrTireSys_D_Stat 1;
BA_ "GenSigSendType" SG_ 1074 TrlrTireSys_D_Stat 3;
BA_ "U_CD542_MY2021_Rx" SG_ 1074 TrlrTireCnt_D_Stat_UB 1;
BA_ "U_T6_MCA_MY2020_Rx" SG_ 1074 TrlrTireCnt_D_Stat_UB 1;
BA_ "U_P702_MY2021_Rx" SG_ 1074 TrlrTireCnt_D_Stat_UB 1;
BA_ "U_CD542_MY2021_Rx" SG_ 1074 TrlrTireCnt_D_Stat 1;
BA_ "U_T6_MCA_MY2020_Rx" SG_ 1074 TrlrTireCnt_D_Stat 1;
BA_ "U_P702_MY2021_Rx" SG_ 1074 TrlrTireCnt_D_Stat 1;
BA_ "GenSigSendType" SG_ 1074 TrlrTireCnt_D_Stat 3;
BA_ "U_CD542_MY2021_Rx" SG_ 1074 BrkMdeInhbt_B_RqDsply_UB 1;
BA_ "U_T6_MCA_MY2020_Rx" SG_ 1074 BrkMdeInhbt_B_RqDsply_UB 1;
BA_ "U_P702_MY2021_Rx" SG_ 1074 BrkMdeInhbt_B_RqDsply_UB 1;
BA_ "U_CD542_MY2021_Rx" SG_ 1074 BrkMdeInhbt_B_RqDsply 1;
BA_ "U_T6_MCA_MY2020_Rx" SG_ 1074 BrkMdeInhbt_B_RqDsply 1;
BA_ "U_P702_MY2021_Rx" SG_ 1074 BrkMdeInhbt_B_RqDsply 1;
BA_ "GenSigSendType" SG_ 1074 BrkMdeInhbt_B_RqDsply 3;
BA_ "WakeupSignal" SG_ 1074 BrkMdeInhbt_B_RqDsply 1;
BA_ "GenSigStartValue" SG_ 1014 WrlssAcsyChrg_Pc_Actl 126;
BA_ "U_T6_MCA_MY2020_Tx" SG_ 1014 WrlssAcsyChrgr_D_Stat 1;
BA_ "U_P702_MY2021_Tx" SG_ 1014 WrlssAcsyChrgr_D_Stat 1;
BA_ "U_CX727_MY2021_Tx" SG_ 1014 WrlssAcsyChrgr_D_Stat 1;
BA_ "U_CD542_MY2021_Rx" SG_ 1014 WrlssAcsyChrgr_D_Stat 1;
BA_ "U_T6_MCA_MY2020_Rx" SG_ 1014 WrlssAcsyChrgr_D_Stat 1;
BA_ "U_P702_MY2021_Rx" SG_ 1014 WrlssAcsyChrgr_D_Stat 1;
BA_ "GenSigSendType" SG_ 1014 WrlssAcsyChrgr_D_Stat 3;
BA_ "GenSigStartValue" SG_ 1014 WrlssAcsyChrgr_D_Stat 1;
BA_ "GenSigStartValueInteger" SG_ 1014 WrlssAcsyChrgr_D_Stat 1;
BA_ "U_CD542_MY2021_Tx" SG_ 548 DSP_AHU_ChmTstTone_Rq 1;
BA_ "U_T6_MCA_MY2020_Tx" SG_ 548 DSP_AHU_ChmTstTone_Rq 1;
BA_ "U_P702_MY2021_Tx" SG_ 548 DSP_AHU_ChmTstTone_Rq 1;
BA_ "U_CD542_MY2021_Rx" SG_ 548 DSP_AHU_ChmTstTone_Rq 1;
BA_ "U_T6_MCA_MY2020_Rx" SG_ 548 DSP_AHU_ChmTstTone_Rq 1;
BA_ "U_P702_MY2021_Rx" SG_ 548 DSP_AHU_ChmTstTone_Rq 1;
BA_ "GenSigSendType" SG_ 548 DSP_AHU_ChmTstTone_Rq 3;
BA_ "U_CD542_MY2021_Tx" SG_ 548 DSP_ChimeChanState_St 1;
BA_ "U_T6_MCA_MY2020_Tx" SG_ 548 DSP_ChimeChanState_St 1;
BA_ "U_P702_MY2021_Tx" SG_ 548 DSP_ChimeChanState_St 1;
BA_ "U_CD542_MY2021_Rx" SG_ 548 DSP_ChimeChanState_St 1;
BA_ "U_T6_MCA_MY2020_Rx" SG_ 548 DSP_ChimeChanState_St 1;
BA_ "U_P702_MY2021_Rx" SG_ 548 DSP_ChimeChanState_St 1;
BA_ "GenSigSendType" SG_ 548 DSP_ChimeChanState_St 3;
BA_ "U_CD542_MY2021_Tx" SG_ 548 DSP_Chime2_Not_Recgnizd 1;
BA_ "U_T6_MCA_MY2020_Tx" SG_ 548 DSP_Chime2_Not_Recgnizd 1;
BA_ "U_P702_MY2021_Tx" SG_ 548 DSP_Chime2_Not_Recgnizd 1;
BA_ "U_CD542_MY2021_Rx" SG_ 548 DSP_Chime2_Not_Recgnizd 1;
BA_ "U_T6_MCA_MY2020_Rx" SG_ 548 DSP_Chime2_Not_Recgnizd 1;
BA_ "GenSigSendType" SG_ 548 DSP_Chime2_Not_Recgnizd 3;
BA_ "U_CD542_MY2021_Tx" SG_ 548 DSP_Chime_Not_Recgnizd 1;
BA_ "U_T6_MCA_MY2020_Tx" SG_ 548 DSP_Chime_Not_Recgnizd 1;
BA_ "U_P702_MY2021_Tx" SG_ 548 DSP_Chime_Not_Recgnizd 1;
BA_ "U_CD542_MY2021_Rx" SG_ 548 DSP_Chime_Not_Recgnizd 1;
BA_ "U_T6_MCA_MY2020_Rx" SG_ 548 DSP_Chime_Not_Recgnizd 1;
BA_ "GenSigSendType" SG_ 548 DSP_Chime_Not_Recgnizd 3;
BA_ "U_CD542_MY2021_Tx" SG_ 548 DSP_Alert_Channel3 1;
BA_ "U_T6_MCA_MY2020_Tx" SG_ 548 DSP_Alert_Channel3 1;
BA_ "U_P702_MY2021_Tx" SG_ 548 DSP_Alert_Channel3 1;
BA_ "U_CD542_MY2021_Rx" SG_ 548 DSP_Alert_Channel3 1;
BA_ "U_T6_MCA_MY2020_Rx" SG_ 548 DSP_Alert_Channel3 1;
BA_ "GenSigSendType" SG_ 548 DSP_Alert_Channel3 3;
BA_ "U_CD542_MY2021_Tx" SG_ 548 DSP_Alert_Channel2 1;
BA_ "U_T6_MCA_MY2020_Tx" SG_ 548 DSP_Alert_Channel2 1;
BA_ "U_P702_MY2021_Tx" SG_ 548 DSP_Alert_Channel2 1;
BA_ "U_P702_MY2021_Rx" SG_ 548 DSP_Alert_Channel2 1;
BA_ "U_CD542_MY2021_Rx" SG_ 548 DSP_Alert_Channel2 1;
BA_ "U_T6_MCA_MY2020_Rx" SG_ 548 DSP_Alert_Channel2 1;
BA_ "GenSigSendType" SG_ 548 DSP_Alert_Channel2 3;
BA_ "U_CD542_MY2021_Tx" SG_ 548 DSP_Alert_Channel1 1;
BA_ "U_T6_MCA_MY2020_Tx" SG_ 548 DSP_Alert_Channel1 1;
BA_ "U_P702_MY2021_Tx" SG_ 548 DSP_Alert_Channel1 1;
BA_ "U_CD542_MY2021_Rx" SG_ 548 DSP_Alert_Channel1 1;
BA_ "U_T6_MCA_MY2020_Rx" SG_ 548 DSP_Alert_Channel1 1;
BA_ "U_P702_MY2021_Rx" SG_ 548 DSP_Alert_Channel1 1;
BA_ "GenSigSendType" SG_ 548 DSP_Alert_Channel1 3;
BA_ "U_T6_MCA_MY2020_Tx" SG_ 548 DSP_Chimes_Supported 1;
BA_ "U_P702_MY2021_Tx" SG_ 548 DSP_Chimes_Supported 1;
BA_ "U_P702_MY2021_Rx" SG_ 548 DSP_Chimes_Supported 1;
BA_ "U_CD542_MY2021_Rx" SG_ 548 DSP_Chimes_Supported 1;
BA_ "U_T6_MCA_MY2020_Rx" SG_ 548 DSP_Chimes_Supported 1;
BA_ "GenSigSendType" SG_ 548 DSP_Chimes_Supported 3;
BA_ "U_CD542_MY2021_Tx" SG_ 548 DSP_AdjChimVolSupp_St 1;
BA_ "U_T6_MCA_MY2020_Tx" SG_ 548 DSP_AdjChimVolSupp_St 1;
BA_ "U_P702_MY2021_Tx" SG_ 548 DSP_AdjChimVolSupp_St 1;
BA_ "U_T6_MCA_MY2020_Rx" SG_ 548 DSP_AdjChimVolSupp_St 1;
BA_ "GenSigSendType" SG_ 548 DSP_AdjChimVolSupp_St 3;
BA_ "U_CD542_MY2021_Tx" SG_ 548 DSP_AdjChimVolSupp2_St 1;
BA_ "U_T6_MCA_MY2020_Tx" SG_ 548 DSP_AdjChimVolSupp2_St 1;
BA_ "U_P702_MY2021_Tx" SG_ 548 DSP_AdjChimVolSupp2_St 1;
BA_ "U_T6_MCA_MY2020_Rx" SG_ 548 DSP_AdjChimVolSupp2_St 1;
BA_ "GenSigSendType" SG_ 548 DSP_AdjChimVolSupp2_St 3;
BA_ "U_T6_MCA_MY2020_Tx" SG_ 548 DSP_AHU_ChmTstT 1;
BA_ "U_T6_MCA_MY2020_Rx" SG_ 548 DSP_AHU_ChmTstT 1;
BA_ "U_P702_MY2021_Rx" SG_ 548 DSP_AHU_ChmTstT 1;
BA_ "GenSigSendType" SG_ 548 DSP_AHU_ChmTstT 3;
BA_ "U_T6_MCA_MY2020_Tx" SG_ 548 DspDgtlChime_D_Stat 1;
BA_ "U_T6_MCA_MY2020_Rx" SG_ 548 DspDgtlChime_D_Stat 1;
BA_ "U_P702_MY2021_Rx" SG_ 548 DspDgtlChime_D_Stat 1;
BA_ "GenSigSendType" SG_ 548 DspDgtlChime_D_Stat 3;
BA_ "U_CD542_MY2021_Tx" SG_ 404 Dsp_LangUpdate_Rsp 1;
BA_ "U_T6_MCA_MY2020_Tx" SG_ 404 Dsp_LangUpdate_Rsp 1;
BA_ "U_P702_MY2021_Tx" SG_ 404 Dsp_LangUpdate_Rsp 1;
BA_ "U_CD542_MY2021_Rx" SG_ 404 Dsp_LangUpdate_Rsp 1;
BA_ "U_T6_MCA_MY2020_Rx" SG_ 404 Dsp_LangUpdate_Rsp 1;
BA_ "GenSigSendType" SG_ 404 Dsp_LangUpdate_Rsp 3;
BA_ "U_CD542_MY2021_Tx" SG_ 689 AUDIO_MC_WORD_Tx 1;
BA_ "U_T6_MCA_MY2020_Tx" SG_ 689 AUDIO_MC_WORD_Tx 1;
BA_ "U_P702_MY2021_Tx" SG_ 689 AUDIO_MC_WORD_Tx 1;
BA_ "U_CD542_MY2021_Rx" SG_ 689 AUDIO_MC_WORD_Tx 1;
BA_ "U_T6_MCA_MY2020_Rx" SG_ 689 AUDIO_MC_WORD_Tx 1;
BA_ "U_CD542_MY2021_Tx" SG_ 1008 SelectedNumOfPresets 1;
BA_ "U_T6_MCA_MY2020_Tx" SG_ 1008 SelectedNumOfPresets 1;
BA_ "U_P702_MY2021_Tx" SG_ 1008 SelectedNumOfPresets 1;
BA_ "U_CD542_MY2021_Rx" SG_ 1008 SelectedNumOfPresets 1;
BA_ "U_T6_MCA_MY2020_Rx" SG_ 1008 SelectedNumOfPresets 1;
BA_ "U_P702_MY2021_Rx" SG_ 1008 SelectedNumOfPresets 1;
BA_ "GenSigSendType" SG_ 1008 SelectedNumOfPresets 3;
BA_ "U_CD542_MY2021_Tx" SG_ 1008 MultimediaSrc_D_Stat 1;
BA_ "U_T6_MCA_MY2020_Tx" SG_ 1008 MultimediaSrc_D_Stat 1;
BA_ "U_P702_MY2021_Tx" SG_ 1008 MultimediaSrc_D_Stat 1;
BA_ "GenSigSendType" SG_ 1008 MultimediaSrc_D_Stat 3;
BA_ "U_CD542_MY2021_Tx" SG_ 1008 MultimediaShuf_D_Stat 1;
BA_ "U_T6_MCA_MY2020_Tx" SG_ 1008 MultimediaShuf_D_Stat 1;
BA_ "U_P702_MY2021_Tx" SG_ 1008 MultimediaShuf_D_Stat 1;
BA_ "GenSigSendType" SG_ 1008 MultimediaShuf_D_Stat 3;
BA_ "U_CD542_MY2021_Tx" SG_ 1008 MultimediaRepeat_D_Stat 1;
BA_ "U_T6_MCA_MY2020_Tx" SG_ 1008 MultimediaRepeat_D_Stat 1;
BA_ "U_P702_MY2021_Tx" SG_ 1008 MultimediaRepeat_D_Stat 1;
BA_ "GenSigSendType" SG_ 1008 MultimediaRepeat_D_Stat 3;
BA_ "U_CD542_MY2021_Tx" SG_ 1008 CPM_MediaPlayerSrc_St 1;
BA_ "U_T6_MCA_MY2020_Tx" SG_ 1008 CPM_MediaPlayerSrc_St 1;
BA_ "U_P702_MY2021_Tx" SG_ 1008 CPM_MediaPlayerSrc_St 1;
BA_ "GenSigSendType" SG_ 1008 CPM_MediaPlayerSrc_St 3;
BA_ "U_CD542_MY2021_Tx" SG_ 1008 APIM_TrackPlaytime_St 1;
BA_ "U_T6_MCA_MY2020_Tx" SG_ 1008 APIM_TrackPlaytime_St 1;
BA_ "U_P702_MY2021_Tx" SG_ 1008 APIM_TrackPlaytime_St 1;
BA_ "U_CD542_MY2021_Rx" SG_ 1008 APIM_TrackPlaytime_St 1;
BA_ "U_T6_MCA_MY2020_Rx" SG_ 1008 APIM_TrackPlaytime_St 1;
BA_ "U_CD542_MY2021_Tx" SG_ 1008 APIM_TotalPlayTime_St 1;
BA_ "U_T6_MCA_MY2020_Tx" SG_ 1008 APIM_TotalPlayTime_St 1;
BA_ "U_P702_MY2021_Tx" SG_ 1008 APIM_TotalPlayTime_St 1;
BA_ "U_CD542_MY2021_Rx" SG_ 1008 APIM_TotalPlayTime_St 1;
BA_ "U_T6_MCA_MY2020_Rx" SG_ 1008 APIM_TotalPlayTime_St 1;
BA_ "U_T6_MCA_MY2020_Tx" SG_ 547 Audio_Amp_St 1;
BA_ "U_P702_MY2021_Tx" SG_ 547 Audio_Amp_St 1;
BA_ "GenSigSendType" SG_ 547 Audio_Amp_St 3;
BA_ "U_CD542_MY2021_Tx" SG_ 547 Chime_Alert_Chan2 1;
BA_ "U_T6_MCA_MY2020_Tx" SG_ 547 Chime_Alert_Chan2 1;
BA_ "U_P702_MY2021_Tx" SG_ 547 Chime_Alert_Chan2 1;
BA_ "U_P702_MY2021_Rx" SG_ 547 Chime_Alert_Chan2 1;
BA_ "U_CD542_MY2021_Rx" SG_ 547 Chime_Alert_Chan2 1;
BA_ "U_T6_MCA_MY2020_Rx" SG_ 547 Chime_Alert_Chan2 1;
BA_ "GenSigSendType" SG_ 547 Chime_Alert_Chan2 3;
BA_ "U_CD542_MY2021_Tx" SG_ 547 AHU_Chime2_Active 1;
BA_ "U_T6_MCA_MY2020_Tx" SG_ 547 AHU_Chime2_Active 1;
BA_ "U_P702_MY2021_Tx" SG_ 547 AHU_Chime2_Active 1;
BA_ "U_CD542_MY2021_Rx" SG_ 547 AHU_Chime2_Active 1;
BA_ "U_T6_MCA_MY2020_Rx" SG_ 547 AHU_Chime2_Active 1;
BA_ "U_P702_MY2021_Rx" SG_ 547 AHU_Chime2_Active 1;
BA_ "GenSigSendType" SG_ 547 AHU_Chime2_Active 3;
BA_ "U_T6_MCA_MY2020_Tx" SG_ 547 AHU_Chime2_Not_Recognized 1;
BA_ "U_P702_MY2021_Tx" SG_ 547 AHU_Chime2_Not_Recognized 1;
BA_ "U_CD542_MY2021_Rx" SG_ 547 AHU_Chime2_Not_Recognized 1;
BA_ "U_T6_MCA_MY2020_Rx" SG_ 547 AHU_Chime2_Not_Recognized 1;
BA_ "U_P702_MY2021_Rx" SG_ 547 AHU_Chime2_Not_Recognized 1;
BA_ "GenSigSendType" SG_ 547 AHU_Chime2_Not_Recognized 3;
BA_ "U_CD542_MY2021_Tx" SG_ 547 Chime_Alert_Chan 1;
BA_ "U_T6_MCA_MY2020_Tx" SG_ 547 Chime_Alert_Chan 1;
BA_ "U_P702_MY2021_Tx" SG_ 547 Chime_Alert_Chan 1;
BA_ "U_P702_MY2021_Rx" SG_ 547 Chime_Alert_Chan 1;
BA_ "U_CD542_MY2021_Rx" SG_ 547 Chime_Alert_Chan 1;
BA_ "U_T6_MCA_MY2020_Rx" SG_ 547 Chime_Alert_Chan 1;
BA_ "GenSigSendType" SG_ 547 Chime_Alert_Chan 3;
BA_ "U_CD542_MY2021_Tx" SG_ 547 AHU_Alert_Channel1 1;
BA_ "U_T6_MCA_MY2020_Tx" SG_ 547 AHU_Alert_Channel1 1;
BA_ "U_P702_MY2021_Tx" SG_ 547 AHU_Alert_Channel1 1;
BA_ "U_CD542_MY2021_Rx" SG_ 547 AHU_Alert_Channel1 1;
BA_ "U_T6_MCA_MY2020_Rx" SG_ 547 AHU_Alert_Channel1 1;
BA_ "U_P702_MY2021_Rx" SG_ 547 AHU_Alert_Channel1 1;
BA_ "GenSigSendType" SG_ 547 AHU_Alert_Channel1 3;
BA_ "U_CD542_MY2021_Tx" SG_ 547 AHU_Chime_Supported 1;
BA_ "U_T6_MCA_MY2020_Tx" SG_ 547 AHU_Chime_Supported 1;
BA_ "U_P702_MY2021_Tx" SG_ 547 AHU_Chime_Supported 1;
BA_ "U_CD542_MY2021_Rx" SG_ 547 AHU_Chime_Supported 1;
BA_ "U_T6_MCA_MY2020_Rx" SG_ 547 AHU_Chime_Supported 1;
BA_ "U_P702_MY2021_Rx" SG_ 547 AHU_Chime_Supported 1;
BA_ "GenSigSendType" SG_ 547 AHU_Chime_Supported 3;
BA_ "U_CD542_MY2021_Tx" SG_ 547 AHU_Chime_Active 1;
BA_ "U_T6_MCA_MY2020_Tx" SG_ 547 AHU_Chime_Active 1;
BA_ "U_P702_MY2021_Tx" SG_ 547 AHU_Chime_Active 1;
BA_ "U_CD542_MY2021_Rx" SG_ 547 AHU_Chime_Active 1;
BA_ "U_T6_MCA_MY2020_Rx" SG_ 547 AHU_Chime_Active 1;
BA_ "U_P702_MY2021_Rx" SG_ 547 AHU_Chime_Active 1;
BA_ "GenSigSendType" SG_ 547 AHU_Chime_Active 3;
BA_ "U_T6_MCA_MY2020_Tx" SG_ 547 AHU_Chime_Not_Recognized 1;
BA_ "U_P702_MY2021_Tx" SG_ 547 AHU_Chime_Not_Recognized 1;
BA_ "U_CD542_MY2021_Rx" SG_ 547 AHU_Chime_Not_Recognized 1;
BA_ "U_T6_MCA_MY2020_Rx" SG_ 547 AHU_Chime_Not_Recognized 1;
BA_ "U_P702_MY2021_Rx" SG_ 547 AHU_Chime_Not_Recognized 1;
BA_ "GenSigSendType" SG_ 547 AHU_Chime_Not_Recognized 3;
BA_ "U_T6_MCA_MY2020_Tx" SG_ 547 ChimeId_No_Stat 1;
BA_ "U_P702_MY2021_Tx" SG_ 547 ChimeId_No_Stat 1;
BA_ "U_CD542_MY2021_Rx" SG_ 547 ChimeId_No_Stat 1;
BA_ "U_T6_MCA_MY2020_Rx" SG_ 547 ChimeId_No_Stat 1;
BA_ "GenSigSendType" SG_ 547 ChimeId_No_Stat 3;
BA_ "U_T6_MCA_MY2020_Tx" SG_ 547 Chime2Id_No_Stat 1;
BA_ "U_P702_MY2021_Tx" SG_ 547 Chime2Id_No_Stat 1;
BA_ "U_CD542_MY2021_Rx" SG_ 547 Chime2Id_No_Stat 1;
BA_ "U_T6_MCA_MY2020_Rx" SG_ 547 Chime2Id_No_Stat 1;
BA_ "GenSigSendType" SG_ 547 Chime2Id_No_Stat 3;
BA_ "U_T6_MCA_MY2020_Tx" SG_ 547 AHU_AdjChimVolSupp2_St 1;
BA_ "U_P702_MY2021_Tx" SG_ 547 AHU_AdjChimVolSupp2_St 1;
BA_ "U_CD542_MY2021_Rx" SG_ 547 AHU_AdjChimVolSupp2_St 1;
BA_ "U_T6_MCA_MY2020_Rx" SG_ 547 AHU_AdjChimVolSupp2_St 1;
BA_ "GenSigSendType" SG_ 547 AHU_AdjChimVolSupp2_St 3;
BA_ "U_T6_MCA_MY2020_Tx" SG_ 547 AHU_AdjChimeVolSupp_St 1;
BA_ "U_P702_MY2021_Tx" SG_ 547 AHU_AdjChimeVolSupp_St 1;
BA_ "U_CD542_MY2021_Rx" SG_ 547 AHU_AdjChimeVolSupp_St 1;
BA_ "U_T6_MCA_MY2020_Rx" SG_ 547 AHU_AdjChimeVolSupp_St 1;
BA_ "GenSigSendType" SG_ 547 AHU_AdjChimeVolSupp_St 3;
BA_ "U_T6_MCA_MY2020_Tx" SG_ 547 AhuDgtlChime_D_Stat 1;
BA_ "U_P702_MY2021_Tx" SG_ 547 AhuDgtlChime_D_Stat 1;
BA_ "U_T6_MCA_MY2020_Rx" SG_ 547 AhuDgtlChime_D_Stat 1;
BA_ "GenSigSendType" SG_ 547 AhuDgtlChime_D_Stat 3;
BA_ "U_CD542_MY2021_Tx" SG_ 732 ACU_CurrItemsInFMSL_St 1;
BA_ "U_T6_MCA_MY2020_Tx" SG_ 732 ACU_CurrItemsInFMSL_St 1;
BA_ "U_P702_MY2021_Tx" SG_ 732 ACU_CurrItemsInFMSL_St 1;
BA_ "U_CD542_MY2021_Rx" SG_ 732 ACU_CurrItemsInFMSL_St 1;
BA_ "U_T6_MCA_MY2020_Rx" SG_ 732 ACU_CurrItemsInFMSL_St 1;
BA_ "U_CD542_MY2021_Tx" SG_ 732 ACU_FunctionStatus_St 1;
BA_ "U_T6_MCA_MY2020_Tx" SG_ 732 ACU_FunctionStatus_St 1;
BA_ "U_P702_MY2021_Tx" SG_ 732 ACU_FunctionStatus_St 1;
BA_ "U_CD542_MY2021_Rx" SG_ 732 ACU_FunctionStatus_St 1;
BA_ "U_T6_MCA_MY2020_Rx" SG_ 732 ACU_FunctionStatus_St 1;
BA_ "GenSigSendType" SG_ 732 ACU_FunctionStatus_St 3;
BA_ "U_CD542_MY2021_Tx" SG_ 732 ACU_CurrFMSLPreset_St 1;
BA_ "U_T6_MCA_MY2020_Tx" SG_ 732 ACU_CurrFMSLPreset_St 1;
BA_ "U_P702_MY2021_Tx" SG_ 732 ACU_CurrFMSLPreset_St 1;
BA_ "U_CD542_MY2021_Rx" SG_ 732 ACU_CurrFMSLPreset_St 1;
BA_ "U_T6_MCA_MY2020_Rx" SG_ 732 ACU_CurrFMSLPreset_St 1;
BA_ "U_P702_MY2021_Rx" SG_ 732 ACU_CurrFMSLPreset_St 1;
BA_ "U_CD542_MY2021_Tx" SG_ 732 ACU_CurrPreset2_St 1;
BA_ "U_T6_MCA_MY2020_Tx" SG_ 732 ACU_CurrPreset2_St 1;
BA_ "U_P702_MY2021_Tx" SG_ 732 ACU_CurrPreset2_St 1;
BA_ "U_P702_MY2021_Rx" SG_ 732 ACU_CurrPreset2_St 1;
BA_ "U_CD542_MY2021_Rx" SG_ 732 ACU_CurrPreset2_St 1;
BA_ "U_T6_MCA_MY2020_Rx" SG_ 732 ACU_CurrPreset2_St 1;
BA_ "U_CD542_MY2021_Tx" SG_ 732 ACU_StorePreset_St 1;
BA_ "U_T6_MCA_MY2020_Tx" SG_ 732 ACU_StorePreset_St 1;
BA_ "U_P702_MY2021_Tx" SG_ 732 ACU_StorePreset_St 1;
BA_ "U_P702_MY2021_Rx" SG_ 732 ACU_StorePreset_St 1;
BA_ "U_CD542_MY2021_Rx" SG_ 732 ACU_StorePreset_St 1;
BA_ "U_T6_MCA_MY2020_Rx" SG_ 732 ACU_StorePreset_St 1;
BA_ "GenSigSendType" SG_ 732 ACU_StorePreset_St 3;
BA_ "U_T6_MCA_MY2020_Tx" SG_ 732 ACU_VoiceCommand_St 1;
BA_ "U_P702_MY2021_Tx" SG_ 732 ACU_VoiceCommand_St 1;
BA_ "GenSigSendType" SG_ 732 ACU_VoiceCommand_St 3;
BA_ "U_CD542_MY2021_Tx" SG_ 732 ACU_CurrMixPreset_St 1;
BA_ "U_T6_MCA_MY2020_Tx" SG_ 732 ACU_CurrMixPreset_St 1;
BA_ "U_P702_MY2021_Tx" SG_ 732 ACU_CurrMixPreset_St 1;
BA_ "U_CD542_MY2021_Rx" SG_ 732 ACU_CurrMixPreset_St 1;
BA_ "U_T6_MCA_MY2020_Rx" SG_ 732 ACU_CurrMixPreset_St 1;
BA_ "U_P702_MY2021_Rx" SG_ 732 ACU_CurrMixPreset_St 1;
BA_ "U_T6_MCA_MY2020_Tx" SG_ 728 PrplSnd_D_Stat 1;
BA_ "U_CD542_MY2021_Rx" SG_ 728 PrplSnd_D_Stat 1;
BA_ "U_T6_MCA_MY2020_Rx" SG_ 728 PrplSnd_D_Stat 1;
BA_ "GenSigSendType" SG_ 728 PrplSnd_D_Stat 3;
BA_ "U_T6_MCA_MY2020_Tx" SG_ 728 ACU_AuxVolume_Up 1;
BA_ "U_P702_MY2021_Tx" SG_ 728 ACU_AuxVolume_Up 1;
BA_ "U_T6_MCA_MY2020_Rx" SG_ 728 ACU_AuxVolume_Up 1;
BA_ "GenSigSendType" SG_ 728 ACU_AuxVolume_Up 3;
BA_ "U_T6_MCA_MY2020_Tx" SG_ 728 ACU_AuxVolume_St 1;
BA_ "U_P702_MY2021_Tx" SG_ 728 ACU_AuxVolume_St 1;
BA_ "U_T6_MCA_MY2020_Rx" SG_ 728 ACU_AuxVolume_St 1;
BA_ "U_CD542_MY2021_Tx" SG_ 728 ACU_Mid_St 1;
BA_ "U_T6_MCA_MY2020_Tx" SG_ 728 ACU_Mid_St 1;
BA_ "U_P702_MY2021_Tx" SG_ 728 ACU_Mid_St 1;
BA_ "U_CD542_MY2021_Rx" SG_ 728 ACU_Mid_St 1;
BA_ "U_T6_MCA_MY2020_Rx" SG_ 728 ACU_Mid_St 1;
BA_ "U_P702_MY2021_Rx" SG_ 728 ACU_Mid_St 1;
BA_ "U_T6_MCA_MY2020_Tx" SG_ 728 ACU_RadioSeekMode_St 1;
BA_ "U_P702_MY2021_Tx" SG_ 728 ACU_RadioSeekMode_St 1;
BA_ "U_CD542_MY2021_Rx" SG_ 728 ACU_RadioSeekMode_St 1;
BA_ "U_P702_MY2021_Rx" SG_ 728 ACU_RadioSeekMode_St 1;
BA_ "U_T6_MCA_MY2020_Rx" SG_ 728 ACU_RadioSeekMode_St 1;
BA_ "GenSigSendType" SG_ 728 ACU_RadioSeekMode_St 3;
BA_ "U_CD542_MY2021_Tx" SG_ 728 ACU_Volume_St 1;
BA_ "U_T6_MCA_MY2020_Tx" SG_ 728 ACU_Volume_St 1;
BA_ "U_P702_MY2021_Tx" SG_ 728 ACU_Volume_St 1;
BA_ "U_U55X_MY2022_Rx" SG_ 728 ACU_Volume_St 1;
BA_ "ECGUsedRxSignal" SG_ 728 ACU_Volume_St 1;
BA_ "U_P702_MY2021_Rx" SG_ 728 ACU_Volume_St 1;
BA_ "U_CD542_MY2021_Rx" SG_ 728 ACU_Volume_St 1;
BA_ "U_T6_MCA_MY2020_Rx" SG_ 728 ACU_Volume_St 1;
BA_ "U_CD542_MY2021_Tx" SG_ 728 ACU_Volume_Up 1;
BA_ "U_T6_MCA_MY2020_Tx" SG_ 728 ACU_Volume_Up 1;
BA_ "U_P702_MY2021_Tx" SG_ 728 ACU_Volume_Up 1;
BA_ "U_P702_MY2021_Rx" SG_ 728 ACU_Volume_Up 1;
BA_ "U_CD542_MY2021_Rx" SG_ 728 ACU_Volume_Up 1;
BA_ "U_T6_MCA_MY2020_Rx" SG_ 728 ACU_Volume_Up 1;
BA_ "GenSigSendType" SG_ 728 ACU_Volume_Up 3;
BA_ "U_CD542_MY2021_Tx" SG_ 728 ACU_CurrentStatFlags_St 1;
BA_ "U_T6_MCA_MY2020_Tx" SG_ 728 ACU_CurrentStatFlags_St 1;
BA_ "U_P702_MY2021_Tx" SG_ 728 ACU_CurrentStatFlags_St 1;
BA_ "U_P702_MY2021_Rx" SG_ 728 ACU_CurrentStatFlags_St 1;
BA_ "U_CD542_MY2021_Rx" SG_ 728 ACU_CurrentStatFlags_St 1;
BA_ "U_T6_MCA_MY2020_Rx" SG_ 728 ACU_CurrentStatFlags_St 1;
BA_ "U_CD542_MY2021_Tx" SG_ 489 ACU_CurrentPSName_St 1;
BA_ "U_T6_MCA_MY2020_Tx" SG_ 489 ACU_CurrentPSName_St 1;
BA_ "U_P702_MY2021_Tx" SG_ 489 ACU_CurrentPSName_St 1;
BA_ "U_P702_MY2021_Rx" SG_ 489 ACU_CurrentPSName_St 1;
BA_ "U_CD542_MY2021_Rx" SG_ 489 ACU_CurrentPSName_St 1;
BA_ "U_T6_MCA_MY2020_Rx" SG_ 489 ACU_CurrentPSName_St 1;
BA_ "GenSigSendType" SG_ 489 ACU_CurrentPSName_St 3;
BA_ "GenSigSendType" SG_ 757 SdarsAudioRtng_D_Stat 3;
BA_ "U_CD542_MY2021_Tx" SG_ 757 SpkrStdRight_D_Stat 1;
BA_ "U_T6_MCA_MY2020_Tx" SG_ 757 SpkrStdRight_D_Stat 1;
BA_ "U_P702_MY2021_Tx" SG_ 757 SpkrStdRight_D_Stat 1;
BA_ "U_T6_MCA_MY2020_Rx" SG_ 757 SpkrStdRight_D_Stat 1;
BA_ "GenSigSendType" SG_ 757 SpkrStdRight_D_Stat 3;
BA_ "U_CD542_MY2021_Tx" SG_ 757 SpkrStdLeft_D_Stat 1;
BA_ "U_T6_MCA_MY2020_Tx" SG_ 757 SpkrStdLeft_D_Stat 1;
BA_ "U_P702_MY2021_Tx" SG_ 757 SpkrStdLeft_D_Stat 1;
BA_ "U_T6_MCA_MY2020_Rx" SG_ 757 SpkrStdLeft_D_Stat 1;
BA_ "GenSigSendType" SG_ 757 SpkrStdLeft_D_Stat 3;
BA_ "U_CD542_MY2021_Tx" SG_ 757 SpkrStdCntr_D_Stat 1;
BA_ "U_T6_MCA_MY2020_Tx" SG_ 757 SpkrStdCntr_D_Stat 1;
BA_ "U_P702_MY2021_Tx" SG_ 757 SpkrStdCntr_D_Stat 1;
BA_ "U_T6_MCA_MY2020_Rx" SG_ 757 SpkrStdCntr_D_Stat 1;
BA_ "GenSigSendType" SG_ 757 SpkrStdCntr_D_Stat 3;
BA_ "U_CD542_MY2021_Tx" SG_ 757 SDARS_ChipControl_St 1;
BA_ "U_T6_MCA_MY2020_Tx" SG_ 757 SDARS_ChipControl_St 1;
BA_ "U_P702_MY2021_Tx" SG_ 757 SDARS_ChipControl_St 1;
BA_ "U_CD542_MY2021_Rx" SG_ 757 SDARS_ChipControl_St 1;
BA_ "U_T6_MCA_MY2020_Rx" SG_ 757 SDARS_ChipControl_St 1;
BA_ "U_P702_MY2021_Rx" SG_ 757 SDARS_ChipControl_St 1;
BA_ "GenSigSendType" SG_ 757 SDARS_ChipControl_St 3;
BA_ "U_CD542_MY2021_Tx" SG_ 757 ACU_AutoStoreResult_St 1;
BA_ "U_T6_MCA_MY2020_Tx" SG_ 757 ACU_AutoStoreResult_St 1;
BA_ "U_P702_MY2021_Tx" SG_ 757 ACU_AutoStoreResult_St 1;
BA_ "U_P702_MY2021_Rx" SG_ 757 ACU_AutoStoreResult_St 1;
BA_ "U_CD542_MY2021_Rx" SG_ 757 ACU_AutoStoreResult_St 1;
BA_ "U_T6_MCA_MY2020_Rx" SG_ 757 ACU_AutoStoreResult_St 1;
BA_ "GenSigSendType" SG_ 757 ACU_AutoStoreResult_St 3;
BA_ "U_CD542_MY2021_Tx" SG_ 757 ACU_DirectTune_St 1;
BA_ "U_T6_MCA_MY2020_Tx" SG_ 757 ACU_DirectTune_St 1;
BA_ "U_P702_MY2021_Tx" SG_ 757 ACU_DirectTune_St 1;
BA_ "U_P702_MY2021_Rx" SG_ 757 ACU_DirectTune_St 1;
BA_ "U_CD542_MY2021_Rx" SG_ 757 ACU_DirectTune_St 1;
BA_ "U_T6_MCA_MY2020_Rx" SG_ 757 ACU_DirectTune_St 1;
BA_ "GenSigSendType" SG_ 757 ACU_DirectTune_St 3;
BA_ "U_CD542_MY2021_Tx" SG_ 757 ACU_RadioSeekMode2_St 1;
BA_ "U_T6_MCA_MY2020_Tx" SG_ 757 ACU_RadioSeekMode2_St 1;
BA_ "U_P702_MY2021_Tx" SG_ 757 ACU_RadioSeekMode2_St 1;
BA_ "U_P702_MY2021_Rx" SG_ 757 ACU_RadioSeekMode2_St 1;
BA_ "U_CX727_MY2021_Rx" SG_ 757 ACU_RadioSeekMode2_St 1;
BA_ "U_CD542_MY2021_Rx" SG_ 757 ACU_RadioSeekMode2_St 1;
BA_ "U_T6_MCA_MY2020_Rx" SG_ 757 ACU_RadioSeekMode2_St 1;
BA_ "GenSigSendType" SG_ 757 ACU_RadioSeekMode2_St 3;
BA_ "U_CD542_MY2021_Tx" SG_ 757 ACU_CurrTUBand_St 1;
BA_ "U_P702_MY2021_Tx" SG_ 757 ACU_CurrTUBand_St 1;
BA_ "U_P702_MY2021_Rx" SG_ 757 ACU_CurrTUBand_St 1;
BA_ "U_CX727_MY2021_Rx" SG_ 757 ACU_CurrTUBand_St 1;
BA_ "U_CD542_MY2021_Rx" SG_ 757 ACU_CurrTUBand_St 1;
BA_ "U_T6_MCA_MY2020_Rx" SG_ 757 ACU_CurrTUBand_St 1;
BA_ "GenSigSendType" SG_ 757 ACU_CurrTUBand_St 3;
BA_ "U_CD542_MY2021_Tx" SG_ 734 ACU_ActServiceLink_St 1;
BA_ "U_T6_MCA_MY2020_Tx" SG_ 734 ACU_ActServiceLink_St 1;
BA_ "U_P702_MY2021_Tx" SG_ 734 ACU_ActServiceLink_St 1;
BA_ "U_CD542_MY2021_Rx" SG_ 734 ACU_ActServiceLink_St 1;
BA_ "U_T6_MCA_MY2020_Rx" SG_ 734 ACU_ActServiceLink_St 1;
BA_ "U_P702_MY2021_Rx" SG_ 734 ACU_ActServiceLink_St 1;
BA_ "GenSigSendType" SG_ 734 ACU_ActServiceLink_St 3;
BA_ "U_CD542_MY2021_Tx" SG_ 734 ACU_CurrTUDRService2_St 1;
BA_ "U_T6_MCA_MY2020_Tx" SG_ 734 ACU_CurrTUDRService2_St 1;
BA_ "U_P702_MY2021_Tx" SG_ 734 ACU_CurrTUDRService2_St 1;
BA_ "U_P702_MY2021_Rx" SG_ 734 ACU_CurrTUDRService2_St 1;
BA_ "U_CD542_MY2021_Rx" SG_ 734 ACU_CurrTUDRService2_St 1;
BA_ "U_T6_MCA_MY2020_Rx" SG_ 734 ACU_CurrTUDRService2_St 1;
BA_ "GenSigSendType" SG_ 734 ACU_CurrTUDRService2_St 3;
BA_ "U_CD542_MY2021_Tx" SG_ 734 ACU_ComTUSIDValid_St 1;
BA_ "U_T6_MCA_MY2020_Tx" SG_ 734 ACU_ComTUSIDValid_St 1;
BA_ "U_P702_MY2021_Tx" SG_ 734 ACU_ComTUSIDValid_St 1;
BA_ "U_CD542_MY2021_Rx" SG_ 734 ACU_ComTUSIDValid_St 1;
BA_ "U_T6_MCA_MY2020_Rx" SG_ 734 ACU_ComTUSIDValid_St 1;
BA_ "U_P702_MY2021_Rx" SG_ 734 ACU_ComTUSIDValid_St 1;
BA_ "GenSigSendType" SG_ 734 ACU_ComTUSIDValid_St 3;
BA_ "U_CD542_MY2021_Tx" SG_ 734 ACU_CurrTUDABBlock_St 1;
BA_ "U_T6_MCA_MY2020_Tx" SG_ 734 ACU_CurrTUDABBlock_St 1;
BA_ "U_P702_MY2021_Tx" SG_ 734 ACU_CurrTUDABBlock_St 1;
BA_ "U_P702_MY2021_Rx" SG_ 734 ACU_CurrTUDABBlock_St 1;
BA_ "U_CD542_MY2021_Rx" SG_ 734 ACU_CurrTUDABBlock_St 1;
BA_ "U_T6_MCA_MY2020_Rx" SG_ 734 ACU_CurrTUDABBlock_St 1;
BA_ "GenSigSendType" SG_ 734 ACU_CurrTUDABBlock_St 3;
BA_ "U_CD542_MY2021_Tx" SG_ 734 ACU_CurrTUDRService_St 1;
BA_ "U_T6_MCA_MY2020_Tx" SG_ 734 ACU_CurrTUDRService_St 1;
BA_ "U_P702_MY2021_Tx" SG_ 734 ACU_CurrTUDRService_St 1;
BA_ "U_CD542_MY2021_Rx" SG_ 734 ACU_CurrTUDRService_St 1;
BA_ "U_T6_MCA_MY2020_Rx" SG_ 734 ACU_CurrTUDRService_St 1;
BA_ "U_P702_MY2021_Rx" SG_ 734 ACU_CurrTUDRService_St 1;
BA_ "GenSigSendType" SG_ 734 ACU_CurrTUDRService_St 3;
BA_ "U_T6_MCA_MY2020_Tx" SG_ 734 ACU_CurrTURadioBand_St 1;
BA_ "U_P702_MY2021_Tx" SG_ 734 ACU_CurrTURadioBand_St 1;
BA_ "GenSigSendType" SG_ 734 ACU_CurrTURadioBand_St 3;
BA_ "U_CD542_MY2021_Tx" SG_ 734 ACU_CurrTUSCIDI_St 1;
BA_ "U_T6_MCA_MY2020_Tx" SG_ 734 ACU_CurrTUSCIDI_St 1;
BA_ "U_P702_MY2021_Tx" SG_ 734 ACU_CurrTUSCIDI_St 1;
BA_ "U_CD542_MY2021_Rx" SG_ 734 ACU_CurrTUSCIDI_St 1;
BA_ "U_T6_MCA_MY2020_Rx" SG_ 734 ACU_CurrTUSCIDI_St 1;
BA_ "U_P702_MY2021_Rx" SG_ 734 ACU_CurrTUSCIDI_St 1;
BA_ "U_CD542_MY2021_Tx" SG_ 734 ACU_CurrTUServiceLink_St 1;
BA_ "U_T6_MCA_MY2020_Tx" SG_ 734 ACU_CurrTUServiceLink_St 1;
BA_ "U_P702_MY2021_Tx" SG_ 734 ACU_CurrTUServiceLink_St 1;
BA_ "U_CD542_MY2021_Rx" SG_ 734 ACU_CurrTUServiceLink_St 1;
BA_ "U_T6_MCA_MY2020_Rx" SG_ 734 ACU_CurrTUServiceLink_St 1;
BA_ "U_P702_MY2021_Rx" SG_ 734 ACU_CurrTUServiceLink_St 1;
BA_ "GenSigSendType" SG_ 734 ACU_CurrTUServiceLink_St 3;
BA_ "U_CD542_MY2021_Tx" SG_ 734 ACU_CurrTUSID_St 1;
BA_ "U_T6_MCA_MY2020_Tx" SG_ 734 ACU_CurrTUSID_St 1;
BA_ "U_P702_MY2021_Tx" SG_ 734 ACU_CurrTUSID_St 1;
BA_ "U_CD542_MY2021_Rx" SG_ 734 ACU_CurrTUSID_St 1;
BA_ "U_T6_MCA_MY2020_Rx" SG_ 734 ACU_CurrTUSID_St 1;
BA_ "U_P702_MY2021_Rx" SG_ 734 ACU_CurrTUSID_St 1;
BA_ "U_CD542_MY2021_Tx" SG_ 1420 ACM_GWOnBoardTester 1;
BA_ "U_T6_MCA_MY2020_Tx" SG_ 1420 ACM_GWOnBoardTester 1;
BA_ "U_P702_MY2021_Tx" SG_ 1420 ACM_GWOnBoardTester 1;
BA_ "GenSigStartValue" SG_ 1420 ACM_GWOnBoardTester 255;
BA_ "ContentDependant" SG_ 1420 ACM_GWOnBoardTester 1;
BA_ "GenSigStartValueInteger" SG_ 1420 ACM_GWOnBoardTester 255;
BA_ "U_CD542_MY2021_Tx" SG_ 1420 ACM_GWNMProxy 1;
BA_ "U_T6_MCA_MY2020_Tx" SG_ 1420 ACM_GWNMProxy 1;
BA_ "U_P702_MY2021_Tx" SG_ 1420 ACM_GWNMProxy 1;
BA_ "GenSigStartValue" SG_ 1420 ACM_GWNMProxy 255;
BA_ "ContentDependant" SG_ 1420 ACM_GWNMProxy 1;
BA_ "GenSigStartValueInteger" SG_ 1420 ACM_GWNMProxy 255;
BA_ "U_CD542_MY2021_Tx" SG_ 1420 ACM_AutoSarNMReserved4 1;
BA_ "U_T6_MCA_MY2020_Tx" SG_ 1420 ACM_AutoSarNMReserved4 1;
BA_ "U_P702_MY2021_Tx" SG_ 1420 ACM_AutoSarNMReserved4 1;
BA_ "GenSigStartValue" SG_ 1420 ACM_AutoSarNMReserved4 255;
BA_ "ContentDependant" SG_ 1420 ACM_AutoSarNMReserved4 1;
BA_ "GenSigStartValueInteger" SG_ 1420 ACM_AutoSarNMReserved4 255;
BA_ "U_CD542_MY2021_Tx" SG_ 1420 ACM_AutoSarNMReserved3 1;
BA_ "U_T6_MCA_MY2020_Tx" SG_ 1420 ACM_AutoSarNMReserved3 1;
BA_ "U_P702_MY2021_Tx" SG_ 1420 ACM_AutoSarNMReserved3 1;
BA_ "GenSigStartValue" SG_ 1420 ACM_AutoSarNMReserved3 255;
BA_ "ContentDependant" SG_ 1420 ACM_AutoSarNMReserved3 1;
BA_ "GenSigStartValueInteger" SG_ 1420 ACM_AutoSarNMReserved3 255;
BA_ "U_CD542_MY2021_Tx" SG_ 1420 ACM_AutoSarNMReserved2 1;
BA_ "U_T6_MCA_MY2020_Tx" SG_ 1420 ACM_AutoSarNMReserved2 1;
BA_ "U_P702_MY2021_Tx" SG_ 1420 ACM_AutoSarNMReserved2 1;
BA_ "GenSigStartValue" SG_ 1420 ACM_AutoSarNMReserved2 255;
BA_ "ContentDependant" SG_ 1420 ACM_AutoSarNMReserved2 1;
BA_ "GenSigStartValueInteger" SG_ 1420 ACM_AutoSarNMReserved2 255;
BA_ "U_CD542_MY2021_Tx" SG_ 1420 ACM_AutoSarNMReserved1 1;
BA_ "U_T6_MCA_MY2020_Tx" SG_ 1420 ACM_AutoSarNMReserved1 1;
BA_ "U_P702_MY2021_Tx" SG_ 1420 ACM_AutoSarNMReserved1 1;
BA_ "GenSigStartValue" SG_ 1420 ACM_AutoSarNMReserved1 255;
BA_ "ContentDependant" SG_ 1420 ACM_AutoSarNMReserved1 1;
BA_ "GenSigStartValueInteger" SG_ 1420 ACM_AutoSarNMReserved1 255;
BA_ "U_CD542_MY2021_Tx" SG_ 1420 ACM_AutoSarNMNodeId 1;
BA_ "U_T6_MCA_MY2020_Tx" SG_ 1420 ACM_AutoSarNMNodeId 1;
BA_ "U_P702_MY2021_Tx" SG_ 1420 ACM_AutoSarNMNodeId 1;
BA_ "GenSigStartValue" SG_ 1420 ACM_AutoSarNMNodeId 140;
BA_ "ContentDependant" SG_ 1420 ACM_AutoSarNMNodeId 1;
BA_ "GenSigStartValueInteger" SG_ 1420 ACM_AutoSarNMNodeId 140;
BA_ "U_CD542_MY2021_Tx" SG_ 1420 ACM_AutoSarNMControl 1;
BA_ "U_T6_MCA_MY2020_Tx" SG_ 1420 ACM_AutoSarNMControl 1;
BA_ "U_P702_MY2021_Tx" SG_ 1420 ACM_AutoSarNMControl 1;
BA_ "ContentDependant" SG_ 1420 ACM_AutoSarNMControl 1;
BA_ "U_CD542_MY2021_Tx" SG_ 759 Avail_HD_Chan_Valid 1;
BA_ "U_T6_MCA_MY2020_Tx" SG_ 759 Avail_HD_Chan_Valid 1;
BA_ "U_P702_MY2021_Tx" SG_ 759 Avail_HD_Chan_Valid 1;
BA_ "U_CD542_MY2021_Rx" SG_ 759 Avail_HD_Chan_Valid 1;
BA_ "U_T6_MCA_MY2020_Rx" SG_ 759 Avail_HD_Chan_Valid 1;
BA_ "GenSigSendType" SG_ 759 Avail_HD_Chan_Valid 3;
BA_ "U_CD542_MY2021_Tx" SG_ 759 Avail_HD_Chan_St_7 1;
BA_ "U_T6_MCA_MY2020_Tx" SG_ 759 Avail_HD_Chan_St_7 1;
BA_ "U_P702_MY2021_Tx" SG_ 759 Avail_HD_Chan_St_7 1;
BA_ "U_CD542_MY2021_Rx" SG_ 759 Avail_HD_Chan_St_7 1;
BA_ "U_T6_MCA_MY2020_Rx" SG_ 759 Avail_HD_Chan_St_7 1;
BA_ "GenSigSendType" SG_ 759 Avail_HD_Chan_St_7 3;
BA_ "U_CD542_MY2021_Tx" SG_ 759 Avail_HD_Chan_St_6 1;
BA_ "U_T6_MCA_MY2020_Tx" SG_ 759 Avail_HD_Chan_St_6 1;
BA_ "U_P702_MY2021_Tx" SG_ 759 Avail_HD_Chan_St_6 1;
BA_ "U_CD542_MY2021_Rx" SG_ 759 Avail_HD_Chan_St_6 1;
BA_ "U_T6_MCA_MY2020_Rx" SG_ 759 Avail_HD_Chan_St_6 1;
BA_ "GenSigSendType" SG_ 759 Avail_HD_Chan_St_6 3;
BA_ "U_CD542_MY2021_Tx" SG_ 759 Avail_HD_Chan_St_5 1;
BA_ "U_T6_MCA_MY2020_Tx" SG_ 759 Avail_HD_Chan_St_5 1;
BA_ "U_P702_MY2021_Tx" SG_ 759 Avail_HD_Chan_St_5 1;
BA_ "U_CD542_MY2021_Rx" SG_ 759 Avail_HD_Chan_St_5 1;
BA_ "U_T6_MCA_MY2020_Rx" SG_ 759 Avail_HD_Chan_St_5 1;
BA_ "GenSigSendType" SG_ 759 Avail_HD_Chan_St_5 3;
BA_ "U_CD542_MY2021_Tx" SG_ 759 Avail_HD_Chan_St_4 1;
BA_ "U_T6_MCA_MY2020_Tx" SG_ 759 Avail_HD_Chan_St_4 1;
BA_ "U_P702_MY2021_Tx" SG_ 759 Avail_HD_Chan_St_4 1;
BA_ "U_CD542_MY2021_Rx" SG_ 759 Avail_HD_Chan_St_4 1;
BA_ "U_T6_MCA_MY2020_Rx" SG_ 759 Avail_HD_Chan_St_4 1;
BA_ "GenSigSendType" SG_ 759 Avail_HD_Chan_St_4 3;
BA_ "U_CD542_MY2021_Tx" SG_ 759 Avail_HD_Chan_St_3 1;
BA_ "U_T6_MCA_MY2020_Tx" SG_ 759 Avail_HD_Chan_St_3 1;
BA_ "U_P702_MY2021_Tx" SG_ 759 Avail_HD_Chan_St_3 1;
BA_ "U_CD542_MY2021_Rx" SG_ 759 Avail_HD_Chan_St_3 1;
BA_ "U_T6_MCA_MY2020_Rx" SG_ 759 Avail_HD_Chan_St_3 1;
BA_ "GenSigSendType" SG_ 759 Avail_HD_Chan_St_3 3;
BA_ "U_CD542_MY2021_Tx" SG_ 759 Avail_HD_Chan_St_2 1;
BA_ "U_T6_MCA_MY2020_Tx" SG_ 759 Avail_HD_Chan_St_2 1;
BA_ "U_P702_MY2021_Tx" SG_ 759 Avail_HD_Chan_St_2 1;
BA_ "U_CD542_MY2021_Rx" SG_ 759 Avail_HD_Chan_St_2 1;
BA_ "U_T6_MCA_MY2020_Rx" SG_ 759 Avail_HD_Chan_St_2 1;
BA_ "GenSigSendType" SG_ 759 Avail_HD_Chan_St_2 3;
BA_ "U_CD542_MY2021_Tx" SG_ 759 Avail_HD_Chan_St_1 1;
BA_ "U_T6_MCA_MY2020_Tx" SG_ 759 Avail_HD_Chan_St_1 1;
BA_ "U_P702_MY2021_Tx" SG_ 759 Avail_HD_Chan_St_1 1;
BA_ "U_CD542_MY2021_Rx" SG_ 759 Avail_HD_Chan_St_1 1;
BA_ "U_T6_MCA_MY2020_Rx" SG_ 759 Avail_HD_Chan_St_1 1;
BA_ "GenSigSendType" SG_ 759 Avail_HD_Chan_St_1 3;
BA_ "U_CD542_MY2021_Tx" SG_ 759 ACM_StationListScanSt 1;
BA_ "U_T6_MCA_MY2020_Tx" SG_ 759 ACM_StationListScanSt 1;
BA_ "U_P702_MY2021_Tx" SG_ 759 ACM_StationListScanSt 1;
BA_ "U_P702_MY2021_Rx" SG_ 759 ACM_StationListScanSt 1;
BA_ "U_CD542_MY2021_Rx" SG_ 759 ACM_StationListScanSt 1;
BA_ "U_T6_MCA_MY2020_Rx" SG_ 759 ACM_StationListScanSt 1;
BA_ "GenSigSendType" SG_ 759 ACM_StationListScanSt 3;
BA_ "U_CD542_MY2021_Tx" SG_ 759 ACM_TagMode 1;
BA_ "U_T6_MCA_MY2020_Tx" SG_ 759 ACM_TagMode 1;
BA_ "U_P702_MY2021_Tx" SG_ 759 ACM_TagMode 1;
BA_ "U_P702_MY2021_Rx" SG_ 759 ACM_TagMode 1;
BA_ "U_CD542_MY2021_Rx" SG_ 759 ACM_TagMode 1;
BA_ "U_T6_MCA_MY2020_Rx" SG_ 759 ACM_TagMode 1;
BA_ "GenSigSendType" SG_ 759 ACM_TagMode 3;
BA_ "U_CD542_MY2021_Tx" SG_ 759 ACM_RBDSMode 1;
BA_ "U_T6_MCA_MY2020_Tx" SG_ 759 ACM_RBDSMode 1;
BA_ "U_P702_MY2021_Tx" SG_ 759 ACM_RBDSMode 1;
BA_ "U_P702_MY2021_Rx" SG_ 759 ACM_RBDSMode 1;
BA_ "U_CD542_MY2021_Rx" SG_ 759 ACM_RBDSMode 1;
BA_ "U_T6_MCA_MY2020_Rx" SG_ 759 ACM_RBDSMode 1;
BA_ "GenSigSendType" SG_ 759 ACM_RBDSMode 3;
BA_ "U_T6_MCA_MY2020_Tx" SG_ 759 NumofHDMulticastChans_St 1;
BA_ "U_P702_MY2021_Tx" SG_ 759 NumofHDMulticastChans_St 1;
BA_ "U_P702_MY2021_Rx" SG_ 759 NumofHDMulticastChans_St 1;
BA_ "U_CD542_MY2021_Rx" SG_ 759 NumofHDMulticastChans_St 1;
BA_ "U_T6_MCA_MY2020_Rx" SG_ 759 NumofHDMulticastChans_St 1;
BA_ "GenSigSendType" SG_ 759 NumofHDMulticastChans_St 3;
BA_ "U_CD542_MY2021_Tx" SG_ 759 ACM_HDModeStatus 1;
BA_ "U_T6_MCA_MY2020_Tx" SG_ 759 ACM_HDModeStatus 1;
BA_ "U_P702_MY2021_Tx" SG_ 759 ACM_HDModeStatus 1;
BA_ "U_P702_MY2021_Rx" SG_ 759 ACM_HDModeStatus 1;
BA_ "U_CD542_MY2021_Rx" SG_ 759 ACM_HDModeStatus 1;
BA_ "U_T6_MCA_MY2020_Rx" SG_ 759 ACM_HDModeStatus 1;
BA_ "GenSigSendType" SG_ 759 ACM_HDModeStatus 3;
BA_ "U_CD542_MY2021_Tx" SG_ 759 ACM_HDChanStatus 1;
BA_ "U_T6_MCA_MY2020_Tx" SG_ 759 ACM_HDChanStatus 1;
BA_ "U_P702_MY2021_Tx" SG_ 759 ACM_HDChanStatus 1;
BA_ "U_P702_MY2021_Rx" SG_ 759 ACM_HDChanStatus 1;
BA_ "U_CD542_MY2021_Rx" SG_ 759 ACM_HDChanStatus 1;
BA_ "U_T6_MCA_MY2020_Rx" SG_ 759 ACM_HDChanStatus 1;
BA_ "GenSigSendType" SG_ 759 ACM_HDChanStatus 3;
BA_ "U_CD542_MY2021_Tx" SG_ 759 ACM_CurrentSSName 1;
BA_ "U_T6_MCA_MY2020_Tx" SG_ 759 ACM_CurrentSSName 1;
BA_ "U_P702_MY2021_Tx" SG_ 759 ACM_CurrentSSName 1;
BA_ "U_P702_MY2021_Rx" SG_ 759 ACM_CurrentSSName 1;
BA_ "U_CD542_MY2021_Rx" SG_ 759 ACM_CurrentSSName 1;
BA_ "U_T6_MCA_MY2020_Rx" SG_ 759 ACM_CurrentSSName 1;
BA_ "GenSigSendType" SG_ 759 ACM_CurrentSSName 3;
BA_ "U_T6_MCA_MY2020_Tx" SG_ 759 ACM_CurrentHDMulticast_St 1;
BA_ "U_P702_MY2021_Tx" SG_ 759 ACM_CurrentHDMulticast_St 1;
BA_ "U_P702_MY2021_Rx" SG_ 759 ACM_CurrentHDMulticast_St 1;
BA_ "U_CD542_MY2021_Rx" SG_ 759 ACM_CurrentHDMulticast_St 1;
BA_ "U_T6_MCA_MY2020_Rx" SG_ 759 ACM_CurrentHDMulticast_St 1;
BA_ "GenSigSendType" SG_ 759 ACM_CurrentHDMulticast_St 3;
BA_ "U_CD542_MY2021_Tx" SG_ 144 SetTimeFormat 1;
BA_ "U_T6_MCA_MY2020_Tx" SG_ 144 SetTimeFormat 1;
BA_ "U_P702_MY2021_Tx" SG_ 144 SetTimeFormat 1;
BA_ "GenSigSendType" SG_ 144 SetTimeFormat 3;
BA_ "U_CD542_MY2021_Tx" SG_ 144 SetYear 1;
BA_ "U_T6_MCA_MY2020_Tx" SG_ 144 SetYear 1;
BA_ "U_P702_MY2021_Tx" SG_ 144 SetYear 1;
BA_ "U_CD542_MY2021_Tx" SG_ 144 SetMonth 1;
BA_ "U_T6_MCA_MY2020_Tx" SG_ 144 SetMonth 1;
BA_ "U_P702_MY2021_Tx" SG_ 144 SetMonth 1;
BA_ "U_CD542_MY2021_Tx" SG_ 144 SetDay 1;
BA_ "U_T6_MCA_MY2020_Tx" SG_ 144 SetDay 1;
BA_ "U_P702_MY2021_Tx" SG_ 144 SetDay 1;
BA_ "U_CD542_MY2021_Tx" SG_ 144 SetHour 1;
BA_ "U_T6_MCA_MY2020_Tx" SG_ 144 SetHour 1;
BA_ "U_P702_MY2021_Tx" SG_ 144 SetHour 1;
BA_ "U_CD542_MY2021_Tx" SG_ 144 SetMinute 1;
BA_ "U_T6_MCA_MY2020_Tx" SG_ 144 SetMinute 1;
BA_ "U_P702_MY2021_Tx" SG_ 144 SetMinute 1;
BA_ "U_CD542_MY2021_Tx" SG_ 144 SetSecond 1;
BA_ "U_T6_MCA_MY2020_Tx" SG_ 144 SetSecond 1;
BA_ "U_P702_MY2021_Tx" SG_ 144 SetSecond 1;
BA_ "U_CD542_MY2021_Tx" SG_ 144 TimeAdjustRequest 1;
BA_ "U_T6_MCA_MY2020_Tx" SG_ 144 TimeAdjustRequest 1;
BA_ "U_P702_MY2021_Tx" SG_ 144 TimeAdjustRequest 1;
BA_ "GenSigSendType" SG_ 144 TimeAdjustRequest 3;
BA_ "U_CD542_MY2021_Tx" SG_ 144 DateAdjustRequest 1;
BA_ "U_T6_MCA_MY2020_Tx" SG_ 144 DateAdjustRequest 1;
BA_ "U_P702_MY2021_Tx" SG_ 144 DateAdjustRequest 1;
BA_ "U_T6_MCA_MY2020_Rx" SG_ 144 DateAdjustRequest 1;
BA_ "GenSigSendType" SG_ 144 DateAdjustRequest 3;
BA_ "U_CD542_MY2021_Tx" SG_ 851 ConsLongTerm_No_Dsply 1;
BA_ "U_T6_MCA_MY2020_Tx" SG_ 851 ConsLongTerm_No_Dsply 1;
BA_ "U_P702_MY2021_Tx" SG_ 851 ConsLongTerm_No_Dsply 1;
BA_ "U_U55X_MY2022_Rx" SG_ 851 ConsLongTerm_No_Dsply 1;
BA_ "ECGUsedRxSignal" SG_ 851 ConsLongTerm_No_Dsply 1;
BA_ "U_T6_MCA_MY2020_Rx" SG_ 851 ConsLongTerm_No_Dsply 1;
BA_ "U_CD542_MY2021_Tx" SG_ 851 ConsUnitIPC_D_Dsply 1;
BA_ "U_T6_MCA_MY2020_Tx" SG_ 851 ConsUnitIPC_D_Dsply 1;
BA_ "U_P702_MY2021_Tx" SG_ 851 ConsUnitIPC_D_Dsply 1;
BA_ "U_U55X_MY2022_Rx" SG_ 851 ConsUnitIPC_D_Dsply 1;
BA_ "ECGUsedRxSignal" SG_ 851 ConsUnitIPC_D_Dsply 1;
BA_ "U_CD542_MY2021_Rx" SG_ 851 ConsUnitIPC_D_Dsply 1;
BA_ "U_T6_MCA_MY2020_Rx" SG_ 851 ConsUnitIPC_D_Dsply 1;
BA_ "U_P702_MY2021_Rx" SG_ 851 ConsUnitIPC_D_Dsply 1;
BA_ "GenSigSendType" SG_ 851 ConsUnitIPC_D_Dsply 3;
BA_ "U_CD542_MY2021_Tx" SG_ 851 ConsAvgTrip_No_Dsply 1;
BA_ "U_T6_MCA_MY2020_Tx" SG_ 851 ConsAvgTrip_No_Dsply 1;
BA_ "U_P702_MY2021_Tx" SG_ 851 ConsAvgTrip_No_Dsply 1;
BA_ "U_U55X_MY2022_Rx" SG_ 851 ConsAvgTrip_No_Dsply 1;
BA_ "ECGUsedRxSignal" SG_ 851 ConsAvgTrip_No_Dsply 1;
BA_ "U_T6_MCA_MY2020_Rx" SG_ 851 ConsAvgTrip_No_Dsply 1;
BA_ "U_CD542_MY2021_Tx" SG_ 792 FuelRange_L_Dsply 1;
BA_ "U_T6_MCA_MY2020_Tx" SG_ 792 FuelRange_L_Dsply 1;
BA_ "U_P702_MY2021_Tx" SG_ 792 FuelRange_L_Dsply 1;
BA_ "U_U55X_MY2022_Rx" SG_ 792 FuelRange_L_Dsply 1;
BA_ "ECGUsedRxSignal" SG_ 792 FuelRange_L_Dsply 1;
BA_ "U_CD542_MY2021_Rx" SG_ 792 FuelRange_L_Dsply 1;
BA_ "U_T6_MCA_MY2020_Rx" SG_ 792 FuelRange_L_Dsply 1;
BA_ "U_P702_MY2021_Rx" SG_ 792 FuelRange_L_Dsply 1;
BA_ "U_CD542_MY2021_Tx" SG_ 792 ElTrip_L_Dsply 1;
BA_ "U_T6_MCA_MY2020_Tx" SG_ 792 ElTrip_L_Dsply 1;
BA_ "U_P702_MY2021_Tx" SG_ 792 ElTrip_L_Dsply 1;
BA_ "U_U55X_MY2022_Rx" SG_ 792 ElTrip_L_Dsply 1;
BA_ "ECGUsedRxSignal" SG_ 792 ElTrip_L_Dsply 1;
BA_ "U_T6_MCA_MY2020_Rx" SG_ 792 ElTrip_L_Dsply 1;
BA_ "ContentDependant" SG_ 792 ElTrip_L_Dsply 1;
BA_ "U_CD542_MY2021_Tx" SG_ 792 ElLongTerm_L_Dsply 1;
BA_ "U_T6_MCA_MY2020_Tx" SG_ 792 ElLongTerm_L_Dsply 1;
BA_ "U_P702_MY2021_Tx" SG_ 792 ElLongTerm_L_Dsply 1;
BA_ "U_U55X_MY2022_Rx" SG_ 792 ElLongTerm_L_Dsply 1;
BA_ "ECGUsedRxSignal" SG_ 792 ElLongTerm_L_Dsply 1;
BA_ "U_T6_MCA_MY2020_Rx" SG_ 792 ElLongTerm_L_Dsply 1;
BA_ "ContentDependant" SG_ 792 ElLongTerm_L_Dsply 1;
BA_ "U_CD542_MY2021_Tx" SG_ 787 VehElSurpStat_L_Dsply 1;
BA_ "U_T6_MCA_MY2020_Tx" SG_ 787 VehElSurpStat_L_Dsply 1;
BA_ "U_P702_MY2021_Tx" SG_ 787 VehElSurpStat_L_Dsply 1;
BA_ "U_CD542_MY2021_Tx" SG_ 787 TripSum_Vl_Dsply 1;
BA_ "U_T6_MCA_MY2020_Tx" SG_ 787 TripSum_Vl_Dsply 1;
BA_ "U_P702_MY2021_Tx" SG_ 787 TripSum_Vl_Dsply 1;
BA_ "U_U55X_MY2022_Rx" SG_ 787 TripSum_Vl_Dsply 1;
BA_ "ECGUsedRxSignal" SG_ 787 TripSum_Vl_Dsply 1;
BA_ "U_T6_MCA_MY2020_Rx" SG_ 787 TripSum_Vl_Dsply 1;
BA_ "U_CD542_MY2021_Tx" SG_ 787 TripSum_E_Dsply 1;
BA_ "U_T6_MCA_MY2020_Tx" SG_ 787 TripSum_E_Dsply 1;
BA_ "U_P702_MY2021_Tx" SG_ 787 TripSum_E_Dsply 1;
BA_ "U_U55X_MY2022_Rx" SG_ 787 TripSum_E_Dsply 1;
BA_ "ECGUsedRxSignal" SG_ 787 TripSum_E_Dsply 1;
BA_ "U_T6_MCA_MY2020_Rx" SG_ 787 TripSum_E_Dsply 1;
BA_ "U_CD542_MY2021_Tx" SG_ 787 TripSum_L_Dsply 1;
BA_ "U_T6_MCA_MY2020_Tx" SG_ 787 TripSum_L_Dsply 1;
BA_ "U_P702_MY2021_Tx" SG_ 787 TripSum_L_Dsply 1;
BA_ "U_U55X_MY2022_Rx" SG_ 787 TripSum_L_Dsply 1;
BA_ "ECGUsedRxSignal" SG_ 787 TripSum_L_Dsply 1;
BA_ "U_T6_MCA_MY2020_Rx" SG_ 787 TripSum_L_Dsply 1;
BA_ "U_CD542_MY2021_Tx" SG_ 697 AUDIO_MC_WORD_Rx 1;
BA_ "U_T6_MCA_MY2020_Tx" SG_ 697 AUDIO_MC_WORD_Rx 1;
BA_ "U_CD542_MY2021_Rx" SG_ 697 AUDIO_MC_WORD_Rx 1;
BA_ "U_T6_MCA_MY2020_Rx" SG_ 697 AUDIO_MC_WORD_Rx 1;
BA_ "U_P702_MY2021_Rx" SG_ 697 AUDIO_MC_WORD_Rx 1;
BA_ "U_CD542_MY2021_Tx" SG_ 700 AUDIO_RDISP_WORD_Rx 1;
BA_ "U_T6_MCA_MY2020_Tx" SG_ 700 AUDIO_RDISP_WORD_Rx 1;
BA_ "U_P702_MY2021_Tx" SG_ 700 AUDIO_RDISP_WORD_Rx 1;
BA_ "U_CD542_MY2021_Rx" SG_ 700 AUDIO_RDISP_WORD_Rx 1;
BA_ "U_T6_MCA_MY2020_Rx" SG_ 700 AUDIO_RDISP_WORD_Rx 1;
BA_ "U_P702_MY2021_Rx" SG_ 700 AUDIO_RDISP_WORD_Rx 1;
BA_ "U_CD542_MY2021_Tx" SG_ 676 MC_RDISP_WORD_Tx 1;
BA_ "U_T6_MCA_MY2020_Tx" SG_ 676 MC_RDISP_WORD_Tx 1;
BA_ "U_CD542_MY2021_Rx" SG_ 676 MC_RDISP_WORD_Tx 1;
BA_ "U_T6_MCA_MY2020_Rx" SG_ 676 MC_RDISP_WORD_Tx 1;
BA_ "U_P702_MY2021_Rx" SG_ 676 MC_RDISP_WORD_Tx 1;
BA_ "GenSigSendType" SG_ 676 MC_RDISP_WORD_Tx 3;
BA_ "U_T6_MCA_MY2020_Tx" SG_ 504 Mc_AudioSourceSel_Rq 1;
BA_ "U_T6_MCA_MY2020_Rx" SG_ 504 Mc_AudioSourceSel_Rq 1;
BA_ "GenSigSendType" SG_ 504 Mc_AudioSourceSel_Rq 3;
BA_ "U_T6_MCA_MY2020_Tx" SG_ 504 Mc_FolderNumber_Rq 1;
BA_ "U_T6_MCA_MY2020_Rx" SG_ 504 Mc_FolderNumber_Rq 1;
BA_ "U_T6_MCA_MY2020_Tx" SG_ 504 Mc_CutItem_Rq 1;
BA_ "U_T6_MCA_MY2020_Rx" SG_ 504 Mc_CutItem_Rq 1;
BA_ "U_T6_MCA_MY2020_Tx" SG_ 504 Mc_ItemNameLength_Rq 1;
BA_ "U_T6_MCA_MY2020_Rx" SG_ 504 Mc_ItemNameLength_Rq 1;
BA_ "U_T6_MCA_MY2020_Tx" SG_ 504 Mc_SourceSetTrack_Rq 1;
BA_ "U_T6_MCA_MY2020_Rx" SG_ 504 Mc_SourceSetTrack_Rq 1;
BA_ "U_CD542_MY2021_Tx" SG_ 410 MyKey_e911Override_St 1;
BA_ "U_T6_MCA_MY2020_Tx" SG_ 410 MyKey_e911Override_St 1;
BA_ "U_P702_MY2021_Tx" SG_ 410 MyKey_e911Override_St 1;
BA_ "U_CD542_MY2021_Rx" SG_ 410 MyKey_e911Override_St 1;
BA_ "U_T6_MCA_MY2020_Rx" SG_ 410 MyKey_e911Override_St 1;
BA_ "U_P702_MY2021_Rx" SG_ 410 MyKey_e911Override_St 1;
BA_ "GenSigSendType" SG_ 410 MyKey_e911Override_St 3;
BA_ "U_CD542_MY2021_Tx" SG_ 410 DoNotDisturbOveride_St 1;
BA_ "U_T6_MCA_MY2020_Tx" SG_ 410 DoNotDisturbOveride_St 1;
BA_ "U_P702_MY2021_Tx" SG_ 410 DoNotDisturbOveride_St 1;
BA_ "U_CD542_MY2021_Rx" SG_ 410 DoNotDisturbOveride_St 1;
BA_ "U_T6_MCA_MY2020_Rx" SG_ 410 DoNotDisturbOveride_St 1;
BA_ "U_P702_MY2021_Rx" SG_ 410 DoNotDisturbOveride_St 1;
BA_ "GenSigSendType" SG_ 410 DoNotDisturbOveride_St 3;
BA_ "U_CD542_MY2021_Tx" SG_ 1124 GPS_Vdop 1;
BA_ "U_T6_MCA_MY2020_Tx" SG_ 1124 GPS_Vdop 1;
BA_ "U_P702_MY2021_Tx" SG_ 1124 GPS_Vdop 1;
BA_ "GenSigSendType" SG_ 1124 GPS_Vdop 1;
BA_ "U_CD542_MY2021_Tx" SG_ 1124 GPS_Speed 1;
BA_ "U_T6_MCA_MY2020_Tx" SG_ 1124 GPS_Speed 1;
BA_ "U_P702_MY2021_Tx" SG_ 1124 GPS_Speed 1;
BA_ "U_U55X_MY2022_Rx" SG_ 1124 GPS_Speed 1;
BA_ "ECGUsedRxSignal" SG_ 1124 GPS_Speed 1;
BA_ "U_T6_MCA_MY2020_Rx" SG_ 1124 GPS_Speed 1;
BA_ "U_CD542_MY2021_Tx" SG_ 1124 GPS_Sat_num_in_view 1;
BA_ "U_T6_MCA_MY2020_Tx" SG_ 1124 GPS_Sat_num_in_view 1;
BA_ "U_P702_MY2021_Tx" SG_ 1124 GPS_Sat_num_in_view 1;
BA_ "U_CD542_MY2021_Tx" SG_ 1124 GPS_MSL_altitude 1;
BA_ "U_T6_MCA_MY2020_Tx" SG_ 1124 GPS_MSL_altitude 1;
BA_ "U_P702_MY2021_Tx" SG_ 1124 GPS_MSL_altitude 1;
BA_ "U_U55X_MY2022_Rx" SG_ 1124 GPS_MSL_altitude 1;
BA_ "ECGUsedRxSignal" SG_ 1124 GPS_MSL_altitude 1;
BA_ "U_T6_MCA_MY2020_Rx" SG_ 1124 GPS_MSL_altitude 1;
BA_ "U_CD542_MY2021_Tx" SG_ 1124 GPS_Heading 1;
BA_ "U_T6_MCA_MY2020_Tx" SG_ 1124 GPS_Heading 1;
BA_ "U_P702_MY2021_Tx" SG_ 1124 GPS_Heading 1;
BA_ "U_U55X_MY2022_Rx" SG_ 1124 GPS_Heading 1;
BA_ "ECGUsedRxSignal" SG_ 1124 GPS_Heading 1;
BA_ "U_T6_MCA_MY2020_Rx" SG_ 1124 GPS_Heading 1;
BA_ "U_CD542_MY2021_Tx" SG_ 1124 GPS_Hdop 1;
BA_ "U_T6_MCA_MY2020_Tx" SG_ 1124 GPS_Hdop 1;
BA_ "U_P702_MY2021_Tx" SG_ 1124 GPS_Hdop 1;
BA_ "U_CD542_MY2021_Tx" SG_ 1124 GPS_dimension 1;
BA_ "U_T6_MCA_MY2020_Tx" SG_ 1124 GPS_dimension 1;
BA_ "U_P702_MY2021_Tx" SG_ 1124 GPS_dimension 1;
BA_ "U_U55X_MY2022_Rx" SG_ 1124 GPS_dimension 1;
BA_ "ECGUsedRxSignal" SG_ 1124 GPS_dimension 1;
BA_ "U_T6_MCA_MY2020_Rx" SG_ 1124 GPS_dimension 1;
BA_ "U_CD542_MY2021_Tx" SG_ 1123 GpsUtcYr_No_Actl 1;
BA_ "U_T6_MCA_MY2020_Tx" SG_ 1123 GpsUtcYr_No_Actl 1;
BA_ "U_P702_MY2021_Tx" SG_ 1123 GpsUtcYr_No_Actl 1;
BA_ "U_U55X_MY2022_Rx" SG_ 1123 GpsUtcYr_No_Actl 1;
BA_ "ECGUsedRxSignal" SG_ 1123 GpsUtcYr_No_Actl 1;
BA_ "U_T6_MCA_MY2020_Rx" SG_ 1123 GpsUtcYr_No_Actl 1;
BA_ "U_CD542_MY2021_Tx" SG_ 1123 GpsUtcMnth_No_Actl 1;
BA_ "U_T6_MCA_MY2020_Tx" SG_ 1123 GpsUtcMnth_No_Actl 1;
BA_ "U_P702_MY2021_Tx" SG_ 1123 GpsUtcMnth_No_Actl 1;
BA_ "U_U55X_MY2022_Rx" SG_ 1123 GpsUtcMnth_No_Actl 1;
BA_ "ECGUsedRxSignal" SG_ 1123 GpsUtcMnth_No_Actl 1;
BA_ "U_T6_MCA_MY2020_Rx" SG_ 1123 GpsUtcMnth_No_Actl 1;
BA_ "GenSigStartValue" SG_ 1123 GpsUtcMnth_No_Actl 1;
BA_ "GenSigStartValueInteger" SG_ 1123 GpsUtcMnth_No_Actl 1;
BA_ "U_CD542_MY2021_Tx" SG_ 1123 GpsUtcDay_No_Actl 1;
BA_ "U_T6_MCA_MY2020_Tx" SG_ 1123 GpsUtcDay_No_Actl 1;
BA_ "U_P702_MY2021_Tx" SG_ 1123 GpsUtcDay_No_Actl 1;
BA_ "U_U55X_MY2022_Rx" SG_ 1123 GpsUtcDay_No_Actl 1;
BA_ "ECGUsedRxSignal" SG_ 1123 GpsUtcDay_No_Actl 1;
BA_ "U_T6_MCA_MY2020_Rx" SG_ 1123 GpsUtcDay_No_Actl 1;
BA_ "GenSigStartValue" SG_ 1123 GpsUtcDay_No_Actl 1;
BA_ "GenSigStartValueInteger" SG_ 1123 GpsUtcDay_No_Actl 1;
BA_ "U_CD542_MY2021_Tx" SG_ 1123 GPS_UTC_seconds 1;
BA_ "U_T6_MCA_MY2020_Tx" SG_ 1123 GPS_UTC_seconds 1;
BA_ "U_P702_MY2021_Tx" SG_ 1123 GPS_UTC_seconds 1;
BA_ "U_U55X_MY2022_Rx" SG_ 1123 GPS_UTC_seconds 1;
BA_ "ECGUsedRxSignal" SG_ 1123 GPS_UTC_seconds 1;
BA_ "U_T6_MCA_MY2020_Rx" SG_ 1123 GPS_UTC_seconds 1;
BA_ "U_CD542_MY2021_Tx" SG_ 1123 GPS_UTC_minutes 1;
BA_ "U_T6_MCA_MY2020_Tx" SG_ 1123 GPS_UTC_minutes 1;
BA_ "U_P702_MY2021_Tx" SG_ 1123 GPS_UTC_minutes 1;
BA_ "U_U55X_MY2022_Rx" SG_ 1123 GPS_UTC_minutes 1;
BA_ "ECGUsedRxSignal" SG_ 1123 GPS_UTC_minutes 1;
BA_ "U_T6_MCA_MY2020_Rx" SG_ 1123 GPS_UTC_minutes 1;
BA_ "U_CD542_MY2021_Tx" SG_ 1123 GPS_UTC_hours 1;
BA_ "U_T6_MCA_MY2020_Tx" SG_ 1123 GPS_UTC_hours 1;
BA_ "U_P702_MY2021_Tx" SG_ 1123 GPS_UTC_hours 1;
BA_ "U_U55X_MY2022_Rx" SG_ 1123 GPS_UTC_hours 1;
BA_ "ECGUsedRxSignal" SG_ 1123 GPS_UTC_hours 1;
BA_ "U_T6_MCA_MY2020_Rx" SG_ 1123 GPS_UTC_hours 1;
BA_ "U_CD542_MY2021_Tx" SG_ 1123 GPS_Pdop 1;
BA_ "U_T6_MCA_MY2020_Tx" SG_ 1123 GPS_Pdop 1;
BA_ "U_P702_MY2021_Tx" SG_ 1123 GPS_Pdop 1;
BA_ "U_CD542_MY2021_Tx" SG_ 1123 GPS_Compass_direction 1;
BA_ "U_T6_MCA_MY2020_Tx" SG_ 1123 GPS_Compass_direction 1;
BA_ "U_P702_MY2021_Tx" SG_ 1123 GPS_Compass_direction 1;
BA_ "U_U55X_MY2022_Rx" SG_ 1123 GPS_Compass_direction 1;
BA_ "ECGUsedRxSignal" SG_ 1123 GPS_Compass_direction 1;
BA_ "U_CD542_MY2021_Rx" SG_ 1123 GPS_Compass_direction 1;
BA_ "U_T6_MCA_MY2020_Rx" SG_ 1123 GPS_Compass_direction 1;
BA_ "U_CD542_MY2021_Tx" SG_ 1123 GPS_Actual_vs_Infer_pos 1;
BA_ "U_T6_MCA_MY2020_Tx" SG_ 1123 GPS_Actual_vs_Infer_pos 1;
BA_ "U_P702_MY2021_Tx" SG_ 1123 GPS_Actual_vs_Infer_pos 1;
BA_ "U_U55X_MY2022_Rx" SG_ 1123 GPS_Actual_vs_Infer_pos 1;
BA_ "ECGUsedRxSignal" SG_ 1123 GPS_Actual_vs_Infer_pos 1;
BA_ "U_T6_MCA_MY2020_Rx" SG_ 1123 GPS_Actual_vs_Infer_pos 1;
BA_ "GenSigSendType" SG_ 1123 GPS_Actual_vs_Infer_pos 1;
BA_ "U_CD542_MY2021_Tx" SG_ 1123 Gps_B_Falt 1;
BA_ "U_T6_MCA_MY2020_Tx" SG_ 1123 Gps_B_Falt 1;
BA_ "U_P702_MY2021_Tx" SG_ 1123 Gps_B_Falt 1;
BA_ "U_U55X_MY2022_Rx" SG_ 1123 Gps_B_Falt 1;
BA_ "ECGUsedRxSignal" SG_ 1123 Gps_B_Falt 1;
BA_ "U_T6_MCA_MY2020_Rx" SG_ 1123 Gps_B_Falt 1;
BA_ "U_CD542_MY2021_Tx" SG_ 1122 GpsHsphLongEast_D_Actl 1;
BA_ "U_T6_MCA_MY2020_Tx" SG_ 1122 GpsHsphLongEast_D_Actl 1;
BA_ "U_P702_MY2021_Tx" SG_ 1122 GpsHsphLongEast_D_Actl 1;
BA_ "U_U55X_MY2022_Rx" SG_ 1122 GpsHsphLongEast_D_Actl 1;
BA_ "ECGUsedRxSignal" SG_ 1122 GpsHsphLongEast_D_Actl 1;
BA_ "U_T6_MCA_MY2020_Rx" SG_ 1122 GpsHsphLongEast_D_Actl 1;
BA_ "GenSigSendType" SG_ 1122 GpsHsphLongEast_D_Actl 1;
BA_ "U_CD542_MY2021_Tx" SG_ 1122 GpsHsphLattSth_D_Actl 1;
BA_ "U_T6_MCA_MY2020_Tx" SG_ 1122 GpsHsphLattSth_D_Actl 1;
BA_ "U_P702_MY2021_Tx" SG_ 1122 GpsHsphLattSth_D_Actl 1;
BA_ "U_U55X_MY2022_Rx" SG_ 1122 GpsHsphLattSth_D_Actl 1;
BA_ "ECGUsedRxSignal" SG_ 1122 GpsHsphLattSth_D_Actl 1;
BA_ "U_T6_MCA_MY2020_Rx" SG_ 1122 GpsHsphLattSth_D_Actl 1;
BA_ "U_CD542_MY2021_Tx" SG_ 1122 GPS_Longitude_Minutes 1;
BA_ "U_T6_MCA_MY2020_Tx" SG_ 1122 GPS_Longitude_Minutes 1;
BA_ "U_P702_MY2021_Tx" SG_ 1122 GPS_Longitude_Minutes 1;
BA_ "U_U55X_MY2022_Rx" SG_ 1122 GPS_Longitude_Minutes 1;
BA_ "ECGUsedRxSignal" SG_ 1122 GPS_Longitude_Minutes 1;
BA_ "U_T6_MCA_MY2020_Rx" SG_ 1122 GPS_Longitude_Minutes 1;
BA_ "U_CD542_MY2021_Tx" SG_ 1122 GPS_Longitude_Min_dec 1;
BA_ "U_T6_MCA_MY2020_Tx" SG_ 1122 GPS_Longitude_Min_dec 1;
BA_ "U_P702_MY2021_Tx" SG_ 1122 GPS_Longitude_Min_dec 1;
BA_ "U_U55X_MY2022_Rx" SG_ 1122 GPS_Longitude_Min_dec 1;
BA_ "ECGUsedRxSignal" SG_ 1122 GPS_Longitude_Min_dec 1;
BA_ "U_T6_MCA_MY2020_Rx" SG_ 1122 GPS_Longitude_Min_dec 1;
BA_ "U_CD542_MY2021_Tx" SG_ 1122 GPS_Longitude_Degrees 1;
BA_ "U_T6_MCA_MY2020_Tx" SG_ 1122 GPS_Longitude_Degrees 1;
BA_ "U_P702_MY2021_Tx" SG_ 1122 GPS_Longitude_Degrees 1;
BA_ "U_U55X_MY2022_Rx" SG_ 1122 GPS_Longitude_Degrees 1;
BA_ "ECGUsedRxSignal" SG_ 1122 GPS_Longitude_Degrees 1;
BA_ "U_T6_MCA_MY2020_Rx" SG_ 1122 GPS_Longitude_Degrees 1;
BA_ "GenSigStartValueInteger" SG_ 1122 GPS_Longitude_Degrees 179;
BA_ "U_CD542_MY2021_Tx" SG_ 1122 GPS_Latitude_Minutes 1;
BA_ "U_T6_MCA_MY2020_Tx" SG_ 1122 GPS_Latitude_Minutes 1;
BA_ "U_P702_MY2021_Tx" SG_ 1122 GPS_Latitude_Minutes 1;
BA_ "U_U55X_MY2022_Rx" SG_ 1122 GPS_Latitude_Minutes 1;
BA_ "ECGUsedRxSignal" SG_ 1122 GPS_Latitude_Minutes 1;
BA_ "U_T6_MCA_MY2020_Rx" SG_ 1122 GPS_Latitude_Minutes 1;
BA_ "U_CD542_MY2021_Tx" SG_ 1122 GPS_Latitude_Min_dec 1;
BA_ "U_T6_MCA_MY2020_Tx" SG_ 1122 GPS_Latitude_Min_dec 1;
BA_ "U_P702_MY2021_Tx" SG_ 1122 GPS_Latitude_Min_dec 1;
BA_ "U_U55X_MY2022_Rx" SG_ 1122 GPS_Latitude_Min_dec 1;
BA_ "ECGUsedRxSignal" SG_ 1122 GPS_Latitude_Min_dec 1;
BA_ "U_T6_MCA_MY2020_Rx" SG_ 1122 GPS_Latitude_Min_dec 1;
BA_ "U_CD542_MY2021_Tx" SG_ 1122 GPS_Latitude_Degrees 1;
BA_ "U_T6_MCA_MY2020_Tx" SG_ 1122 GPS_Latitude_Degrees 1;
BA_ "U_P702_MY2021_Tx" SG_ 1122 GPS_Latitude_Degrees 1;
BA_ "U_U55X_MY2022_Rx" SG_ 1122 GPS_Latitude_Degrees 1;
BA_ "ECGUsedRxSignal" SG_ 1122 GPS_Latitude_Degrees 1;
BA_ "U_T6_MCA_MY2020_Rx" SG_ 1122 GPS_Latitude_Degrees 1;
BA_ "U_CD542_MY2021_Rx" SG_ 1131 EsaOn_B_Stat_UB 1;
BA_ "U_T6_MCA_MY2020_Rx" SG_ 1131 EsaOn_B_Stat_UB 1;
BA_ "U_P702_MY2021_Rx" SG_ 1131 EsaOn_B_Stat_UB 1;
BA_ "U_CD542_MY2021_Rx" SG_ 1131 EsaOn_B_Stat 1;
BA_ "U_T6_MCA_MY2020_Rx" SG_ 1131 EsaOn_B_Stat 1;
BA_ "U_P702_MY2021_Rx" SG_ 1131 EsaOn_B_Stat 1;
BA_ "GenSigSendType" SG_ 1131 EsaOn_B_Stat 3;
BA_ "GenSigStartValue" SG_ 1131 EsaOn_B_Stat 1;
BA_ "GenSigStartValueInteger" SG_ 1131 EsaOn_B_Stat 1;
BA_ "GenSigSendType" SG_ 1131 WiprFrontSwtch_D_Stat 3;
BA_ "GenSigStartValue" SG_ 1131 WiprFrontSwtch_D_Stat 9;
BA_ "GenSigStartValueInteger" SG_ 1131 WiprFrontSwtch_D_Stat 9;
BA_ "U_CD542_MY2021_Rx" SG_ 1131 HeadLghtHiOn_B_StatAhb_UB 1;
BA_ "U_T6_MCA_MY2020_Rx" SG_ 1131 HeadLghtHiOn_B_StatAhb_UB 1;
BA_ "U_P702_MY2021_Rx" SG_ 1131 HeadLghtHiOn_B_StatAhb_UB 1;
BA_ "U_CD542_MY2021_Rx" SG_ 1131 HeadLghtHiOn_B_StatAhb 1;
BA_ "U_T6_MCA_MY2020_Rx" SG_ 1131 HeadLghtHiOn_B_StatAhb 1;
BA_ "U_P702_MY2021_Rx" SG_ 1131 HeadLghtHiOn_B_StatAhb 1;
BA_ "GenSigSendType" SG_ 1131 HeadLghtHiOn_B_StatAhb 3;
BA_ "WakeupSignal" SG_ 1131 HeadLghtHiOn_B_StatAhb 1;
BA_ "U_CD542_MY2021_Rx" SG_ 1131 AhbStat_B_Dsply_UB 1;
BA_ "U_T6_MCA_MY2020_Rx" SG_ 1131 AhbStat_B_Dsply_UB 1;
BA_ "U_P702_MY2021_Rx" SG_ 1131 AhbStat_B_Dsply_UB 1;
BA_ "U_CD542_MY2021_Rx" SG_ 1131 AhbStat_B_Dsply 1;
BA_ "U_T6_MCA_MY2020_Rx" SG_ 1131 AhbStat_B_Dsply 1;
BA_ "U_P702_MY2021_Rx" SG_ 1131 AhbStat_B_Dsply 1;
BA_ "GenSigSendType" SG_ 1131 AhbStat_B_Dsply 3;
BA_ "U_CD542_MY2021_Rx" SG_ 1131 RearDiffSrvcRqd_B_Rq_UB 1;
BA_ "U_T6_MCA_MY2020_Rx" SG_ 1131 RearDiffSrvcRqd_B_Rq_UB 1;
BA_ "U_P702_MY2021_Rx" SG_ 1131 RearDiffSrvcRqd_B_Rq_UB 1;
BA_ "U_CD542_MY2021_Rx" SG_ 1131 PtLatchActv_B_RqBcm_UB 1;
BA_ "U_T6_MCA_MY2020_Rx" SG_ 1131 PtLatchActv_B_RqBcm_UB 1;
BA_ "U_P702_MY2021_Rx" SG_ 1131 PtLatchActv_B_RqBcm_UB 1;
BA_ "U_CD542_MY2021_Rx" SG_ 1131 RearDiffSrvcRqd_B_Rq 1;
BA_ "U_T6_MCA_MY2020_Rx" SG_ 1131 RearDiffSrvcRqd_B_Rq 1;
BA_ "U_P702_MY2021_Rx" SG_ 1131 RearDiffSrvcRqd_B_Rq 1;
BA_ "U_CD542_MY2021_Rx" SG_ 1131 PtLatchActv_B_RqBcm 1;
BA_ "U_T6_MCA_MY2020_Rx" SG_ 1131 PtLatchActv_B_RqBcm 1;
BA_ "U_P702_MY2021_Rx" SG_ 1131 PtLatchActv_B_RqBcm 1;
BA_ "GenSigSendType" SG_ 1131 PtLatchActv_B_RqBcm 3;
BA_ "U_CD542_MY2021_Rx" SG_ 1136 ActvFrontSteMsgTxt_D_Rq_UB 1;
BA_ "U_T6_MCA_MY2020_Rx" SG_ 1136 ActvFrontSteMsgTxt_D_Rq_UB 1;
BA_ "U_P702_MY2021_Rx" SG_ 1136 ActvFrontSteMsgTxt_D_Rq_UB 1;
BA_ "U_CD542_MY2021_Rx" SG_ 1136 ActvFrontSteMsgTxt_D_Rq 1;
BA_ "U_T6_MCA_MY2020_Rx" SG_ 1136 ActvFrontSteMsgTxt_D_Rq 1;
BA_ "U_P702_MY2021_Rx" SG_ 1136 ActvFrontSteMsgTxt_D_Rq 1;
BA_ "U_P702_MY2021_Rx" SG_ 1136 GboxOil_Te_Actl_UB 1;
BA_ "U_CD542_MY2021_Rx" SG_ 1136 GboxOil_Te_Actl_UB 1;
BA_ "U_T6_MCA_MY2020_Rx" SG_ 1136 GboxOil_Te_Actl_UB 1;
BA_ "U_T6_MCA_MY2020_Rx" SG_ 1136 GboxOil_Te_Actl 1;
BA_ "U_P702_MY2021_Rx" SG_ 1136 GboxOil_Te_Actl 1;
BA_ "GenSigStartValue" SG_ 1136 GboxOil_Te_Actl 254;
BA_ "ContentDependant" SG_ 1136 GboxOil_Te_Actl 1;
BA_ "GenSigStartValueInteger" SG_ 1136 GboxOil_Te_Actl 254;
BA_ "U_T6_MCA_MY2020_Rx" SG_ 1136 EngOff_T_Actl_UB 1;
BA_ "U_P702_MY2021_Rx" SG_ 1136 EngOff_T_Actl_UB 1;
BA_ "U_T6_MCA_MY2020_Rx" SG_ 1136 EngOff_T_Actl 1;
BA_ "U_P702_MY2021_Rx" SG_ 1136 EngOff_T_Actl 1;
BA_ "GenSigStartValue" SG_ 1136 BrkLineLck_D_Stat 4;
BA_ "GenSigStartValueInteger" SG_ 1136 BrkLineLck_D_Stat 4;
BA_ "U_T6_MCA_MY2020_Rx" SG_ 1136 SnowPlowMde_B_Enbl 1;
BA_ "U_P702_MY2021_Rx" SG_ 1136 SnowPlowMde_B_Enbl 1;
BA_ "U_T6_MCA_MY2020_Rx" SG_ 1136 SnowPlowMde_B_Enbl_UB 1;
BA_ "U_P702_MY2021_Rx" SG_ 1136 SnowPlowMde_B_Enbl_UB 1;
BA_ "U_CD542_MY2021_Rx" SG_ 1106 TrlrSnsId_No_Actl 1;
BA_ "U_T6_MCA_MY2020_Rx" SG_ 1106 TrlrSnsId_No_Actl 1;
BA_ "U_CD542_MY2021_Rx" SG_ 1086 EngOil_P_Actl 1;
BA_ "U_P702_MY2021_Rx" SG_ 1086 EngOil_P_Actl 1;
BA_ "U_T6_MCA_MY2020_Rx" SG_ 1086 EngOil_P_Actl 1;
BA_ "U_CD542_MY2021_Rx" SG_ 1086 EngMnfld_P_Actl 1;
BA_ "U_T6_MCA_MY2020_Rx" SG_ 1086 EngMnfld_P_Actl 1;
BA_ "U_P702_MY2021_Rx" SG_ 1086 EngMnfld_P_Actl 1;
BA_ "GenSigStartValueInteger" SG_ 1086 EngMnfld_P_Actl 2068;
BA_ "U_T6_MCA_MY2020_Rx" SG_ 1086 EngIpcDsplyAfr_Rt_Actl 1;
BA_ "GenSigStartValue" SG_ 1086 EngIpcDsplyCht_Te_Actl 75;
BA_ "GenSigStartValueInteger" SG_ 1086 EngIpcDsplyCht_Te_Actl 75;
BA_ "GenSigStartValueInteger" SG_ 1086 AwdPtu_Te_Actl 50;
BA_ "U_T6_MCA_MY2020_Rx" SG_ 1086 FuelPumpPwr_B_Rq 1;
BA_ "U_T6_MCA_MY2020_Rx" SG_ 1086 BattULoChrg_U_Cmd 1;
BA_ "U_T6_MCA_MY2020_Rx" SG_ 1086 ElLoadCtl_D_Rq 1;
BA_ "ContentDependant" SG_ 1086 ElLoadCtl_D_Rq 1;
BA_ "WakeupSignal" SG_ 817 DrTgateOpen_B_Rq 1;
BA_ "WakeupSignal" SG_ 817 DrTgateExtSwMde_B_Stat 1;
BA_ "WakeupSignal" SG_ 817 Remote_Device_Feedback 1;
BA_ "U_CD542_MY2021_Rx" SG_ 817 Veh_Lock_Requestor 1;
BA_ "U_T6_MCA_MY2020_Rx" SG_ 817 Veh_Lock_Requestor 1;
BA_ "WakeupSignal" SG_ 817 Veh_Lock_Requestor 1;
BA_ "WakeupSignal" SG_ 817 R_Pwr_Sliding_Dr_Rqst 1;
BA_ "WakeupSignal" SG_ 817 Power_Liftgate_Rqst 1;
BA_ "U_CD542_MY2021_Rx" SG_ 817 Veh_Lock_EvNum 1;
BA_ "U_T6_MCA_MY2020_Rx" SG_ 817 Veh_Lock_EvNum 1;
BA_ "WakeupSignal" SG_ 817 Veh_Lock_EvNum 1;
BA_ "WakeupSignal" SG_ 817 Power_Decklid_Rqst 1;
BA_ "WakeupSignal" SG_ 817 L_Pwr_Sliding_Dr_Rqst 1;
BA_ "WakeupSignal" SG_ 817 Keyfob_Pad_Msg_Count 1;
BA_ "U_P702_MY2021_Rx" SG_ 817 Veh_Lock_Status 1;
BA_ "U_CD542_MY2021_Rx" SG_ 817 Veh_Lock_Status 1;
BA_ "U_T6_MCA_MY2020_Rx" SG_ 817 Veh_Lock_Status 1;
BA_ "GenSigStartValue" SG_ 817 Veh_Lock_Status 1;
BA_ "GenSigStartValueInteger" SG_ 817 Veh_Lock_Status 1;
BA_ "WakeupSignal" SG_ 817 Veh_Lock_Status 1;
BA_ "GenSigStartValue" SG_ 817 ChildLck_D_Dsply 1;
BA_ "GenSigStartValueInteger" SG_ 817 ChildLck_D_Dsply 1;
BA_ "WakeupSignal" SG_ 817 ChildLck_D_Dsply 1;
BA_ "U_CD542_MY2021_Rx" SG_ 817 RollCodeUnlock 1;
BA_ "U_T6_MCA_MY2020_Rx" SG_ 817 RollCodeUnlock 1;
BA_ "U_CD542_MY2021_Rx" SG_ 817 Lockmsgtxt_D_Rq 1;
BA_ "U_T6_MCA_MY2020_Rx" SG_ 817 Lockmsgtxt_D_Rq 1;
BA_ "U_P702_MY2021_Rx" SG_ 817 Lockmsgtxt_D_Rq 1;
BA_ "WakeupSignal" SG_ 817 Lockmsgtxt_D_Rq 1;
BA_ "U_T6_MCA_MY2020_Rx" SG_ 817 LockInhibit 1;
BA_ "WakeupSignal" SG_ 817 LockInhibit 1;
BA_ "U_CD542_MY2021_Rx" SG_ 611 AwdTerrMdeChng_D_Rdy 1;
BA_ "U_T6_MCA_MY2020_Rx" SG_ 611 AwdTerrMdeChng_D_Rdy 1;
BA_ "U_CD542_MY2021_Rx" SG_ 611 AwdTerrMde_D_Actl 1;
BA_ "U_T6_MCA_MY2020_Rx" SG_ 611 AwdTerrMde_D_Actl 1;
BA_ "U_CD542_MY2021_Rx" SG_ 611 AwdSys_D_Stat 1;
BA_ "U_T6_MCA_MY2020_Rx" SG_ 611 AwdSys_D_Stat 1;
BA_ "U_CD542_MY2021_Rx" SG_ 611 AwdStat_D_RqDsply 1;
BA_ "U_T6_MCA_MY2020_Rx" SG_ 611 AwdStat_D_RqDsply 1;
BA_ "U_P702_MY2021_Rx" SG_ 611 AwdStat_D_RqDsply 1;
BA_ "ContentDependant" SG_ 611 AwdStat_D_RqDsply 1;
BA_ "U_CD542_MY2021_Rx" SG_ 611 AwdLck_D_Stat 1;
BA_ "U_T6_MCA_MY2020_Rx" SG_ 611 AwdLck_D_Stat 1;
BA_ "U_P702_MY2021_Rx" SG_ 611 AwdLck_D_Stat 1;
BA_ "U_CD542_MY2021_Rx" SG_ 611 AwdSrvcRqd_B_Rq 1;
BA_ "U_T6_MCA_MY2020_Rx" SG_ 611 AwdSrvcRqd_B_Rq 1;
BA_ "U_P702_MY2021_Rx" SG_ 611 AwdSrvcRqd_B_Rq 1;
BA_ "ContentDependant" SG_ 611 AwdSrvcRqd_B_Rq 1;
BA_ "U_CD542_MY2021_Rx" SG_ 611 AwdLck_Tq_Rq 1;
BA_ "U_T6_MCA_MY2020_Rx" SG_ 611 AwdLck_Tq_Rq 1;
BA_ "U_P702_MY2021_Rx" SG_ 611 AwdLck_Tq_Rq 1;
BA_ "ContentDependant" SG_ 611 AwdLck_Tq_Rq 1;
BA_ "U_CD542_MY2021_Rx" SG_ 611 TrnAout_Tq_RqMx 1;
BA_ "U_T6_MCA_MY2020_Rx" SG_ 611 TrnAout_Tq_RqMx 1;
BA_ "GenSigStartValue" SG_ 611 TrnAout_Tq_RqMx 8191;
BA_ "GenSigStartValueInteger" SG_ 611 TrnAout_Tq_RqMx 8191;
BA_ "U_T6_MCA_MY2020_Rx" SG_ 611 AwdOffRoadMode_D_Stats 1;
BA_ "U_P702_MY2021_Rx" SG_ 611 AwdOffRoadMode_D_Stats 1;
BA_ "U_CD542_MY2021_Rx" SG_ 611 AwdOffRoadMode_D_Stats 1;
BA_ "U_CD542_MY2021_Rx" SG_ 611 AwdLoLamp_D_RqDsply 1;
BA_ "U_T6_MCA_MY2020_Rx" SG_ 611 AwdLoLamp_D_RqDsply 1;
BA_ "U_P702_MY2021_Rx" SG_ 611 AwdLoLamp_D_RqDsply 1;
BA_ "U_CD542_MY2021_Rx" SG_ 611 AwdHiLamp_D_RqDsply 1;
BA_ "U_T6_MCA_MY2020_Rx" SG_ 611 AwdHiLamp_D_RqDsply 1;
BA_ "U_P702_MY2021_Rx" SG_ 611 AwdHiLamp_D_RqDsply 1;
BA_ "U_CD542_MY2021_Rx" SG_ 611 AwdAutoLamp_D_RqDsply 1;
BA_ "U_T6_MCA_MY2020_Rx" SG_ 611 AwdAutoLamp_D_RqDsply 1;
BA_ "U_P702_MY2021_Rx" SG_ 611 AwdAutoLamp_D_RqDsply 1;
BA_ "U_CD542_MY2021_Rx" SG_ 611 Awd2wdLamp_D_RqDsply 1;
BA_ "U_T6_MCA_MY2020_Rx" SG_ 611 Awd2wdLamp_D_RqDsply 1;
BA_ "U_P702_MY2021_Rx" SG_ 611 Awd2wdLamp_D_RqDsply 1;
BA_ "U_CD542_MY2021_Rx" SG_ 611 AwdRnge_D_Actl 1;
BA_ "U_T6_MCA_MY2020_Rx" SG_ 611 AwdRnge_D_Actl 1;
BA_ "U_P702_MY2021_Rx" SG_ 611 AwdRnge_D_Actl 1;
BA_ "GenSigStartValue" SG_ 611 AwdRnge_D_Actl 7;
BA_ "GenSigStartValueInteger" SG_ 611 AwdRnge_D_Actl 7;
BA_ "U_CD542_MY2021_Rx" SG_ 611 NtrlTowAvail_B_Stat 1;
BA_ "U_T6_MCA_MY2020_Rx" SG_ 611 NtrlTowAvail_B_Stat 1;
BA_ "U_P702_MY2021_Rx" SG_ 611 NtrlTowAvail_B_Stat 1;
BA_ "U_CD542_MY2021_Rx" SG_ 611 AwdDrvMde_D_Stat 1;
BA_ "U_T6_MCA_MY2020_Rx" SG_ 611 AwdDrvMde_D_Stat 1;
VAL_ 722 VRM_ComShuffleTrack_St 0 "Invalid" 1 "CommandNotIssued" 2 "On" 3 "Off" ;
VAL_ 722 VRM_ComCompression_St 0 "Invalid" 1 "CommandNotIssued" 2 "On" 3 "Off" ;
VAL_ 722 VRM_ComStFreqMode_St 0 "Invalid" 1 "CommandNotIssued" 2 "Fm" 3 "Am" 4 "Reserved" ;
VAL_ 722 VRM_ComAutostore_St 0 "Invalid" 1 "CommandNotIssued" 2 "PerfomAutostore" ;
VAL_ 722 VRM_ComBand_St 0 "Invalid" 1 "CommandNotIssued" 2 "Fm1" 3 "Fm2" 4 "Fmas" 5 "Am" 6 "Amas" 7 "AutostoreMode" ;
VAL_ 722 VRM_TMCVoice 0 "Invalid" 1 "CommandNotIssued" 2 "On" 3 "Off" ;
VAL_ 722 VRM_NewSMS 3 "UnreadSMSMessagesAvailable" 0 "Invalid" 1 "NewSmsAvailable" 2 "NoNewSmsAvailable" ;
VAL_ 722 VRM_ComRSEDisplay_St 0 "Invalid" 1 "CommandNotIssued" 2 "On" 3 "Off" ;
VAL_ 722 VRM_ComPresetCall_St 0 "Invalid" 1 "CommandNotIssued" 2 "Prescall1" 3 "Prescall2" 4 "Prescall3" 5 "Prescall4" 6 "Prescall5" 7 "Prescall6" ;
VAL_ 722 VRM_ComTape_St 0 "Invalid" 1 "CommandNotIssued" 2 "Play" 3 "Rewind" 4 "Forward" 5 "ChangeSide" 6 "AutosearchForward" 7 "AutosearchBackward" ;
VAL_ 722 VRM_ComShuffleDiscs_St 0 "Invalid" 1 "CommandNotIssued" 2 "On" 3 "Off" ;
VAL_ 722 VRM_ComDolbyNR_St 0 "Invalid" 1 "CommandNotIssued" 2 "On" 3 "Off" ;
VAL_ 722 VRM_ComSourceSelect_St 7 "BTAudio" 6 "Con" 0 "Invalid" 1 "CommandNotIssued" 2 "Radio" 3 "SDCard" 4 "SingleDisc" 5 "MultiDisc" ;
VAL_ 722 VRM_ComRouteStrategy_St 0 "Invalid" 1 "CommandNotIssued" 2 "Shortesttime" 3 "Shortestdistance" 4 "Majorroadsavoid" 5 "Majorroadsprefer" 6 "TollRoadsaviod" 7 "TollRoadsprefer" 8 "Ferriesavoid" 9 "Ferriesprefer" ;
VAL_ 721 VRM_BTDefaultPhone_St 0 "Invalid" 1 "PhoneIndex1" 2 "PhoneIndex2" 3 "PhoneIndex3" 4 "PhoneIndex4" 5 "PhoneIndex5" 6 "PhoneIndex6" 7 "CradlePhone" 8 "NoPhone" ;
VAL_ 721 VRM_DetourUnit_st 0 "Invalid" 1 "Miles" 2 "Kilometer" 3 "Nounitdefined" ;
VAL_ 721 VRM_Zoom_Option_St 0 "Invalid" 1 "AbsoluteValue" 2 "InrelativeValue" 3 "OutrelativeValue" ;
VAL_ 721 VRM_ComBTDTMFTone_St 14 "Dtmfplus" 0 "Invalid" 1 "CommandNotIssued" 2 "Dtmf0" 3 "Dtmf1" 4 "Dtmf2" 5 "Dtmf3" 6 "Dtmf4" 7 "Dtmf5" 8 "Dtmf6" 9 "Dtmf7" 10 "Dtmf8" 11 "Dtmf9" 12 "Dtmfstar" 13 "Dtmfcross" ;
VAL_ 721 VRM_SuggestedRoute_St 0 "Invalid" 1 "CommandNotIssued" 2 "Accept" 3 "Reject" ;
VAL_ 721 VRM_ComDelWaypoint_St 0 "Invalid" 1 "CommandNotIssued" 2 "DeleteNextWayptDestination" ;
VAL_ 721 VRM_ComSelectDisc_St 0 "Invalid" 1 "CommandNotIssued" 2 "Disc1" 3 "Disc2" 4 "Disc3" 5 "Disc4" 6 "Disc5" 7 "Disc6" ;
VAL_ 721 VRM_ComTelService_St 0 "Invalid" 1 "CommandNotIssued" 2 "InformationCall" 3 "TelephonyCall" 4 "RedialLastIncoming" ;
VAL_ 721 VRM_ComDestHome_St 0 "Invalid" 1 "CommandNotIssued" 2 "SetDestinationHome" ;
VAL_ 721 VRM_ComShowNavInfo_St 0 "Invalid" 1 "CommandNotIssued" 2 "CurrentPos" 3 "Destination" 4 "CompleteRoute" 5 "NorthDirectionToTop" 6 "CarDirectionToTop" 7 "TurnList" ;
VAL_ 721 VRM_VoiceRecStatus_St 0 "Invalid" 1 "Idle" 2 "Listening" 3 "Reserved" 4 "CommandNotAllowed" ;
VAL_ 721 VRM_ComSelTrackSource_St 0 "Invalid" 1 "CommandNotIssued" 2 "Cd" 3 "CdChanger" ;
VAL_ 721 VRM_ComDetour_St 0 "Invalid" 1 "CommandNotIssued" 2 "Detour1" 3 "Detour2" 4 "Detour3" 5 "Detour4" 6 "Detour5" 7 "Detour10" 8 "Detour15" 9 "Detour20" 10 "Detour25" 11 "Detour50" 12 "Detour100" ;
VAL_ 721 VRM_ComDisplay_St 0 "Invalid" 1 "CommandNotIssued" 2 "DisplayOn" 3 "DisplayOff" 4 "Day" 5 "Night" 6 "Auto" 7 "Twilight" ;
VAL_ 721 VRM_ComDynamicGuidande_St 0 "Invalid" 1 "CommandNotIssued" 2 "On" 3 "Off" ;
VAL_ 721 VRM_ComZoom_St 0 "Invalid" 1 "CommandNotIssued" 2 "Level1" 3 "Level2" 4 "Level3" 5 "Level4" 6 "Level5" 7 "Level6" 8 "Level7" 9 "Level8" 10 "Level9" 11 "Level10" 12 "Level11" 13 "Level12" 14 "Level13" ;
VAL_ 721 VRM_ComCallControl_St 0 "Invalid" 1 "CommandNotIssued" 2 "Pickup" 3 "Reject" 4 "EndOngoingCall" ;
VAL_ 721 VRM_ComGuidance_St 0 "Invalid" 1 "CommandNotIssued" 2 "VoiceGuidanceOn" 3 "VoiceGuidanceOff" 4 "CancelGuidance" 5 "RepeatLastVoiceGuidance" ;
VAL_ 721 VRM_ComTrafficInfDsp_St 0 "Invalid" 1 "CommandNotIssued" 2 "ShowTrafficInfoOnDisplay" 3 "HideTrafficInfoOnDisplay" ;
VAL_ 720 VRM_PhMicrophoneMute_St 3 "Reserved" 2 "MicrophoneIsUnmuted" 1 "MicrophoneIsMuted" 0 "Invalid" ;
VAL_ 720 Aioc_ExtSrcOutpMode_St 8 "NotAllocated" 4 "AllocatedBtAudio" 3 "AllocatedBtNavigation" 2 "AllocatedBtPhone" 1 "AllocatedVr" 0 "Invalid" 7 "AllocatedAUX3" 6 "AllocatediPod" 5 "AllocatedUSB" ;
VAL_ 720 VRM_BTPhoneSts_St 16 "Connected_Call_on_hold" 15 "Conference_OtherCallOnHold" 0 "Invalid" 1 "Idle" 2 "Dialing" 3 "Connected" 4 "CradlephNotReady" 5 "NumUnobtainable" 6 "IncomCall" 7 "NoLinkToBt" 8 "InitBtCon" 9 "PhoneBusy" 10 "PhoneVr" 11 "NotSupported" 12 "BtPhPriv" 13 "ConfCall" 14 "Conference_2ndIncCall" ;
VAL_ 720 VRM_SubscribeStatus_St 0 "Invalid" 1 "OnSubscribingInfo" 2 "OffNotSubscribingInfo" ;
VAL_ 720 VRM_BlutoothStatus_St 0 "Invalid" 1 "On" 2 "Off" ;
VAL_ 720 VRM_BondRequest_St 0 "Invalid" 1 "BondRequestExist" 2 "NoBondRequestExist" ;
VAL_ 720 VRM_VRMMonoOutMode_St 0 "Invalid" 1 "AllocatedVr" 2 "AllocatedBt" 3 "NotAllocated" ;
VAL_ 720 VRM_BTNetworkStatus_St 0 "Invalid" 1 "NoNetwork" 2 "InNetwork" 3 "Roaming" 4 "NoLinkToBtPhone" 5 "NotSupportedByBtPhone" ;
VAL_ 720 VRM_BTSignalStrength_St 0 "Invalid" 1 "SignalStrength0" 2 "SignalStrength1" 3 "SignalStrength2" 4 "SignalStrength3" 5 "SignalStrength4" 6 "SignalStrength5" 7 "NoLinkToBtPhone" 8 "NotSupportedByBtPhone" ;
VAL_ 720 VRM_BTBatteryLevel_St 0 "Invalid" 1 "Level0" 2 "Level1" 3 "Level2" 4 "Level3" 5 "Level4" 6 "Level5" 7 "NoLinkToBtPhone" 8 "NotSupportedByBtPhone" ;
VAL_ 470 VRM_BTIncomingCall_Rsp 0 "Inactive" 1 "Accepted" 2 "Declined" 3 "Failed" ;
VAL_ 470 VRM_BTEndTelService_Rsp 3 "Error" 0 "Inactive" 1 "IntermediateResult" 2 "FinalResult" ;
VAL_ 758 SDARS_OpMode_St 7 "FastRewindSpeed2" 6 "FastRewindSpeed1" 5 "FastForwardSpeed2" 4 "FastForwardSpeed1" 3 "Pause" 2 "Play" 1 "Stop" 0 "Invalid" ;
VAL_ 758 SDARS_Factory_Reset_St 1 "FactorySettingsRestored" 0 "Invalid" ;
VAL_ 760 SDARS_Alert_Status 0 "Invalid" 2 "Disabled" 1 "Enabled" ;
VAL_ 760 SDARS_Channel_Lock 0 "Invalid" 2 "Unlocked" 1 "Locked" ;
VAL_ 523 WaterInFuel_B_Falt_UB 1 "Fresh_data" 0 "Unchanged_data" ;
VAL_ 523 WaterInFuel_B_Falt 1 "Fault" 0 "No_Fault" ;
VAL_ 523 UreaMxAdd_L2_Actl_UB 1 "Fresh_data" 0 "Unchanged_data" ;
VAL_ 523 VehUreaRnge3_L_DsplyMx_UB 1 "Fresh_data" 0 "Unchanged_data" ;
VAL_ 523 UreaMnAdd_L2_Actl_UB 1 "Fresh_data" 0 "Unchanged_data" ;
VAL_ 523 UreaMnAdd_L2_Actl 255 "Faulty" ;
VAL_ 523 UreaMxAdd_L2_Actl 511 "Faulty" ;
VAL_ 942 ApaDrvRq2MsgTxt_D_Rq 15 "NotUsed_7" 14 "NotUsed_6" 13 "NotUsed_5" 12 "NotUsed_4" 11 "NotUsed_3" 10 "NotUsed_2" 9 "NotUsed_1" 8 "CloseDoor" 7 "TakeControl" 6 "ReleaseEpb" 5 "ReleaseSteering" 4 "ReleaseBrake" 3 "DriveBackward" 2 "DriveForward" 1 "Stop" 0 "NoRequest" ;
VAL_ 942 ApaDrvRq1MsgTxt_D_Rq 7 "NotUsed" 6 "ExitVehicle" 5 "PressApaButton" 4 "ShiftToP" 3 "ShiftToN" 2 "ShiftToD" 1 "ShiftToR" 0 "NoRequest" ;
VAL_ 942 ApaSys_D2_Stat 15 "NotUsed_5" 14 "NotUsed_4" 13 "NotUsed_3" 12 "NotUsed_2" 11 "NotUsed_1" 10 "NoSideSelectable" 9 "RightSideSelectable" 8 "LeftSideSelectable" 7 "BothSidesSelectable" 6 "Faulty" 5 "Finished" 4 "Cancelled" 3 "NotAvailable" 2 "Overspeed" 1 "Pause" 0 "NormalOperation" ;
VAL_ 942 ApaSlotTrgt_D_Stat 15 "NotUsed_7" 14 "NotUsed_6" 13 "NotUsed_5" 12 "NotUsed_4" 11 "NotUsed_3" 10 "NotUsed_2" 9 "NotUsed_1" 8 "Front" 7 "Rear" 6 "Right3" 5 "Right2" 4 "Right1" 3 "Left3" 2 "Left2" 1 "Left1" 0 "None" ;
VAL_ 942 ApaSlotOption_B_Avail 1 "Available" 0 "NotAvailable" ;
VAL_ 942 ApaSlotAlrtSet_B_Stat 1 "Enable" 0 "Disable" ;
VAL_ 942 ApaSlotAlrt_B_Rq 1 "True" 0 "False" ;
VAL_ 942 ApaRmtFeatSel_B_Avail 1 "Available" 0 "NotAvailable" ;
VAL_ 942 ApaParkOutSel_B_Avail 1 "Available" 0 "NotAvailable" ;
VAL_ 942 ApaParkInSel_B_Avail 1 "Available" 0 "NotAvailable" ;
VAL_ 942 ApaMsgTxt_D2_Stat 15 "ReducedFunction" 14 "TrailerFeatureNotAvailable" 13 "AcceleratorPedalInactive" 12 "SensorsBlocked" 11 "TrailerAttached" 10 "TcsDeactivated" 9 "WheelSlip" 8 "HighInclination" 7 "DoorOpen" 6 "SteeringInteraction" 5 "WrongDirection" 4 "SpeedLimitExceeded" 3 "BrakeEvent" 2 "ObstacleInPath" 1 "WaitForSteering" 0 "None" ;
VAL_ 942 ApaDynmcSlot_B_Stat 1 "On" 0 "Off" ;
VAL_ 942 ApaDisplayMode_D_Stat 3 "NotUsed" 2 "FullScreen" 1 "Menu" 0 "Off" ;
VAL_ 942 ApaControlMode_D_Stat 1 "Active" 0 "Inactive" ;
VAL_ 942 PrkAidAcsyRear_D_Stat 3 "NotUsed" 2 "On" 1 "Off" 0 "Null" ;
VAL_ 942 PrkAidAcsyFront_D_Stat 3 "NotUsed" 2 "On" 1 "Off" 0 "Null" ;
VAL_ 942 PrkAidDrvDir_D_Stat 7 "NotUsed_2" 6 "NotUsed_1" 5 "BackwardNegative" 4 "ForwardNegative" 3 "BackwardPositive" 2 "ForwardPositive" 1 "NoMotion" 0 "DirectionNotKnown" ;
VAL_ 634 EngAirFiltMsgTxt_D_Rq_UB 1 "Fresh_data" 0 "Unchanged_data" ;
VAL_ 634 EngAirFiltMsgTxt_D_Rq 7 "NotUsed_2" 6 "NotUsed_1" 5 "EngineAirFilterMonitorFalt" 4 "ResetComplete" 3 "Clogged" 2 "ReplaceNow" 1 "ReplaceSoon" 0 "NoMessage" ;
VAL_ 634 AutoHoldSwMde_B_Ind_UB 1 "Fresh_data" 0 "Unchanged_data" ;
VAL_ 634 AutoHoldSwMde_B_Ind 1 "On" 0 "Off" ;
VAL_ 634 Ccd_B_Falt_UB 1 "Fresh_data" 0 "Unchanged_data" ;
VAL_ 634 Ccd_B_Falt 1 "Yes" 0 "No" ;
VAL_ 634 RearDiffLckLamp_D_Rq3_UB 1 "Fresh_data" 0 "Unchanged_data" ;
VAL_ 634 AwdLckLamp_D_Rq_UB 1 "Fresh_data" 0 "Unchanged_data" ;
VAL_ 634 RearDiffLckLamp_D_Rq3 3 "Triggered" 2 "Flash" 1 "On" 0 "Off" ;
VAL_ 634 AwdLckLamp_D_Rq 3 "Triggered" 2 "Flash" 1 "On" 0 "Off" ;
VAL_ 634 AutoTowAllw_D_StatMnu_UB 1 "Fresh_data" 0 "Unchanged_data" ;
VAL_ 634 AutoTowAllw_D_StatMnu 3 "TowHaulCommandedOn" 2 "AutoTowHaulEnabled" 1 "AutoTowHaulDisabled" 0 "NoSelection" ;
VAL_ 634 AutoTowActv_B_Stat 1 "Yes" 0 "No" ;
VAL_ 634 AutoTowActv_B_Stat_UB 1 "Fresh_data" 0 "Unchanged_data" ;
VAL_ 634 LdwChime_B_Rq_UB 1 "Fresh_data" 0 "Unchanged_data" ;
VAL_ 634 HdcOn_B_Ind 1 "On" 0 "Off" ;
VAL_ 634 HdcOn_B_Ind_UB 1 "Fresh_data" 0 "Unchanged_data" ;
VAL_ 634 SuspVLimMsgTxt_B_Rq_UB 1 "Fresh_data" 0 "Unchanged_data" ;
VAL_ 634 SuspVlimMsgTxt_B_Rq 1 "Yes" 0 "No" ;
VAL_ 634 EngExhMdeQuiet_D2_Stat_UB 1 "Fresh_data" 0 "Unchanged_data" ;
VAL_ 634 EngExhMdeQuiet_D2_Stat 7 "Faulty" 6 "NotUsed_2" 5 "NotUsed_1" 4 "Track" 3 "Sport" 2 "Normal" 1 "Stealth" 0 "Null" ;
VAL_ 634 ChrgCrdLck_D_Falt_UB 1 "Fresh_data" 0 "Unchanged_data" ;
VAL_ 634 LdwChime_B_Rq 1 "On" 0 "Off" ;
VAL_ 634 ChrgCrdLck_D_Falt 3 "NotUsed" 2 "HardwareFault" 1 "CsiFault" 0 "NoFault" ;
VAL_ 1088 HvacPrecondRecirc_D_Rq 3 "Last_User_Setting" 2 "Auto" 1 "Recirc" 0 "Outside" ;
VAL_ 1088 HvacPrecondMode2_D_Rq 15 "NotUsed4" 14 "NotUsed3" 13 "NotUsed2" 12 "NotUsed1" 11 "Last_User_Settings" 10 "Auto" 9 "Max_Defrost" 8 "Windshield_Panel_Floor" 7 "Windshield_Panel" 6 "Windshield" 5 "Windshield_Floor" 4 "Floor" 3 "Panel_Floor" 2 "Panel" 1 "MAX_AC" 0 "Off" ;
VAL_ 1088 HvacPrecondBlwr2_D_Rq 15 "NotUsed6" 14 "NotUsed5" 13 "NotUsed4" 12 "NotUsed3" 11 "NotUsed2" 10 "NotUsed1" 9 "Last_User_Setting" 8 "Auto" 7 "Speed7" 6 "Speed6" 5 "Speed5" 4 "Speed4" 3 "Speed3" 2 "Speed2" 1 "Speed1" 0 "Off" ;
VAL_ 1088 HvacPrecondAC_D_Rq 3 "Last_User_Setting" 2 "Auto" 1 "On" 0 "Off" ;
VAL_ 1088 BattChrgInhbt_D_Rq 3 "MaintainTargetSoc" 2 "NotUsed" 1 "InhibitChargingThermal" 0 "Enable_Charging" ;
VAL_ 1088 ChrgStat_D2_Dsply 15 "ChargeStopCommanded" 14 "ChargeStartCommanded" 13 "ChargeTargetReached" 12 "DriveConditioning" 11 "CabinPreconditioning" 10 "ChargingSystemMaintain" 9 "ChargingInductive" 8 "ChargingDCFastCharge" 7 "ChargingAC" 6 "ChargeScheduled" 5 "EvsePaused" 4 "EvseNotDetected" 3 "EvseNotCompatible" 2 "FaultOutsideCar" 1 "FaultInsideCar" 0 "NotReady" ;
VAL_ 1088 ChrgTMatch_B_Stat 1 "True" 0 "False" ;
VAL_ 1088 BattDcChrgRms_I_Lim 32767 "Faulty" 32766 "NoDataExists" ;
VAL_ 761 SDARS_Seek_Scan_St 1 "NoChannelsAvailable" 0 "Invalid" ;
VAL_ 761 SDARS_Invalid_Chan_St 0 "Invalid" 2 "Active" 1 "Inactive" ;
VAL_ 761 SDARS_UnSubscrb_Chan_St 0 "Invalid" 2 "Active" 1 "Inactive" ;
VAL_ 761 SDARS_Loss_Ant_St 0 "Invalid" 2 "Active" 1 "Inactive" ;
VAL_ 761 SDARS_UnSubscrb_St 0 "Invalid" 2 "Active" 1 "Inactive" ;
VAL_ 761 SDARS_Subscription_St 0 "Invalid" 2 "Active" 1 "Inactive" ;
VAL_ 761 SDARS_GCI_Update_St 0 "Invalid" 2 "Active" 1 "Inactive" ;
VAL_ 761 SDARS_Firmware_Updat_St 0 "Invalid" 2 "Active" 1 "Inactive" ;
VAL_ 761 SDARS_Antenna_Err_St 0 "Invalid" 2 "Active" 1 "Inactive" ;
VAL_ 761 SDARS_Receive_Err_St 0 "Invalid" 2 "Active" 1 "Inactive" ;
VAL_ 761 SDARS_Error_Conf_St 0 "Invalid" 2 "SDARS_OFF" 1 "SDARS_ON" ;
VAL_ 750 LoclFuelEffUnit_D_Stat 3 "MetrickmL" 2 "MetricL100km" 1 "Imperial" 0 "Null" ;
VAL_ 750 RoadsideAsstAvail_D_St 3 "AvailableFord" 2 "AvailableLincoln" 1 "NotAvailable" 0 "Null" ;
VAL_ 750 EmbedNavActive_D_Stat 3 "NotUsed" 2 "Active" 1 "Inactive" 0 "Null" ;
VAL_ 750 UnitOfLength_St 3 "miles_yards" 2 "miles_feets" 1 "kilometers_meters" 0 "Invalid" ;
VAL_ 750 RouteActive_St 1 "Active" 0 "Inactive" ;
VAL_ 750 CancelCurrWaypt_St 1 "Cancelled" 0 "Inactive" ;
VAL_ 750 Nav_RemainTTDestDays_St 14 "Exceeding13days" ;
VAL_ 750 WaypointsActive_St 3 "Max_Waypoints_Active" 2 "Waypoints_Active" 1 "Waypoints_Inactive" 0 "Invalid" ;
VAL_ 750 Nav_DistanToDestUnit_St 3 "Yards_yd" 2 "Miles_mi" 1 "Meters_m" 0 "Kilometers_km" ;
VAL_ 750 NavError_Waypoint_St 2 "Navigation_Fault" 1 "No_Error" 0 "Invalid" ;
VAL_ 725 InfotainmentAudio_St 3 "NotUsed" 2 "ErrorState_NoAudio" 1 "NormalOperation" 0 "Null" ;
VAL_ 725 ACU_CompLogic_St 0 "Invalid" 1 "Off" 2 "On" ;
VAL_ 725 ACU_RadioError_St 0 "Invalid" 1 "NoError" 2 "PiNotFound" 3 "PtyNotFound" ;
VAL_ 725 ACU_HardwareError_St 0 "Invalid" 1 "NoError" 2 "EepromReadError" 3 "KeycodeLocked" 4 "KeycodeLockedForever" 5 "CommunicationError" 6 "OverTemperature" 7 "FocusError" ;
VAL_ 725 ACU_CurrentRadioBand_St 6 "Fm3" 0 "Invalid" 1 "Fm1" 2 "Fm2" 3 "FmAst" 4 "Am" 5 "AmAst" ;
VAL_ 725 ACU_AFMode_St 0 "Invalid" 1 "AfOn" 2 "AfOff" 3 "Auto" ;
VAL_ 1074 PwLftgtIntSw_B_Stat_UB 1 "Fresh_data" 0 "Unchanged_data" ;
VAL_ 1074 PwLftgtIntSw_B_Stat 1 "Pressed" 0 "Null" ;
VAL_ 1074 E_Frt_Btn_Status_1st_UB 1 "Fresh_data" 0 "Unchanged_data" ;
VAL_ 1074 E_Frt_Btn_Status_2nd_UB 1 "Fresh_data" 0 "Unchanged_data" ;
VAL_ 1074 E_Frt_Btn_Status_2nd 63 "NotUsed_10" 62 "NotUsed_9" 61 "NotUsed_8" 60 "NotUsed_7" 59 "NotUsed_6" 58 "NotUsed_5" 57 "NotUsed_4" 56 "NotUsed_3" 55 "NotUsed_2" 54 "NotUsed_1" 53 "RHS_Cld_Seat3_Pressed" 52 "RHS_Cld_Seat2_Pressed" 51 "RHS_Cld_Seat1_Pressed" 50 "LHS_Cld_Seat3_Pressed" 49 "LHS_Cld_Seat2_Pressed" 48 "LHS_Cld_Seat1_Pressed" 47 "RHS_Auto_Seat_Pressed" 46 "RHS_Htd_Seat3_Pressed" 45 "RHS_Htd_Seat2_Pressed" 44 "RHS_Htd_Seat1_Pressed" 43 "RHS_Seat_Off_Pressed" 42 "LHS_Auto_Seat_Pressed" 41 "LHS_Htd_Seat3_Pressed" 40 "LHS_Htd_Seat2_Pressed" 39 "LHS_Htd_Seat1_Pressed" 38 "LHS_Seat_Off_Pressed" 37 "DrvrFcsdMde_Pressed" 36 "MdeMnu_Pressed" 35 "AAR_Pressed" 34 "Heat_Pressed" 33 "RearMnu_Pressed" 32 "FrontMnu_Pressed" 31 "Defrost_Pressed" 30 "Htg_Strg_Whl_Pressed" 29 "RHS_Cld_Seat_Pressed" 28 "LHS_Cld_Seat_Pressed" 27 "RHS_Htd_Seat_Pressed" 26 "LHS_Htd_Seat_Pressed" 25 "Max_Defrost_Pressed" 24 "My_Temp_Pressed" 23 "Front_Power_Pressed" 22 "Rear_Defrost_Pressed" 21 "Pnl_Flr_Ws_Pressed" 20 "Pnl_Ws_Pressed" 19 "Windscreen_Pressed" 18 "Htd_Frt_Wsh_Pressed" 17 "Auto_Recirc_Pressed" 16 "Outside_Pressed" 15 "Recirc_Pressed" 14 "Max_AC_Pressed" 13 "Auto_Pressed" 12 "Blwr_Dec_Pressed" 11 "Blwr_Inc_Pressed" 10 "RHS_Temp_Dec_Pressed" 9 "RHS_Temp_Inc_Pressed" 8 "LHS_Temp_Dec_Pressed" 7 "LHS_Temp_Inc_Pressed" 6 "Dual_Pressed" 5 "AC_Pressed" 4 "Floor_Ws_Pressed" 3 "Floor_Pressed" 2 "Panel_Floor_Pressed" 1 "Panel_Pressed" 0 "None_Pressed" ;
VAL_ 1074 E_Frt_Btn_Status_1st 63 "NotUsed_10" 62 "NotUsed_9" 61 "NotUsed_8" 60 "NotUsed_7" 59 "NotUsed_6" 58 "NotUsed_5" 57 "NotUsed_4" 56 "NotUsed_3" 55 "NotUsed_2" 54 "NotUsed_1" 53 "RHS_Cld_Seat3_Pressed" 52 "RHS_Cld_Seat2_Pressed" 51 "RHS_Cld_Seat1_Pressed" 50 "LHS_Cld_Seat3_Pressed" 49 "LHS_Cld_Seat2_Pressed" 48 "LHS_Cld_Seat1_Pressed" 47 "RHS_Auto_Seat_Pressed" 46 "RHS_Htd_Seat3_Pressed" 45 "RHS_Htd_Seat2_Pressed" 44 "RHS_Htd_Seat1_Pressed" 43 "RHS_Seat_Off_Pressed" 42 "LHS_Auto_Seat_Pressed" 41 "LHS_Htd_Seat3_Pressed" 40 "LHS_Htd_Seat2_Pressed" 39 "LHS_Htd_Seat1_Pressed" 38 "LHS_Seat_Off_Pressed" 37 "DrvrFcsdMde_Pressed" 36 "MdeMnu_Pressed" 35 "AAR_Pressed" 34 "Heat_Pressed" 33 "RearMnu_Pressed" 32 "FrontMnu_Pressed" 31 "Defrost_Pressed" 30 "Htg_Strg_Whl_Pressed" 29 "RHS_Cld_Seat_Pressed" 28 "LHS_Cld_Seat_Pressed" 27 "RHS_Htd_Seat_Pressed" 26 "LHS_Htd_Seat_Pressed" 25 "Max_Defrost_Pressed" 24 "My_Temp_Pressed" 23 "Front_Power_Pressed" 22 "Rear_Defrost_Pressed" 21 "Pnl_Flr_Ws_Pressed" 20 "Pnl_Ws_Pressed" 19 "Windscreen_Pressed" 18 "Htd_Frt_Wsh_Pressed" 17 "Auto_Recirc_Pressed" 16 "Outside_Pressed" 15 "Recirc_Pressed" 14 "Max_AC_Pressed" 13 "Auto_Pressed" 12 "Blwr_Dec_Pressed" 11 "Blwr_Inc_Pressed" 10 "RHS_Temp_Dec_Pressed" 9 "RHS_Temp_Inc_Pressed" 8 "LHS_Temp_Dec_Pressed" 7 "LHS_Temp_Inc_Pressed" 6 "Dual_Pressed" 5 "AC_Pressed" 4 "Floor_Ws_Pressed" 3 "Floor_Pressed" 2 "Panel_Floor_Pressed" 1 "Panel_Pressed" 0 "None_Pressed" ;
VAL_ 1074 DrLatchRrMsgTxt_D_Rq_UB 1 "Fresh_data" 0 "Unchanged_data" ;
VAL_ 1074 DrLatchRrMsgTxt_D_Rq 7 "Message7" 6 "Message6" 5 "Message5" 4 "Message4" 3 "Message3" 2 "Message2" 1 "Message1" 0 "NoMessage" ;
VAL_ 1074 DrLatchRlMsgTxt_D_Rq_UB 1 "Fresh_data" 0 "Unchanged_data" ;
VAL_ 1074 DrLatchRlMsgTxt_D_Rq 7 "Message7" 6 "Message6" 5 "Message5" 4 "Message4" 3 "Message3" 2 "Message2" 1 "Message1" 0 "NoMessage" ;
VAL_ 1074 DrLatchFrMsgTxt_D_Rq_UB 1 "Fresh_data" 0 "Unchanged_data" ;
VAL_ 1074 DrLatchFrMsgTxt_D_Rq 7 "Message7" 6 "Message6" 5 "Message5" 4 "Message4" 3 "Message3" 2 "Message2" 1 "Message1" 0 "NoMessage" ;
VAL_ 1074 DrLatchFlMsgTxt_D_Rq_UB 1 "Fresh_data" 0 "Unchanged_data" ;
VAL_ 1074 DrLatchFlMsgTxt_D_Rq 7 "Message7" 6 "Message6" 5 "Message5" 4 "Message4" 3 "Message3" 2 "Message2" 1 "Message1" 0 "NoMessage" ;
VAL_ 1074 TrlrTireThresh_D_Stat_UB 1 "Fresh_data" 0 "Unchanged_data" ;
VAL_ 1074 TrlrTireSys_D_Stat_UB 1 "Fresh_data" 0 "Unchanged_data" ;
VAL_ 1074 TrlrTireSys_D_Stat 15 "NotUsed" 14 "TiresNotTrained" 13 "TrainingComplete" 12 "TrainLMTire" 11 "TrainLRTire" 10 "TrainRMTire" 9 "TrainRRTire" 8 "TrainRFTire" 7 "TrainLFTire" 6 "RequestPressureThresh" 5 "RequestTireCount" 4 "SystemActive" 3 "TireLow" 2 "SensorFault" 1 "System Fault" 0 "SystemUnknown" ;
VAL_ 1074 TrlrTireCnt_D_Stat_UB 1 "Fresh_data" 0 "Unchanged_data" ;
VAL_ 1074 TrlrTireCnt_D_Stat 7 "Faulty" 6 "NotUsed_3" 5 "NotUsed_2" 4 "NotUsed_1" 3 "Six_Tire" 2 "Four_Tire" 1 "Two_Tire" 0 "Unconfigured" ;
VAL_ 1074 BrkMdeInhbt_B_RqDsply_UB 1 "Fresh_data" 0 "Unchanged_data" ;
VAL_ 1074 BrkMdeInhbt_B_RqDsply 1 "Yes" 0 "No" ;
VAL_ 1014 WrlssAcsyChrg_Pc_Actl 127 "Faulty" 126 "NoDataExists" ;
VAL_ 1014 WrlssAcsyChrgr_D_Stat 7 "NotUsed" 6 "Misalignment" 5 "Overheat" 4 "MetalObjectDetected" 3 "ChargingComplete" 2 "ChargingInProgress" 1 "ChargingNotInProgress" 0 "Null" ;
VAL_ 548 DSP_AHU_ChmTstTone_Rq 1 "Active" 0 "Inactive" ;
VAL_ 548 DSP_ChimeChanState_St 7 "Reserved4" 6 "Reserved3" 5 "Reserved2" 4 "Reserved" 3 "Busy" 2 "Ready" 1 "Muted" 0 "Invalid" ;
VAL_ 548 DSP_Chime2_Not_Recgnizd 0 "Inactive" 1 "Chime_Not_Recognized" ;
VAL_ 548 DSP_Chime_Not_Recgnizd 0 "Inactive" 1 "Chime_Not_Recognized" ;
VAL_ 548 DSP_Alert_Channel3 3 "Reserved" 2 "Muted" 1 "Initialized_for_Prompts" 0 "Inactive" ;
VAL_ 548 DSP_Alert_Channel2 3 "Initialized_for_chimes" 2 "Muted" 1 "Reserved" 0 "Inactive" ;
VAL_ 548 DSP_Alert_Channel1 3 "Initialized_for_chimes" 2 "Muted" 1 "Reserved" 0 "Inactive" ;
VAL_ 548 DSP_Chimes_Supported 3 "Not_Used" 2 "Not_Supported" 1 "Supported" 0 "Inactive" ;
VAL_ 548 DSP_AdjChimVolSupp_St 3 "NotUsed_1" 2 "Supported" 1 "NotSupported" 0 "Inactive" ;
VAL_ 548 DSP_AdjChimVolSupp2_St 3 "NotUsed_1" 2 "Supported" 1 "NotSupported" 0 "Inactive" ;
VAL_ 548 DSP_AHU_ChmTstT 31 "NotUsed_22" 30 "NotUsed_21" 29 "NotUsed_20" 28 "NotUsed_19" 27 "NotUsed_18" 26 "NotUsed_17" 25 "NotUsed_16" 24 "NotUsed_15" 23 "NotUsed_14" 22 "NotUsed_13" 21 "NotUsed_12" 20 "NotUsed_11" 19 "NotUsed_10" 18 "NotUsed_9" 17 "NotUsed_8" 16 "NotUsed_7" 15 "NotUsed_6" 14 "NotUsed_5" 13 "NotUsed_4" 12 "NotUsed_3" 11 "NotUsed_2" 10 "NotUsed_1" 9 "Crank_3" 8 "NotUsed" 7 "Running_2" 6 "IgnitionOn_2" 5 "PostIgnition_1" 4 "Accessory_1" 3 "PostAccessory_0" 2 "KeyApproved_0" 1 "KeyRecentlyOut" 0 "KeyOut" ;
VAL_ 548 DspDgtlChime_D_Stat 3 "NotUsed" 2 "Supported" 1 "NotSupported" 0 "Inactive" ;
VAL_ 404 Dsp_LangUpdate_Rsp 2 "Language_Not_Supported" 1 "Language_Updated" 0 "Inactive" ;
VAL_ 1008 SelectedNumOfPresets 31 "Reserved" 30 "Preset30" 4 "Preset4" 3 "Preset3" 2 "Preset2" 1 "Preset1" 0 "Inactive" ;
VAL_ 1008 MultimediaSrc_D_Stat 10 "BaiduCarlife" 9 "AndroidAuto" 8 "CarPlay" 7 "AppLink" 6 "LineIn" 5 "BluetoothAudio" 4 "WiFi" 3 "SdCard" 2 "Usb" 1 "AudioVideoln" 0 "Null" ;
VAL_ 1008 MultimediaShuf_D_Stat 3 "NotUsed" 2 "On" 1 "Off" 0 "Null" ;
VAL_ 1008 MultimediaRepeat_D_Stat 4 "NotUsed" 3 "RepeatOn" 2 "RepeatOff" 1 "RepeatOne" 0 "Null" ;
VAL_ 1008 CPM_MediaPlayerSrc_St 31 "Empty" 30 "Reserved14" 29 "Reserved13" 28 "Reserved12" 27 "Reserved11" 26 "Reserved10" 25 "Reserved9" 24 "Reserved8" 23 "Reserved7" 22 "Reserved6" 21 "Reserved5" 20 "Reserved4" 19 "Reserved3" 18 "Reserved2" 17 "Reserved1" 16 "SourceID16" 15 "SourceID15" 14 "SourceID14" 13 "SourceID13" 12 "SourceID12" 11 "SourceID11" 10 "SourceID10" 9 "SourceID9" 8 "SourceID8" 7 "SourceID7" 6 "SourceID6" 5 "SourceID5" 4 "SourceID4" 3 "SourceID3" 2 "SourceID2" 1 "SourceID1" 0 "NoDataExists" ;
VAL_ 547 Audio_Amp_St 3 "On" 2 "Partial_Amp" 1 "Off" 0 "NoDataExists" ;
VAL_ 547 Chime_Alert_Chan2 2 "Reserved" 1 "Mute" 0 "Inactive" ;
VAL_ 547 AHU_Chime2_Active 63 "Chime_62" 4 "Chime_3" 3 "Chime_2" 2 "Chime_1" 1 "NoChime" 0 "Inactive" ;
VAL_ 547 AHU_Chime2_Not_Recognized 0 "Inactive" 1 "Chime_Not_Recognized" ;
VAL_ 547 Chime_Alert_Chan 2 "Reserved" 1 "Mute" 0 "Inactive" ;
VAL_ 547 AHU_Alert_Channel1 3 "Reserved" 2 "Muted" 1 "Initialize_for_prompt" 0 "Inactive" ;
VAL_ 547 AHU_Chime_Supported 3 "Not_Used" 2 "Not_Supported" 1 "Supported" 0 "Inactive" ;
VAL_ 547 AHU_Chime_Active 63 "Chime_62" 4 "Chime_3" 3 "Chime_2" 2 "Chime_1" 1 "NoChime" 0 "Inactive" ;
VAL_ 547 AHU_Chime_Not_Recognized 0 "Inactive" 1 "Chime_Not_Recognized" ;
VAL_ 547 ChimeId_No_Stat 255 "Id255" 254 "Id254" 253 "Id253" 252 "Id252" 251 "Id251" 250 "Id250" 249 "Id249" 248 "Id248" 247 "Id247" 246 "Id246" 245 "Id245" 244 "Id244" 243 "Id243" 242 "Id242" 241 "Id241" 240 "Id240" 239 "Id239" 238 "Id238" 237 "Id237" 236 "Id236" 235 "Id235" 234 "Id234" 233 "Id233" 232 "Id232" 231 "Id231" 230 "Id230" 229 "Id229" 228 "Id228" 227 "Id227" 226 "Id226" 225 "Id225" 224 "Id224" 223 "Id223" 222 "Id222" 221 "Id221" 220 "Id220" 219 "Id219" 218 "Id218" 217 "Id217" 216 "Id216" 215 "Id215" 214 "Id214" 213 "Id213" 212 "Id212" 211 "Id211" 210 "Id210" 209 "Id209" 208 "Id208" 207 "Id207" 206 "Id206" 205 "Id205" 204 "Id204" 203 "Id203" 202 "Id202" 201 "Id201" 200 "Id200" 199 "Id199" 198 "Id198" 197 "Id197" 196 "Id196" 195 "Id195" 194 "Id194" 193 "Id193" 192 "Id192" 191 "Id191" 190 "Id190" 189 "Id189" 188 "Id188" 187 "Id187" 186 "Id186" 185 "Id185" 184 "Id184" 183 "Id183" 182 "Id182" 181 "Id181" 180 "Id180" 179 "Id179" 178 "Id178" 177 "Id177" 176 "Id176" 175 "Id175" 174 "Id174" 173 "Id173" 172 "Id172" 171 "Id171" 170 "Id170" 169 "Id169" 168 "Id168" 167 "Id167" 166 "Id166" 165 "Id165" 164 "Id164" 163 "Id163" 162 "Id162" 161 "Id161" 160 "Id160" 159 "Id159" 158 "Id158" 157 "Id157" 156 "Id156" 155 "Id155" 154 "Id154" 153 "Id153" 152 "Id152" 151 "Id151" 150 "Id150" 149 "Id149" 148 "Id148" 147 "Id147" 146 "Id146" 145 "Id145" 144 "Id144" 143 "Id143" 142 "Id142" 141 "Id141" 140 "Id140" 139 "Id139" 138 "Id138" 137 "Id137" 136 "Id136" 135 "Id135" 134 "Id134" 133 "Id133" 132 "Id132" 131 "Id131" 130 "Id130" 129 "Id129" 128 "Id128" 127 "Id127" 126 "Id126" 125 "Id125" 124 "Id124" 123 "Id123" 122 "Id122" 121 "Id121" 120 "Id120" 119 "Id119" 118 "Id118" 117 "Id117" 116 "Id116" 115 "Id115" 114 "Id114" 113 "Id113" 112 "Id112" 111 "Id111" 110 "Id110" 109 "Id109" 108 "Id108" 107 "Id107" 106 "Id106" 105 "Id105" 104 "Id104" 103 "Id103" 102 "Id102" 101 "Id101" 100 "Id100" 99 "Id99" 98 "Id98" 97 "Id97" 96 "Id96" 95 "Id95" 94 "Id94" 93 "Id93" 92 "Id92" 91 "Id91" 90 "Id90" 89 "Id89" 88 "Id88" 87 "Id87" 86 "Id86" 85 "Id85" 84 "Id84" 83 "Id83" 82 "Id82" 81 "Id81" 80 "Id80" 79 "Id79" 78 "Id78" 77 "Id77" 76 "Id76" 75 "Id75" 74 "Id74" 73 "Id73" 72 "Id72" 71 "Id71" 70 "Id70" 69 "Id69" 68 "Id68" 67 "Id67" 66 "Id66" 65 "Id65" 64 "Id64" 63 "Id63" 62 "Id62" 61 "Id61" 60 "Id60" 59 "Id59" 58 "Id58" 57 "Id57" 56 "Id56" 55 "Id55" 54 "Id54" 53 "Id53" 52 "Id52" 51 "Id51" 50 "Id50" 49 "Id49" 48 "Id48" 47 "Id47" 46 "Id46" 45 "Id45" 44 "Id44" 43 "Id43" 42 "Id42" 41 "Id41" 40 "Id40" 39 "Id39" 38 "Id38" 37 "Id37" 36 "Id36" 35 "Id35" 34 "Id34" 33 "Id33" 32 "Id32" 31 "Id31" 30 "Id30" 29 "Id29" 28 "Id28" 27 "Id27" 26 "Id26" 25 "Id25" 24 "Id24" 23 "Id23" 22 "Id22" 21 "Id21" 20 "Id20" 19 "Id19" 18 "Id18" 17 "Id17" 16 "Id16" 15 "Id15" 14 "Id14" 13 "Id13" 12 "Id12" 11 "Id11" 10 "Id10" 9 "Id9" 8 "Id8" 7 "Id7" 6 "Id6" 5 "Id5" 4 "Id4" 3 "Id3" 2 "Id2" 1 "Id1" 0 "Inactive" ;
VAL_ 547 Chime2Id_No_Stat 255 "Id255" 254 "Id254" 253 "Id253" 252 "Id252" 251 "Id251" 250 "Id250" 249 "Id249" 248 "Id248" 247 "Id247" 246 "Id246" 245 "Id245" 244 "Id244" 243 "Id243" 242 "Id242" 241 "Id241" 240 "Id240" 239 "Id239" 238 "Id238" 237 "Id237" 236 "Id236" 235 "Id235" 234 "Id234" 233 "Id233" 232 "Id232" 231 "Id231" 230 "Id230" 229 "Id229" 228 "Id228" 227 "Id227" 226 "Id226" 225 "Id225" 224 "Id224" 223 "Id223" 222 "Id222" 221 "Id221" 220 "Id220" 219 "Id219" 218 "Id218" 217 "Id217" 216 "Id216" 215 "Id215" 214 "Id214" 213 "Id213" 212 "Id212" 211 "Id211" 210 "Id210" 209 "Id209" 208 "Id208" 207 "Id207" 206 "Id206" 205 "Id205" 204 "Id204" 203 "Id203" 202 "Id202" 201 "Id201" 200 "Id200" 199 "Id199" 198 "Id198" 197 "Id197" 196 "Id196" 195 "Id195" 194 "Id194" 193 "Id193" 192 "Id192" 191 "Id191" 190 "Id190" 189 "Id189" 188 "Id188" 187 "Id187" 186 "Id186" 185 "Id185" 184 "Id184" 183 "Id183" 182 "Id182" 181 "Id181" 180 "Id180" 179 "Id179" 178 "Id178" 177 "Id177" 176 "Id176" 175 "Id175" 174 "Id174" 173 "Id173" 172 "Id172" 171 "Id171" 170 "Id170" 169 "Id169" 168 "Id168" 167 "Id167" 166 "Id166" 165 "Id165" 164 "Id164" 163 "Id163" 162 "Id162" 161 "Id161" 160 "Id160" 159 "Id159" 158 "Id158" 157 "Id157" 156 "Id156" 155 "Id155" 154 "Id154" 153 "Id153" 152 "Id152" 151 "Id151" 150 "Id150" 149 "Id149" 148 "Id148" 147 "Id147" 146 "Id146" 145 "Id145" 144 "Id144" 143 "Id143" 142 "Id142" 141 "Id141" 140 "Id140" 139 "Id139" 138 "Id138" 137 "Id137" 136 "Id136" 135 "Id135" 134 "Id134" 133 "Id133" 132 "Id132" 131 "Id131" 130 "Id130" 129 "Id129" 128 "Id128" 127 "Id127" 126 "Id126" 125 "Id125" 124 "Id124" 123 "Id123" 122 "Id122" 121 "Id121" 120 "Id120" 119 "Id119" 118 "Id118" 117 "Id117" 116 "Id116" 115 "Id115" 114 "Id114" 113 "Id113" 112 "Id112" 111 "Id111" 110 "Id110" 109 "Id109" 108 "Id108" 107 "Id107" 106 "Id106" 105 "Id105" 104 "Id104" 103 "Id103" 102 "Id102" 101 "Id101" 100 "Id100" 99 "Id99" 98 "Id98" 97 "Id97" 96 "Id96" 95 "Id95" 94 "Id94" 93 "Id93" 92 "Id92" 91 "Id91" 90 "Id90" 89 "Id89" 88 "Id88" 87 "Id87" 86 "Id86" 85 "Id85" 84 "Id84" 83 "Id83" 82 "Id82" 81 "Id81" 80 "Id80" 79 "Id79" 78 "Id78" 77 "Id77" 76 "Id76" 75 "Id75" 74 "Id74" 73 "Id73" 72 "Id72" 71 "Id71" 70 "Id70" 69 "Id69" 68 "Id68" 67 "Id67" 66 "Id66" 65 "Id65" 64 "Id64" 63 "Id63" 62 "Id62" 61 "Id61" 60 "Id60" 59 "Id59" 58 "Id58" 57 "Id57" 56 "Id56" 55 "Id55" 54 "Id54" 53 "Id53" 52 "Id52" 51 "Id51" 50 "Id50" 49 "Id49" 48 "Id48" 47 "Id47" 46 "Id46" 45 "Id45" 44 "Id44" 43 "Id43" 42 "Id42" 41 "Id41" 40 "Id40" 39 "Id39" 38 "Id38" 37 "Id37" 36 "Id36" 35 "Id35" 34 "Id34" 33 "Id33" 32 "Id32" 31 "Id31" 30 "Id30" 29 "Id29" 28 "Id28" 27 "Id27" 26 "Id26" 25 "Id25" 24 "Id24" 23 "Id23" 22 "Id22" 21 "Id21" 20 "Id20" 19 "Id19" 18 "Id18" 17 "Id17" 16 "Id16" 15 "Id15" 14 "Id14" 13 "Id13" 12 "Id12" 11 "Id11" 10 "Id10" 9 "Id9" 8 "Id8" 7 "Id7" 6 "Id6" 5 "Id5" 4 "Id4" 3 "Id3" 2 "Id2" 1 "Id1" 0 "Inactive" ;
VAL_ 547 AHU_AdjChimVolSupp2_St 3 "NotUsed_1" 2 "Supported" 1 "NotSupported" 0 "Inactive" ;
VAL_ 547 AHU_AdjChimeVolSupp_St 3 "NotUsed_1" 2 "Supported" 1 "NotSupported" 0 "Inactive" ;
VAL_ 547 AhuDgtlChime_D_Stat 3 "NotUsed" 2 "Supported" 1 "NotSupported" 0 "Inactive" ;
VAL_ 732 ACU_CurrItemsInFMSL_St 255 "NoValidPreset" 0 "Invalid" ;
VAL_ 732 ACU_FunctionStatus_St 7 "RemoveDisc" 0 "Invalid" 1 "Reading" 2 "Loading" 3 "Loaded" 4 "Insert" 5 "PreparingToEject" 6 "Ejecting" ;
VAL_ 732 ACU_CurrFMSLPreset_St 255 "NoValidPreset" 0 "Invalid" ;
VAL_ 732 ACU_CurrPreset2_St 31 "NoActivePreset" 0 "Invalid" ;
VAL_ 732 ACU_StorePreset_St 31 "NotStoring" 0 "Invalid" ;
VAL_ 732 ACU_VoiceCommand_St 2 "NotOk" 1 "Ok" 0 "Invalid" ;
VAL_ 732 ACU_CurrMixPreset_St 31 "NoActivePreset" 0 "Invalid" ;
VAL_ 728 PrplSnd_D_Stat 3 "NotUsed" 2 "Enabled" 1 "Disabled" 0 "Null" ;
VAL_ 728 ACU_AuxVolume_Up 1 "Update" 0 "NoUpdate" ;
VAL_ 728 ACU_RadioSeekMode_St 14 "PISeek" 0 "Invalid" 1 "SeekOff" 2 "AutoUp" 3 "AutoDown" 4 "ManSingleStepUp" 5 "ManSingleStepDown" 6 "ContManualUp" 7 "ContManualDown" 8 "ScanUp" 9 "ScanDown" 10 "PtySeekUp" 11 "PtySeekDown" 12 "Autostore" 13 "TpSeek" ;
VAL_ 728 ACU_Volume_Up 1 "Update" 0 "NoUpdate" ;
VAL_ 757 SdarsAudioRtng_D_Stat 3 "NotUsed" 2 "APIMStereoOut" 1 "X40l2SStereoOut" 0 "NotDetermined" ;
VAL_ 757 SpkrStdRight_D_Stat 3 "Faulty" 2 "Normal" 1 "NotPresent" 0 "Null" ;
VAL_ 757 SpkrStdLeft_D_Stat 3 "Faulty" 2 "Normal" 1 "NotPresent" 0 "Null" ;
VAL_ 757 SpkrStdCntr_D_Stat 3 "Faulty" 2 "Normal" 1 "NotPresent" 0 "Null" ;
VAL_ 757 SDARS_ChipControl_St 7 "NotUsed_2" 6 "NotUsed_1" 5 "Ready" 4 "ResetInProgress" 3 "PowerDownInProgress" 2 "PowerUpInProgress" 1 "Off" 0 "Null" ;
VAL_ 757 ACU_AutoStoreResult_St 2 "No_Station_Found" 1 "Inactive" 0 "Invalid" ;
VAL_ 757 ACU_DirectTune_St 2 "Valid_Station" 1 "Invalid_Station" 0 "Invalid" ;
VAL_ 757 ACU_RadioSeekMode2_St 16 "ContAutoDown" 15 "ContAutoUp" 14 "PISeek" 13 "TpSeek" 12 "Autostore" 11 "PtySeekDown" 10 "PtySeekUp" 9 "ScanDown" 8 "ScanUp" 7 "ContManualDown" 6 "ContManualUp" 5 "ManSingleStepDown" 4 "ManSingleStepUp" 3 "AutoDown" 2 "AutoUp" 1 "SeekOff" 0 "Invalid" ;
VAL_ 757 ACU_CurrTUBand_St 10 "SAT2" 9 "SAT1" 8 "DAB2" 7 "DAB1" 6 "Fm3" 5 "AmAst" 4 "Am" 3 "FmAst" 2 "Fm2" 1 "Fm1" 0 "Invalid" 13 "reserved1" 15 "reserved_last" 12 "DAB3" 11 "SAT3" ;
VAL_ 734 ACU_ActServiceLink_St 3 "reserved" 2 "FM2DAB" 1 "DAB2FM" 0 "Invalid" ;
VAL_ 734 ACU_CurrTUDRService2_St 7 "last_reserved" 5 "reserved" 4 "DabNotAvailable" 3 "ServiceAvailable" 2 "ServiceNotAvailable" 1 "SyncEnsemble" 0 "Invalid" ;
VAL_ 734 ACU_ComTUSIDValid_St 1 "Validation" 0 "Invalid" ;
VAL_ 734 ACU_CurrTUDRService_St 3 "ServiceAvailable" 2 "ServiceNotAvailable" 1 "SyncEnsemble" 0 "Invalid" ;
VAL_ 734 ACU_CurrTURadioBand_St 12 "reserved" 11 "SAT3" 10 "SAT2" 15 "reserved_last" 9 "SAT1" 8 "DAB2" 7 "DAB1" 6 "Fm3" 5 "AmAst" 4 "Am" 3 "FmAst" 2 "Fm2" 1 "Fm1" 0 "Invalid" ;
VAL_ 734 ACU_CurrTUServiceLink_St 3 "reserved" 2 "Inactive" 1 "Active" 0 "Invalid" ;
VAL_ 759 Avail_HD_Chan_Valid 1 "Valid" 0 "Invalid" ;
VAL_ 759 Avail_HD_Chan_St_7 1 "Available" 0 "NotAvailable" ;
VAL_ 759 Avail_HD_Chan_St_6 1 "Available" 0 "NotAvailable" ;
VAL_ 759 Avail_HD_Chan_St_5 1 "Available" 0 "NotAvailable" ;
VAL_ 759 Avail_HD_Chan_St_4 1 "Available" 0 "NotAvailable" ;
VAL_ 759 Avail_HD_Chan_St_3 1 "Available" 0 "NotAvailable" ;
VAL_ 759 Avail_HD_Chan_St_2 1 "Available" 0 "NotAvailable" ;
VAL_ 759 Avail_HD_Chan_St_1 1 "Available" 0 "NotAvailable" ;
VAL_ 759 ACM_StationListScanSt 1 "Scan_Cancelled" ;
VAL_ 759 ACM_TagMode 2 "On" 1 "Off" 0 "Inactive" ;
VAL_ 759 ACM_RBDSMode 2 "On" 1 "Off" 0 "Inactive" ;
VAL_ 759 NumofHDMulticastChans_St 7 "Multicast_Available_7" 6 "Multicast_Available_6" 5 "Multicast_Available_5" 4 "Multicast_Available_4" 3 "Multicast_Available_3" 2 "Multicast_Available_2" 1 "Multicast_Available_1" 0 "zero" ;
VAL_ 759 ACM_HDModeStatus 2 "On" 1 "Off" 0 "Inactive" ;
VAL_ 759 ACM_HDChanStatus 4 "Not_Found" 3 "Not_Multicast" 2 "Acquired" 1 "Acquiring" ;
VAL_ 759 ACM_CurrentHDMulticast_St 7 "7" 6 "6" 5 "5" 4 "4" 3 "3" 2 "2" 1 "1" 0 "0" ;
VAL_ 144 TimeAdjustRequest 0 "NoTimeAdjustRequest" 1 "TimeAdjustRequest" ;
VAL_ 144 DateAdjustRequest 0 "NoDateAdjustRequest" 1 "DateAdjustRequest" ;
VAL_ 851 ConsLongTerm_No_Dsply 4095 "Faulty" 4094 "No_Data_Exists" ;
VAL_ 851 ConsUnitIPC_D_Dsply 15 "Reserved_15" 14 "Reserved_14" 13 "Reserved_13" 12 "Reserved_12" 11 "MPG_Hi-Res" 10 "miles_gallon__UK_" 9 "km_L_" 8 "Liters___100_km" 7 "Miles___Gallon" 6 "Whr___km_" 5 "Whr___mi_" 4 "miles_gallon__UK_" 2 "Liters___100_km" 1 "Miles___Gallon__US_" 0 "Invalid" 3 "km_L" ;
VAL_ 851 ConsAvgTrip_No_Dsply 4095 "Faulty" 4094 "No_Data_Exists" ;
VAL_ 792 ElTrip_L_Dsply 65535 "Fault" 65534 "No_Data_Exists" ;
VAL_ 792 ElLongTerm_L_Dsply 16777215 "Fault" 16777214 "No_Data_Exists" ;
VAL_ 787 VehElSurpStat_L_Dsply 8191 "Faulty" 8190 "Data_Not_Available" ;
VAL_ 787 TripSum_E_Dsply 511 "_Faulty" 510 "Data_Not_Available" ;
VAL_ 787 TripSum_L_Dsply 65535 "Faulty" 65534 "Data_Not_Available__" ;
VAL_ 504 Mc_AudioSourceSel_Rq 4 "Reserved" 5 "SDcard" 3 "USB" 2 "BTAudio" 1 "CD" 0 "Inactive" ;
VAL_ 504 Mc_CutItem_Rq 3 "Inactive" 2 "ThreeQuarterFromBeginOneQ" 1 "End" 0 "Beginning" ;
VAL_ 410 MyKey_e911Override_St 2 "On" 1 "Off" 0 "No_Data_Exists" ;
VAL_ 410 DoNotDisturbOveride_St 2 "On" 1 "Off" 0 "No_Data_Exists" ;
VAL_ 1124 GPS_Vdop 31 "Invalid" 30 "Unknown" ;
VAL_ 1124 GPS_Speed 255 "Invalid" 254 "Unknown" ;
VAL_ 1124 GPS_Sat_num_in_view 31 "Invalid" 30 "Unknown" ;
VAL_ 1124 GPS_MSL_altitude 4095 "Fault" 4094 "Unknown" ;
VAL_ 1124 GPS_Heading 65535 "Fault" 65534 "Unknown" ;
VAL_ 1124 GPS_Hdop 31 "Invalid" 30 "Unknown" ;
VAL_ 1124 GPS_dimension 2 "_3D" 1 "_2D" 0 "No_Fix" ;
VAL_ 1123 GpsUtcYr_No_Actl 31 "Fault" ;
VAL_ 1123 GpsUtcMnth_No_Actl 15 "Fault" ;
VAL_ 1123 GPS_UTC_seconds 63 "Fault" 62 "Unknown" ;
VAL_ 1123 GPS_UTC_minutes 63 "Fault" 62 "Unknown" ;
VAL_ 1123 GPS_UTC_hours 31 "Invalid" 30 "Unknown" ;
VAL_ 1123 GPS_Pdop 31 "Invalid" 30 "Unknown" ;
VAL_ 1123 GPS_Compass_direction 7 "NorthWest" 6 "West" 5 "SouthWest" 4 "South" 3 "SouthEast" 2 "East" 1 "NorthEast" 0 "North" ;
VAL_ 1123 GPS_Actual_vs_Infer_pos 1 "Inferred_Position" 0 "Actual_Postition" ;
VAL_ 1123 Gps_B_Falt 1 "Yes" 0 "No" ;
VAL_ 1122 GpsHsphLongEast_D_Actl 0 "Invalid" 1 "Eastern" 2 "Western" 3 "Fault" ;
VAL_ 1122 GpsHsphLattSth_D_Actl 3 "Fault" 2 "Northern" 1 "Southern" 0 "Invalid" ;
VAL_ 1122 GPS_Longitude_Minutes 63 "Fault" 62 "Unknown" ;
VAL_ 1122 GPS_Longitude_Min_dec 16383 "Invalid" 16382 "Unknown" ;
VAL_ 1122 GPS_Longitude_Degrees 511 "Fault" 510 "Unknown" ;
VAL_ 1122 GPS_Latitude_Minutes 63 "Fault" 62 "Unknown" ;
VAL_ 1122 GPS_Latitude_Min_dec 16383 "Invalid" 16382 "Unknown" ;
VAL_ 1122 GPS_Latitude_Degrees 255 "Invalid" 254 "Unknown" ;
VAL_ 1131 EsaOn_B_Stat_UB 1 "Fresh_data" 0 "Unchanged_data" ;
VAL_ 1131 EsaOn_B_Stat 1 "On" 0 "Off" ;
VAL_ 1131 WiprFrontSwtch_D_Stat 15 "NotUsed6" 14 "NotUsed5" 13 "NotUsed4" 12 "NotUsed3" 11 "NotUsed2" 10 "NotUsed1" 9 "PositionNotDetermined" 8 "High" 7 "Low" 6 "Position6" 5 "Position5" 4 "Position4" 3 "Position3" 2 "Position2" 1 "Position1" 0 "Off" ;
VAL_ 1131 HeadLghtHiOn_B_StatAhb_UB 1 "Fresh_data" 0 "Unchanged_data" ;
VAL_ 1131 HeadLghtHiOn_B_StatAhb 1 "On" 0 "Off" ;
VAL_ 1131 AhbStat_B_Dsply_UB 1 "Fresh_data" 0 "Unchanged_data" ;
VAL_ 1131 AhbStat_B_Dsply 1 "On" 0 "Off" ;
VAL_ 1131 WiprFrontSwtch_D_Stat_UB 1 "Fresh_data" 0 "Unchanged_data" ;
VAL_ 1131 RearDiffSrvcRqd_B_Rq_UB 1 "Fresh_data" 0 "Unchanged_data" ;
VAL_ 1131 PtLatchActv_B_RqBcm_UB 1 "Fresh_data" 0 "Unchanged_data" ;
VAL_ 1131 RearDiffSrvcRqd_B_Rq 1 "On" 0 "Off" ;
VAL_ 1131 PtLatchActv_B_RqBcm 1 "On" 0 "Off" ;
VAL_ 1136 ActvFrontSteMsgTxt_D_Rq_UB 1 "Fresh_data" 0 "Unchanged_data" ;
VAL_ 1136 ActvFrontSteMsgTxt_D_Rq 7 "Message7" 6 "Message6" 5 "Message5" 4 "Message4" 3 "Message3" 2 "Message2" 1 "Message1" 0 "NoMessage" ;
VAL_ 1136 GboxOil_Te_Actl_UB 1 "Fresh_data" 0 "Unchanged_data" ;
VAL_ 1136 GboxOil_Te_Actl 255 "Faulty" 254 "NoDataExists" ;
VAL_ 1136 EngOff_T_Actl_UB 1 "Fresh_data" 0 "Unchanged_data" ;
VAL_ 1136 EngOff_T_Actl 65535 "Invalid" ;
VAL_ 1136 AirSuspMsgTxt_D_Rq_UB 1 "Fresh_data" 0 "Unchanged_data" ;
VAL_ 1136 AirSusp_D_Stat_UB 1 "Fresh_data" 0 "Unchanged_data" ;
VAL_ 1136 AirSusp_D_Stat 3 "NotUsed" 2 "On" 1 "Off" 0 "Null" ;
VAL_ 1136 AirSuspMsgTxt_D_Rq 3 "NotUsed" 2 "Faulty" 1 "Override" 0 "NoMessage" ;
VAL_ 1136 BrkLineLck_D_Stat_UB 1 "Fresh_data" 0 "Unchanged_data" ;
VAL_ 1136 BrkLineLck_D_Stat 7 "NotUsed_3" 6 "NotUsed_2" 5 "NotUsed_1" 4 "NotAvailable" 3 "Off" 2 "Engaged" 1 "Initiated" 0 "Available" ;
VAL_ 1136 SnowPlowMde_B_Enbl 1 "Enable" 0 "Disable" ;
VAL_ 1136 SnowPlowMde_B_Enbl_UB 1 "Fresh_data" 0 "Unchanged_data" ;
VAL_ 1106 TrlrSnsId_No_Actl -1 "Faulty_FFFFFFFFFFFF" -2 "NoDataExists_FFFFFFFFFFFE" ;
VAL_ 1086 AwdPtu_Te_Actl 255 "Faulty" ;
VAL_ 1086 FuelPumpPwr_B_Rq 1 "On" 0 "Off" ;
VAL_ 1086 ElLoadCtl_D_Rq 7 "Unused3" 6 "Unused2" 5 "Unused1" 4 "HoldAllDrvrInvisibleLoads" 3 "StdDriverInvisibleLoadsOn" 2 "AllDriverInvisibleLoadsOn" 1 "All_Possible_Loads_Off" 0 "No_Request" ;
VAL_ 817 ChildLckMde_B_Stat 1 "Enable" 0 "Disable" ;
VAL_ 817 VehLckInd_D_Rq 3 "NotUsed" 2 "On_Day" 1 "On_Night" 0 "Off" ;
VAL_ 817 DrTgateOpen_B_Rq 1 "Open" 0 "Null" ;
VAL_ 817 DrTgateExtSwMde_B_Stat 1 "Enable" 0 "Disable" ;
VAL_ 817 Remote_Device_Feedback 7 "Unused3" 6 "Unused2" 5 "Unused1" 4 "Shutdown" 3 "Running" 2 "Starting" 1 "Acknowledge" 0 "Null" ;
VAL_ 817 Veh_Lock_Requestor 31 "Walk_Away_Locking" 30 "Remote_Park_Assist" 29 "DoorsOffToOn_Smart_Unlock" 28 "Rgtm_Shutlock_Switch" 27 "Boundary_Alert" 26 "Transit_Vehicle_Relock" 25 "Transit_Cargo_Relock" 24 "Transit_Ajar_Lock" 23 "Diagnostics" 22 "Console_Lock" 21 "Child_Lock" 20 "Double_Lock" 19 "Passive_Pasenger" 18 "Passive_Driver" 17 "Slam_Lock_Protect" 16 "SYNC" 15 "Passport" 14 "Passive_Smart_Unlock" 13 "Autorelock" 12 "RemoteStart" 0 "Null" 1 "Autolock" 11 "Smart_Unlock" 10 "Sliding_Door" 9 "Passive" 8 "Remote" 7 "Programming" 6 "Powerslide" 5 "Keypad" 4 "Key_Cylinder" 3 "Interior" 2 "Auto_Unlock" ;
VAL_ 817 R_Pwr_Sliding_Dr_Rqst 1 "Active" 0 "Null" ;
VAL_ 817 Power_Liftgate_Rqst 1 "Active" 0 "Null" ;
VAL_ 817 Power_Decklid_Rqst 1 "Active" 0 "Null" ;
VAL_ 817 L_Pwr_Sliding_Dr_Rqst 1 "Active" 0 "Null" ;
VAL_ 817 Veh_Lock_Sub_Id 15 "Unused7" 14 "Unused6" 13 "Unused5" 12 "Unused4" 11 "Unused3" 10 "Unused2" 9 "Unused1" 8 "Customer_8" 7 "Customer_7" 6 "Customer_6" 5 "Customer_5" 4 "Customer_4" 3 "Customer_3" 2 "Customer_2" 1 "Customer_1" 0 "Null" ;
VAL_ 817 Veh_Lock_Status 3 "UNLOCK_DRV" 2 "UNLOCK_ALL" 1 "LOCK_ALL" 0 "LOCK_DBL" ;
VAL_ 817 ChildLck_D_Dsply 3 "NOT_SUPPORTED" 2 "ERROR" 1 "CHILD_UNLOCK" 0 "CHILD_LOCK" ;
VAL_ 817 WindowLockout_B_Stat 1 "Locked" 0 "Unlock" ;
VAL_ 817 Lockmsgtxt_D_Rq 7 "MSG7" 6 "MSG6" 5 "MSG5" 4 "MSG4" 3 "MSG3" 2 "MSG2" 1 "MSG1" 0 "NO_WARNING" ;
VAL_ 817 FobComm_D_Stat 3 "NotUsed" 2 "RemEngStartOK" 1 "RemEngStartFail" 0 "Null" ;
VAL_ 817 LockInhibit 1 "Inhibit" 0 "No_Inhibit" ;
VAL_ 611 AwdTerrMdeChng_D_Rdy 7 "Fault" 6 "Undefined_2" 5 "Undefined_1" 4 "ModeUnavailDrInputRqd" 3 "SpOpModes_NotSupported" 2 "ModeUnavailDynamicCond" 1 "Module_In_Initialization" 0 "Mode_Change_Available" ;
VAL_ 611 AwdTerrMde_D_Actl 7 "Fail_Safe_Default" 6 "Dynamic_Mode" 5 "Rock_Crawl_Mode" 4 "Mud_Ruts_Mode" 3 "Sand_Mode" 2 "Undefined" 1 "Low_Mu_Mode" 0 "Special_Operating_Mode_Off" ;
VAL_ 611 AwdSys_D_Stat 3 "Faulty" 2 "NotUsed" 1 "_4x4_L_H_Active" 0 "_4x4_L_H_Inactive" ;
VAL_ 611 AwdStat_D_RqDsply 31 "Rear_Diff_Lock_Not_Avail" 30 "_4wd_Lock_Required" 29 "Cfg_Perf_Redc_See_Manual" 28 "To_Engage_4x4_Release_Aped" 27 "To_Engage_4x4_Slow_To_3MPH" 26 "Shift_To_Neutral" 25 "Lkr_Mode_Unavail_TMS" 24 " _4x4_Mode_Unavail_TMS" 23 "Out_of_4Low_Crawl" 22 "AWD_PTU_Oil_Changed" 21 "Change_AWD_PTU_Oil" 20 "Neutral_Tow_Disabled" 19 "Neutral_Tow_Enabled" 18 "AWD_OFF" 17 "_4x4_Off_Road_Speed" 16 "_4x4_Extreme_Off_Road_Mode" 15 "_4x4_Exiting_Off_Road" 14 "_4x4_Off_Road_Mode" 10 "_4x4_Locked_Temporarily" 9 "Shift_In_Progress" 13 "Blocked_Shift_Assist" 12 "_4x4_Auto_Restored" 11 "_4x4_Disabled_Temporarily" 7 "Out_of_4Low__Neutral" 6 "Out_of_4Low__Brake" 5 "Out_of_4Low__Speed" 4 "Into_4Low__Clutch" 3 "Into_4Low__Neutral" 2 "Into_4Low__Brake" 1 "Into_4Low__Speed" 0 "Normal__No_Message" 8 "Out_of_4Low__Clutch" ;
VAL_ 611 AwdLck_D_Stat 9 "Undefined" 8 "Under_External_Torque_Ctrl" 7 "Torque_Limited_by_Cmd" 6 "Fully_Locked_by_Cmd" 5 "Disabled" 4 "Warning" 3 "Fault" 2 "Inactive" 1 "Completely_Opened_by_Cmd" 0 "OK" ;
VAL_ 611 AwdSrvcRqd_B_Rq 1 "On" 0 "Off" ;
VAL_ 611 AwdLck_Tq_Rq 4095 "Fault" 4094 "Unknown" ;
VAL_ 611 AwdOffRoadMode_D_Stats 3 "Invalid" 2 "Extreme_Off_Road" 1 "Off_Road" 0 "Normal_Mode" ;
VAL_ 611 AwdLoLamp_D_RqDsply 3 "Not_Used" 2 "Flash" 1 "On" 0 "Off" ;
VAL_ 611 AwdHiLamp_D_RqDsply 3 "Not_Used" 2 "Flash" 1 "On" 0 "Off" ;
VAL_ 611 AwdAutoLamp_D_RqDsply 3 "Not_Used" 2 "Flash" 1 "On" 0 "Off" ;
VAL_ 611 Awd2wdLamp_D_RqDsply 3 "Not_Used" 2 "Flash" 1 "On" 0 "Off" ;
VAL_ 611 AwdRnge_D_Actl 7 "Unknown" 6 "High_Range_2wd" 5 "High_Range_Auto" 4 "High_Range_Locked" 3 "Neutral" 2 "Low_Range_2wd" 1 "Low_Range_Auto" 0 "Low_Range_Locked" ;
VAL_ 611 NtrlTowAvail_B_Stat 1 "Available" 0 "NotAvailable" ;
VAL_ 611 AwdDrvMde_D_Stat 7 "Faulty" 6 "NotAvailable" 5 "RockCrawl" 4 "Baja" 3 "MudAndSand" 2 "Weather" 1 "Sport" 0 "Normal" ;
VAL_ 611 SelDrvMdeAwd_D_Stat 0 "NotAvailable" 1 "Available" 2 "TemporarilyNotAvailable" 3 "Faulty" ;
